VERSION ""

NS_ :

BS_:

BU_:

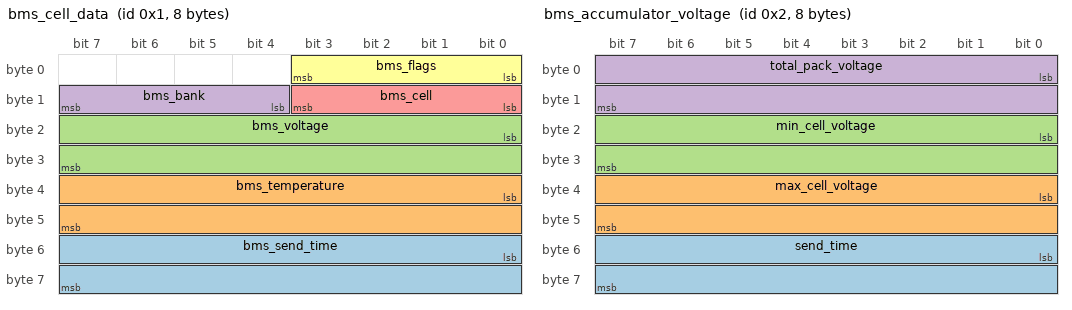
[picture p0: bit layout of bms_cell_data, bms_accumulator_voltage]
BO_ 1 bms_cell_data: 8 Vector__XXX
 SG_ bms_send_time : 48|16@1+ (1,0) [0|0] "" Vector__XXX
 SG_ bms_temperature : 32|16@1- (1,0) [0|0] "" Vector__XXX
 SG_ bms_voltage : 16|16@1+ (1,0) [0|0] "" Vector__XXX
 SG_ bms_bank : 12|4@1+ (1,0) [0|0] "" Vector__XXX
 SG_ bms_cell : 8|4@1+ (1,0) [0|0] "" Vector__XXX
 SG_ bms_flags : 0|4@1+ (1,0) [0|0] "" Vector__XXX

BO_ 2 bms_accumulator_voltage: 8 Vector__XXX
 SG_ send_time : 48|16@1+ (1,0) [0|0] "" Vector__XXX
 SG_ max_cell_voltage : 32|16@1+ (1,0) [0|0] "" Vector__XXX
 SG_ min_cell_voltage : 16|16@1+ (1,0) [0|0] "" Vector__XXX
 SG_ total_pack_voltage : 0|16@1+ (1,0) [0|0] "" Vector__XXX

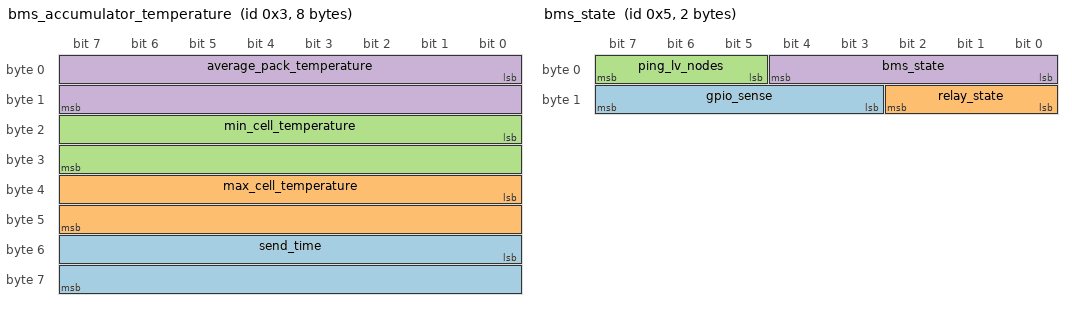
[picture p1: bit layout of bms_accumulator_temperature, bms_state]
BO_ 3 bms_accumulator_temperature: 8 Vector__XXX
 SG_ send_time : 48|16@1+ (1,0) [0|0] "" Vector__XXX
 SG_ max_cell_temperature : 32|16@1- (1,0) [0|0] "" Vector__XXX
 SG_ min_cell_temperature : 16|16@1- (1,0) [0|0] "" Vector__XXX
 SG_ average_pack_temperature : 0|16@1- (1,0) [0|0] "" Vector__XXX

BO_ 4 accumulator_faults: 1 Vector__XXX
 SG_ imd_fault : 1|1@1+ (1,0) [0|0] "" Vector__XXX
 SG_ bms_fault : 0|1@1+ (1,0) [0|0] "" Vector__XXX

BO_ 5 bms_state: 2 Vector__XXX
 SG_ gpio_sense : 11|5@1+ (1,0) [0|0] "" Vector__XXX
 SG_ relay_state : 8|3@1+ (1,0) [0|0] "" Vector__XXX
 SG_ ping_lv_nodes : 5|3@1+ (1,0) [0|0] "" Vector__XXX
 SG_ bms_state : 0|5@1+ (1,0) [0|0] "" Vector__XXX

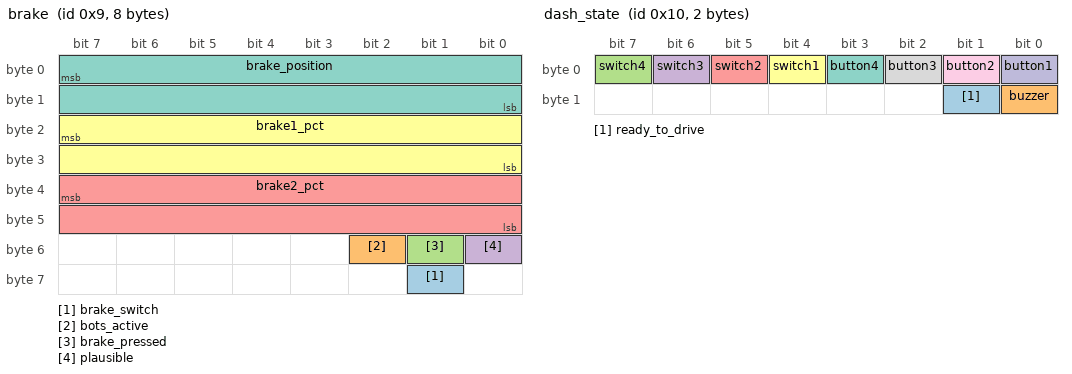
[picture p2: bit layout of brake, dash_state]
BO_ 9 brake: 8 Vector__XXX
 SG_ brake_switch : 57|1@1+ (1,0) [0|0] "" Vector__XXX
 SG_ bots_active : 50|1@1+ (1,0) [0|0] "" Vector__XXX
 SG_ brake_pressed : 49|1@1+ (1,0) [0|0] "" Vector__XXX
 SG_ plausible : 48|1@1+ (1,0) [0|0] "" Vector__XXX
 SG_ brake2_pct : 39|16@0+ (0.01,0) [0|0] "%" Vector__XXX
 SG_ brake1_pct : 23|16@0+ (0.01,0) [0|0] "%" Vector__XXX
 SG_ brake_position : 7|16@0+ (0.01,0) [0|0] "%" Vector__XXX

BO_ 10 bspd_state: 1 Vector__XXX
 SG_ bspd_state : 0|8@1+ (1,0) [0|0] "" Vector__XXX

BO_ 11 res_state: 2 Vector__XXX
 SG_ res_state : 0|8@1+ (1,0) [0|0] "" Vector__XXX

BO_ 16 dash_state: 2 Vector__XXX
 SG_ ready_to_drive : 9|1@1+ (1,0) [0|0] "" Vector__XXX
 SG_ buzzer : 8|1@1+ (1,0) [0|0] "" Vector__XXX
 SG_ switch4 : 7|1@1+ (1,0) [0|0] "" Vector__XXX
 SG_ switch3 : 6|1@1+ (1,0) [0|0] "" Vector__XXX
 SG_ switch2 : 5|1@1+ (1,0) [0|0] "" Vector__XXX
 SG_ switch1 : 4|1@1+ (1,0) [0|0] "" Vector__XXX
 SG_ button4 : 3|1@1+ (1,0) [0|0] "" Vector__XXX
 SG_ button3 : 2|1@1+ (1,0) [0|0] "" Vector__XXX
 SG_ button2 : 1|1@1+ (1,0) [0|0] "" Vector__XXX
 SG_ button1 : 0|1@1+ (1,0) [0|0] "" Vector__XXX

BO_ 22 lvpdb_lv_24v_bus_and_12v_bus_vol: 4 Vector__XXX
 SG_ lv_12v_voltage : 16|16@1+ (1,0) [0|0] "" Vector__XXX
 SG_ lv_24v_voltage : 0|16@1+ (1,0) [0|0] "" Vector__XXX

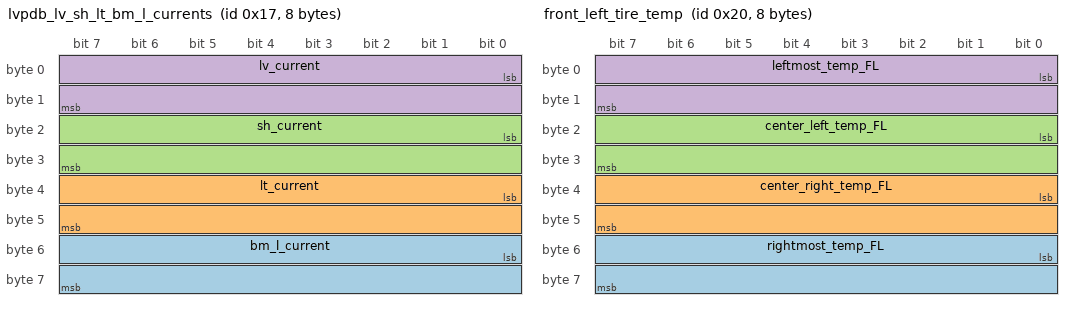
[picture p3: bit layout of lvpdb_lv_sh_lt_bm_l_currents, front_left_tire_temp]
BO_ 23 lvpdb_lv_sh_lt_bm_l_currents: 8 Vector__XXX
 SG_ bm_l_current : 48|16@1+ (1,0) [0|0] "" Vector__XXX
 SG_ lt_current : 32|16@1+ (1,0) [0|0] "" Vector__XXX
 SG_ sh_current : 16|16@1+ (1,0) [0|0] "" Vector__XXX
 SG_ lv_current : 0|16@1+ (1,0) [0|0] "" Vector__XXX

BO_ 24 lvpdb_sm_af1_af2_cp_rf_currents: 8 Vector__XXX
 SG_ cp_rf_current : 32|16@1+ (1,0) [0|0] "" Vector__XXX
 SG_ af1_af2_current : 16|16@1+ (1,0) [0|0] "" Vector__XXX
 SG_ sm_current : 0|16@1+ (1,0) [0|0] "" Vector__XXX

BO_ 30 linear_potentiometer_front: 4 Vector__XXX
 SG_ linear_potentiometer_2_front : 16|16@1+ (1,0) [0|0] "" Vector__XXX
 SG_ linear_potentiometer_1_front : 0|16@1+ (1,0) [0|0] "" Vector__XXX

BO_ 31 linear_potentiometer_rear: 4 Vector__XXX
 SG_ linear_potentiometer_2_rear : 16|16@1+ (1,0) [0|0] "" Vector__XXX
 SG_ linear_potentiometer_1_rear : 0|16@1+ (1,0) [0|0] "" Vector__XXX

BO_ 32 front_left_tire_temp: 8 Vector__XXX
 SG_ rightmost_temp_FL : 48|16@1+ (1,0) [0|0] "" Vector__XXX
 SG_ center_right_temp_FL : 32|16@1+ (1,0) [0|0] "" Vector__XXX
 SG_ center_left_temp_FL : 16|16@1+ (1,0) [0|0] "" Vector__XXX
 SG_ leftmost_temp_FL : 0|16@1+ (1,0) [0|0] "" Vector__XXX

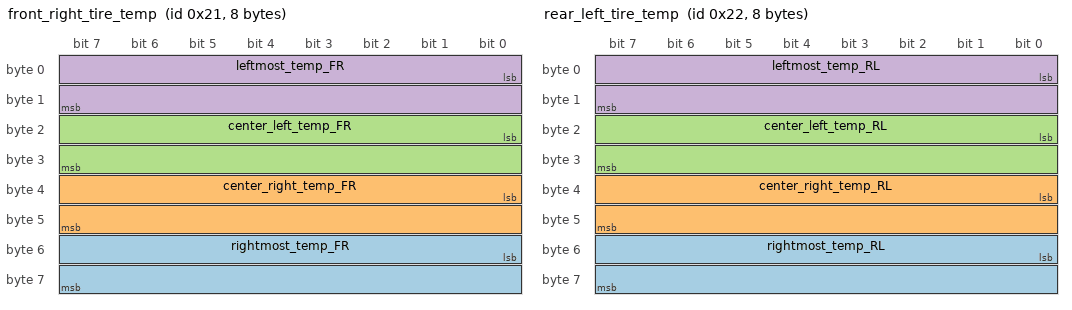
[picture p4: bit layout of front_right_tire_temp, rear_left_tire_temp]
BO_ 33 front_right_tire_temp: 8 Vector__XXX
 SG_ rightmost_temp_FR : 48|16@1+ (1,0) [0|0] "" Vector__XXX
 SG_ center_right_temp_FR : 32|16@1+ (1,0) [0|0] "" Vector__XXX
 SG_ center_left_temp_FR : 16|16@1+ (1,0) [0|0] "" Vector__XXX
 SG_ leftmost_temp_FR : 0|16@1+ (1,0) [0|0] "" Vector__XXX

BO_ 34 rear_left_tire_temp: 8 Vector__XXX
 SG_ rightmost_temp_RL : 48|16@1+ (1,0) [0|0] "" Vector__XXX
 SG_ center_right_temp_RL : 32|16@1+ (1,0) [0|0] "" Vector__XXX
 SG_ center_left_temp_RL : 16|16@1+ (1,0) [0|0] "" Vector__XXX
 SG_ leftmost_temp_RL : 0|16@1+ (1,0) [0|0] "" Vector__XXX

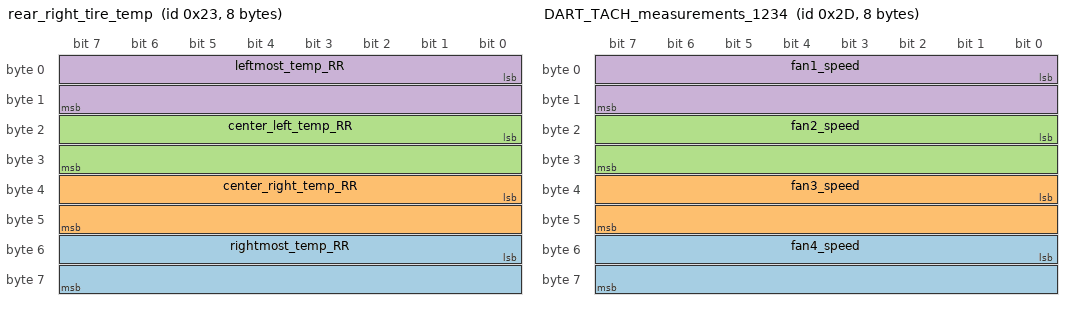
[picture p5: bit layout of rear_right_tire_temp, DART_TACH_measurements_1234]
BO_ 35 rear_right_tire_temp: 8 Vector__XXX
 SG_ rightmost_temp_RR : 48|16@1+ (1,0) [0|0] "" Vector__XXX
 SG_ center_right_temp_RR : 32|16@1+ (1,0) [0|0] "" Vector__XXX
 SG_ center_left_temp_RR : 16|16@1+ (1,0) [0|0] "" Vector__XXX
 SG_ leftmost_temp_RR : 0|16@1+ (1,0) [0|0] "" Vector__XXX

BO_ 36 wss_front_data: 8 Vector__XXX
 SG_ wss_dir_flags : 32|8@1+ (1,0) [0|0] "" Vector__XXX
 SG_ wss_right_front : 16|16@1+ (0.01,0) [0|0] "mph" Vector__XXX
 SG_ wss_left_front : 0|16@1+ (0.01,0) [0|0] "mph" Vector__XXX

BO_ 37 wss_rear_data: 8 Vector__XXX
 SG_ wss_dir_flags : 32|8@1+ (1,0) [0|0] "" Vector__XXX
 SG_ wss_right_rear : 16|16@1+ (0.01,0) [0|0] "mph" Vector__XXX
 SG_ wss_left_rear : 0|16@1+ (0.01,0) [0|0] "mph" Vector__XXX

BO_ 38 imu_acceleration_data: 6 Vector__XXX
 SG_ acceleration_z : 32|16@1- (0.061,0) [0|0] "mg" Vector__XXX
 SG_ acceleration_y : 16|16@1- (0.061,0) [0|0] "mg" Vector__XXX
 SG_ acceleration_x : 0|16@1- (0.061,0) [0|0] "mg" Vector__XXX

BO_ 39 imu_acceleration_data_rear: 6 Vector__XXX
 SG_ acceleration_z : 32|16@1- (0.061,0) [0|0] "mg" Vector__XXX
 SG_ acceleration_y : 16|16@1- (0.061,0) [0|0] "mg" Vector__XXX
 SG_ acceleration_x : 0|16@1- (0.061,0) [0|0] "mg" Vector__XXX

BO_ 40 imu_gyro_data: 6 Vector__XXX
 SG_ gyro_z : 32|16@1- (70,0) [0|0] "mdps" Vector__XXX
 SG_ gyro_y : 16|16@1- (70,0) [0|0] "mdps" Vector__XXX
 SG_ gyro_x : 0|16@1- (70,0) [0|0] "mdps" Vector__XXX

BO_ 41 imu_gyro_data_rear: 6 Vector__XXX
 SG_ gyro_z : 32|16@1- (70,0) [0|0] "mdps" Vector__XXX
 SG_ gyro_y : 16|16@1- (70,0) [0|0] "mdps" Vector__XXX
 SG_ gyro_x : 0|16@1- (70,0) [0|0] "mdps" Vector__XXX

BO_ 42 magnetometer_data: 6 Vector__XXX
 SG_ magnetometer_z : 32|16@1- (0.5844,0) [0|0] "mG" Vector__XXX
 SG_ magnetometer_y : 16|16@1- (0.5844,0) [0|0] "mG" Vector__XXX
 SG_ magnetometer_x : 0|16@1- (0.5844,0) [0|0] "mG" Vector__XXX

BO_ 43 magnetometer_data_rear: 6 Vector__XXX
 SG_ magnetometer_z : 32|16@1- (0.5844,0) [0|0] "mG" Vector__XXX
 SG_ magnetometer_y : 16|16@1- (0.5844,0) [0|0] "mG" Vector__XXX
 SG_ magnetometer_x : 0|16@1- (0.5844,0) [0|0] "mG" Vector__XXX

BO_ 45 DART_TACH_measurements_1234: 8 Vector__XXX
 SG_ fan4_speed : 48|16@1+ (1,0) [0|0] "" Vector__XXX
 SG_ fan3_speed : 32|16@1+ (1,0) [0|0] "" Vector__XXX
 SG_ fan2_speed : 16|16@1+ (1,0) [0|0] "" Vector__XXX
 SG_ fan1_speed : 0|16@1+ (1,0) [0|0] "" Vector__XXX

BO_ 46 DART_TACH_measurements_5: 2 Vector__XXX
 SG_ fan5_speed : 0|16@1+ (1,0) [0|0] "" Vector__XXX

BO_ 52 bbb_tps: 4 Vector__XXX
 SG_ current : 16|16@1+ (1,0) [0|0] "" Vector__XXX
 SG_ voltage : 0|16@1+ (1,0) [0|0] "" Vector__XXX

BO_ 53 pcu_tps: 4 Vector__XXX
 SG_ current : 16|16@1+ (1,0) [0|0] "mA" Vector__XXX
 SG_ voltage : 0|16@1+ (1,0) [0|0] "mV" Vector__XXX

BO_ 54 dash_tps: 4 Vector__XXX
 SG_ current : 16|16@1+ (1,0) [0|0] "" Vector__XXX
 SG_ voltage : 0|16@1+ (1,0) [0|0] "" Vector__XXX

BO_ 55 dcu_tps: 4 Vector__XXX
 SG_ current : 16|16@1+ (1,0) [0|0] "" Vector__XXX
 SG_ voltage : 0|16@1+ (1,0) [0|0] "" Vector__XXX

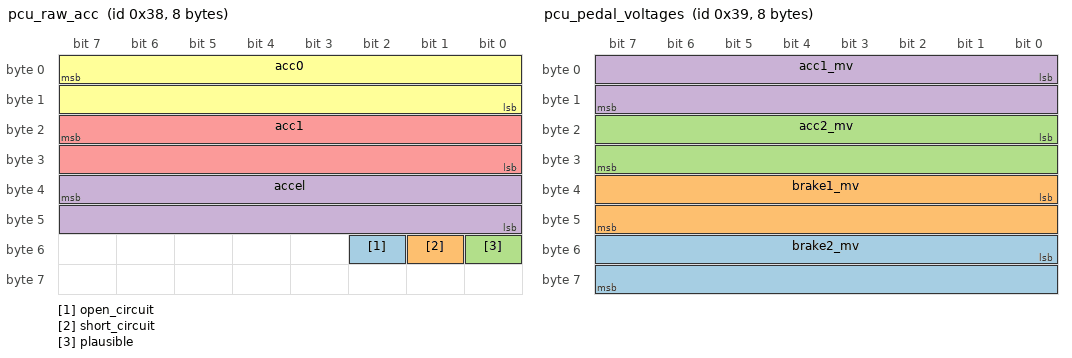
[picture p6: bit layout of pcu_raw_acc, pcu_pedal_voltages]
BO_ 56 pcu_raw_acc: 8 Vector__XXX
 SG_ open_circuit : 50|1@1+ (1,0) [0|0] "" Vector__XXX
 SG_ short_circuit : 49|1@1+ (1,0) [0|0] "" Vector__XXX
 SG_ plausible : 48|1@1+ (1,0) [0|0] "" Vector__XXX
 SG_ accel : 39|16@0+ (0.01,0) [0|0] "%" Vector__XXX
 SG_ acc1 : 23|16@0+ (0.01,0) [0|0] "%" Vector__XXX
 SG_ acc0 : 7|16@0+ (0.01,0) [0|0] "%" Vector__XXX

BO_ 57 pcu_pedal_voltages: 8 Vector__XXX
 SG_ brake2_mv : 48|16@1+ (1,0) [0|0] "mV" Vector__XXX
 SG_ brake1_mv : 32|16@1+ (1,0) [0|0] "mV" Vector__XXX
 SG_ acc2_mv : 16|16@1+ (1,0) [0|0] "mV" Vector__XXX
 SG_ acc1_mv : 0|16@1+ (1,0) [0|0] "mV" Vector__XXX

BO_ 64 gps_pos_data: 8 Vector__XXX
 SG_ longitude : 32|32@1- (1e-07,0) [0|0] "deg" Vector__XXX
 SG_ latitude : 0|32@1- (1e-07,0) [0|0] "deg" Vector__XXX

BO_ 65 gps_altitude_data: 8 Vector__XXX
 SG_ vdop : 48|16@1+ (0.01,0) [0|0] "" Vector__XXX
 SG_ hdop : 32|16@1+ (0.01,0) [0|0] "" Vector__XXX
 SG_ altitude : 0|32@1- (0.01,0) [0|0] "m" Vector__XXX

BO_ 66 gps_motion_data: 4 Vector__XXX
 SG_ course : 16|16@1+ (0.01,0) [0|0] "deg" Vector__XXX
 SG_ speed : 0|16@1+ (0.01,0) [0|0] "km/h" Vector__XXX

BO_ 67 gps_time_data: 3 Vector__XXX
 SG_ seconds : 16|8@1- (1,0) [0|0] "" Vector__XXX
 SG_ minutes : 8|8@1- (1,0) [0|0] "" Vector__XXX
 SG_ hours : 0|8@1- (1,0) [0|0] "" Vector__XXX

BO_ 68 gps_date_data: 3 Vector__XXX
 SG_ year : 16|8@1- (1,0) [0|0] "" Vector__XXX
 SG_ month : 8|8@1- (1,0) [0|0] "" Vector__XXX
 SG_ day : 0|8@1- (1,0) [0|0] "" Vector__XXX

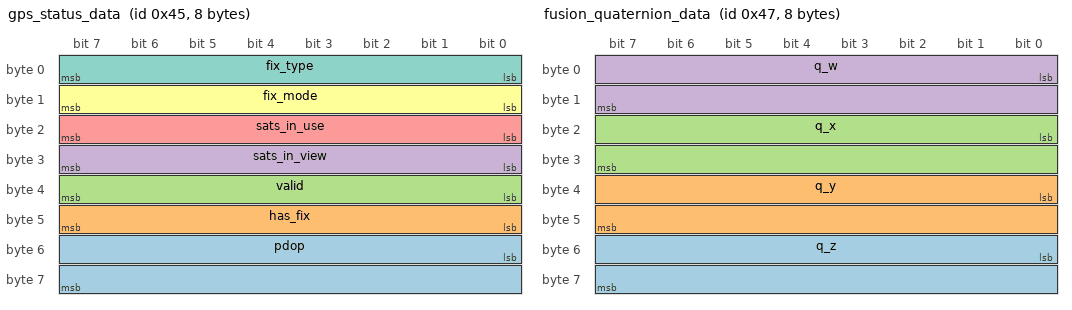
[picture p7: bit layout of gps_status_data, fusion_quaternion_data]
BO_ 69 gps_status_data: 8 Vector__XXX
 SG_ pdop : 48|16@1+ (0.01,0) [0|0] "" Vector__XXX
 SG_ has_fix : 40|8@1+ (1,0) [0|0] "" Vector__XXX
 SG_ valid : 32|8@1+ (1,0) [0|0] "" Vector__XXX
 SG_ sats_in_view : 24|8@1+ (1,0) [0|0] "" Vector__XXX
 SG_ sats_in_use : 16|8@1+ (1,0) [0|0] "" Vector__XXX
 SG_ fix_mode : 8|8@1+ (1,0) [0|0] "" Vector__XXX
 SG_ fix_type : 0|8@1+ (1,0) [0|0] "" Vector__XXX

BO_ 71 fusion_quaternion_data: 8 Vector__XXX
 SG_ q_z : 48|16@1- (3.051850947599719e-05,0) [0|0] "" Vector__XXX
 SG_ q_y : 32|16@1- (3.051850947599719e-05,0) [0|0] "" Vector__XXX
 SG_ q_x : 16|16@1- (3.051850947599719e-05,0) [0|0] "" Vector__XXX
 SG_ q_w : 0|16@1- (3.051850947599719e-05,0) [0|0] "" Vector__XXX

BO_ 72 fusion_euler_data: 6 Vector__XXX
 SG_ yaw : 32|16@1- (0.01,0) [0|0] "deg" Vector__XXX
 SG_ pitch : 16|16@1- (0.01,0) [0|0] "deg" Vector__XXX
 SG_ roll : 0|16@1- (0.01,0) [0|0] "deg" Vector__XXX

BO_ 73 fusion_linear_accel_data: 6 Vector__XXX
 SG_ lin_accel_z : 32|16@1- (1,0) [0|0] "mg" Vector__XXX
 SG_ lin_accel_y : 16|16@1- (1,0) [0|0] "mg" Vector__XXX
 SG_ lin_accel_x : 0|16@1- (1,0) [0|0] "mg" Vector__XXX

BO_ 74 fusion_earth_accel_data: 6 Vector__XXX
 SG_ earth_accel_z : 32|16@1- (1,0) [0|0] "mg" Vector__XXX
 SG_ earth_accel_y : 16|16@1- (1,0) [0|0] "mg" Vector__XXX
 SG_ earth_accel_x : 0|16@1- (1,0) [0|0] "mg" Vector__XXX

BO_ 75 fusion_status_data: 3 Vector__XXX
 SG_ mag_error : 16|8@1+ (0.1,0) [0|0] "deg" Vector__XXX
 SG_ accel_error : 8|8@1+ (0.1,0) [0|0] "deg" Vector__XXX
 SG_ flags : 0|8@1+ (1,0) [0|0] "" Vector__XXX

BO_ 76 sensor_temps_data: 4 Vector__XXX
 SG_ mag_temp : 16|16@1- (0.01,0) [0|0] "degC" Vector__XXX
 SG_ imu_temp : 0|16@1- (0.01,0) [0|0] "degC" Vector__XXX

BO_ 77 sensor_temps_data_rear: 4 Vector__XXX
 SG_ mag_temp : 16|16@1- (0.01,0) [0|0] "degC" Vector__XXX
 SG_ imu_temp : 0|16@1- (0.01,0) [0|0] "degC" Vector__XXX

BO_ 78 steer_angle_data: 5 Vector__XXX
 SG_ agc : 32|8@1+ (1,0) [0|0] "" Vector__XXX
 SG_ raw_angle : 16|16@1+ (1,0) [0|0] "" Vector__XXX
 SG_ angle : 0|16@1+ (1,0) [0|0] "" Vector__XXX

BO_ 79 steer_status_data: 3 Vector__XXX
 SG_ magnitude : 8|16@1+ (1,0) [0|0] "" Vector__XXX
 SG_ status : 0|8@1+ (1,0) [0|0] "" Vector__XXX

BO_ 80 gps_pos_data_rear: 8 Vector__XXX
 SG_ longitude : 32|32@1- (1e-07,0) [0|0] "deg" Vector__XXX
 SG_ latitude : 0|32@1- (1e-07,0) [0|0] "deg" Vector__XXX

BO_ 81 gps_altitude_data_rear: 8 Vector__XXX
 SG_ vdop : 48|16@1+ (0.01,0) [0|0] "" Vector__XXX
 SG_ hdop : 32|16@1+ (0.01,0) [0|0] "" Vector__XXX
 SG_ altitude : 0|32@1- (0.01,0) [0|0] "m" Vector__XXX

BO_ 82 gps_motion_data_rear: 4 Vector__XXX
 SG_ course : 16|16@1+ (0.01,0) [0|0] "deg" Vector__XXX
 SG_ speed : 0|16@1+ (0.01,0) [0|0] "km/h" Vector__XXX

BO_ 83 gps_time_data_rear: 3 Vector__XXX
 SG_ seconds : 16|8@1- (1,0) [0|0] "" Vector__XXX
 SG_ minutes : 8|8@1- (1,0) [0|0] "" Vector__XXX
 SG_ hours : 0|8@1- (1,0) [0|0] "" Vector__XXX

BO_ 84 gps_date_data_rear: 3 Vector__XXX
 SG_ year : 16|8@1- (1,0) [0|0] "" Vector__XXX
 SG_ month : 8|8@1- (1,0) [0|0] "" Vector__XXX
 SG_ day : 0|8@1- (1,0) [0|0] "" Vector__XXX

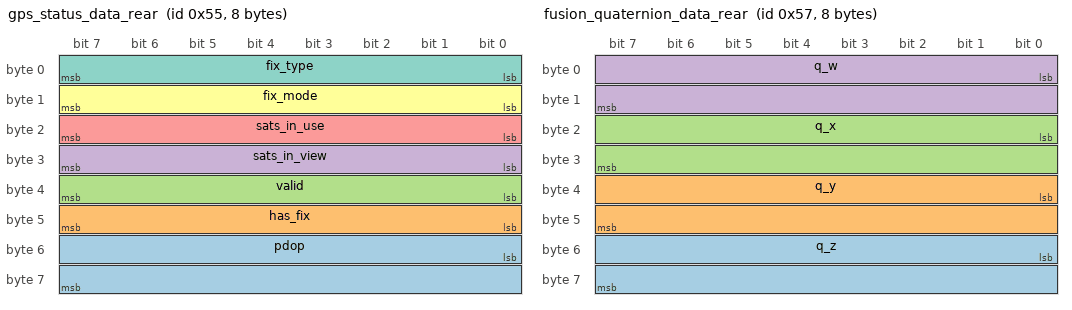
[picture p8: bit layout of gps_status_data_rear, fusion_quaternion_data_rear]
BO_ 85 gps_status_data_rear: 8 Vector__XXX
 SG_ pdop : 48|16@1+ (0.01,0) [0|0] "" Vector__XXX
 SG_ has_fix : 40|8@1+ (1,0) [0|0] "" Vector__XXX
 SG_ valid : 32|8@1+ (1,0) [0|0] "" Vector__XXX
 SG_ sats_in_view : 24|8@1+ (1,0) [0|0] "" Vector__XXX
 SG_ sats_in_use : 16|8@1+ (1,0) [0|0] "" Vector__XXX
 SG_ fix_mode : 8|8@1+ (1,0) [0|0] "" Vector__XXX
 SG_ fix_type : 0|8@1+ (1,0) [0|0] "" Vector__XXX

BO_ 87 fusion_quaternion_data_rear: 8 Vector__XXX
 SG_ q_z : 48|16@1- (3.051850947599719e-05,0) [0|0] "" Vector__XXX
 SG_ q_y : 32|16@1- (3.051850947599719e-05,0) [0|0] "" Vector__XXX
 SG_ q_x : 16|16@1- (3.051850947599719e-05,0) [0|0] "" Vector__XXX
 SG_ q_w : 0|16@1- (3.051850947599719e-05,0) [0|0] "" Vector__XXX

BO_ 88 fusion_euler_data_rear: 6 Vector__XXX
 SG_ yaw : 32|16@1- (0.01,0) [0|0] "deg" Vector__XXX
 SG_ pitch : 16|16@1- (0.01,0) [0|0] "deg" Vector__XXX
 SG_ roll : 0|16@1- (0.01,0) [0|0] "deg" Vector__XXX

BO_ 89 fusion_linear_accel_data_rear: 6 Vector__XXX
 SG_ lin_accel_z : 32|16@1- (1,0) [0|0] "mg" Vector__XXX
 SG_ lin_accel_y : 16|16@1- (1,0) [0|0] "mg" Vector__XXX
 SG_ lin_accel_x : 0|16@1- (1,0) [0|0] "mg" Vector__XXX

BO_ 90 fusion_earth_accel_data_rear: 6 Vector__XXX
 SG_ earth_accel_z : 32|16@1- (1,0) [0|0] "mg" Vector__XXX
 SG_ earth_accel_y : 16|16@1- (1,0) [0|0] "mg" Vector__XXX
 SG_ earth_accel_x : 0|16@1- (1,0) [0|0] "mg" Vector__XXX

BO_ 91 fusion_status_data_rear: 3 Vector__XXX
 SG_ mag_error : 16|8@1+ (0.1,0) [0|0] "deg" Vector__XXX
 SG_ accel_error : 8|8@1+ (0.1,0) [0|0] "deg" Vector__XXX
 SG_ flags : 0|8@1+ (1,0) [0|0] "" Vector__XXX

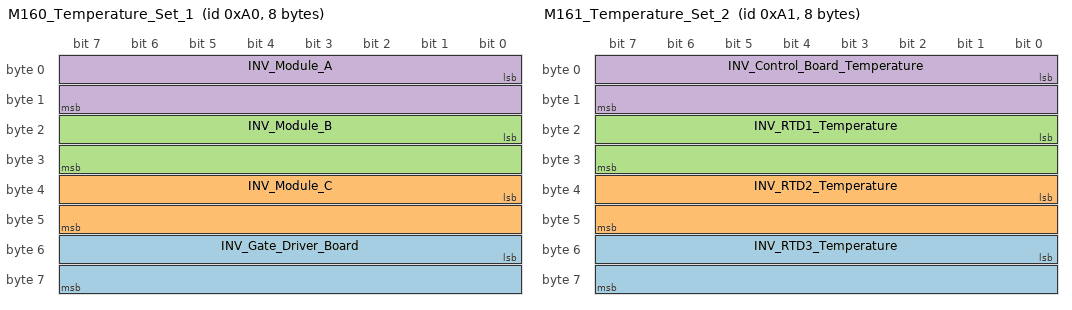
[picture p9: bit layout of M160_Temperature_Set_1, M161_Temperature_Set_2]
BO_ 160 M160_Temperature_Set_1: 8 INV
 SG_ INV_Gate_Driver_Board : 48|16@1- (0.1,0) [-3276.8|3276.7] "temperature:C" Vector__XXX
 SG_ INV_Module_C : 32|16@1- (0.1,0) [-3276.8|3276.7] "temperature:C" Vector__XXX
 SG_ INV_Module_B : 16|16@1- (0.1,0) [-3276.8|3276.7] "temperature:C" Vector__XXX
 SG_ INV_Module_A : 0|16@1- (0.1,0) [-3276.8|3276.7] "temperature:C" Vector__XXX

BO_ 161 M161_Temperature_Set_2: 8 INV
 SG_ INV_RTD3_Temperature : 48|16@1- (0.1,0) [-3276.8|3276.7] "temperature:C" Vector__XXX
 SG_ INV_RTD2_Temperature : 32|16@1- (0.1,0) [-3276.8|3276.7] "temperature:C" Vector__XXX
 SG_ INV_RTD1_Temperature : 16|16@1- (0.1,0) [-3276.8|3276.7] "temperature:C" Vector__XXX
 SG_ INV_Control_Board_Temperature : 0|16@1- (0.1,0) [-3276.8|3276.7] "temperature:C" Vector__XXX

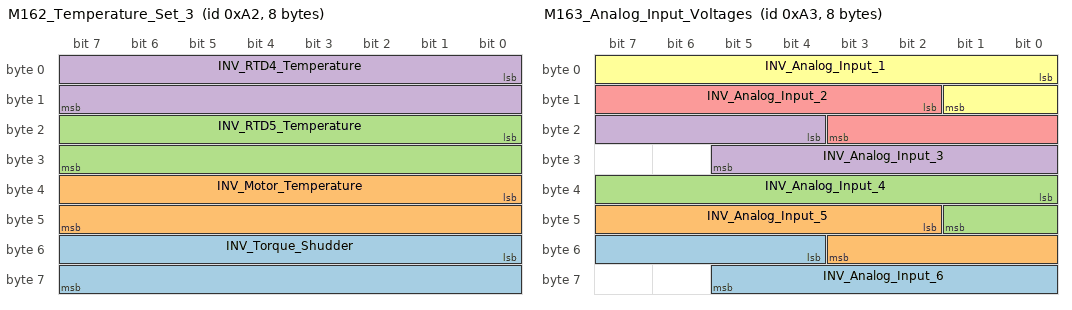
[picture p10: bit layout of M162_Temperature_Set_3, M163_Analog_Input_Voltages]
BO_ 162 M162_Temperature_Set_3: 8 INV
 SG_ INV_Torque_Shudder : 48|16@1- (0.1,0) [-3276.8|3276.7] "torque:N.m" Vector__XXX
 SG_ INV_Motor_Temperature : 32|16@1- (0.1,0) [-3276.8|3276.7] "temperature:C" Vector__XXX
 SG_ INV_RTD5_Temperature : 16|16@1- (0.1,0) [-3276.8|3276.7] "temperature:C" Vector__XXX
 SG_ INV_RTD4_Temperature : 0|16@1- (0.1,0) [-3276.8|3276.7] "temperature:C" Vector__XXX

BO_ 163 M163_Analog_Input_Voltages: 8 INV
 SG_ INV_Analog_Input_6 : 52|10@1+ (0.01,0) [0|10.23] "voltage:V" Vector__XXX
 SG_ INV_Analog_Input_5 : 42|10@1+ (0.01,0) [0|10.23] "voltage:V" Vector__XXX
 SG_ INV_Analog_Input_4 : 32|10@1+ (0.01,0) [0|10.23] "voltage:V" Vector__XXX
 SG_ INV_Analog_Input_3 : 20|10@1+ (0.01,0) [0|10.23] "voltage:V" Vector__XXX
 SG_ INV_Analog_Input_2 : 10|10@1+ (0.01,0) [0|10.23] "voltage:V" Vector__XXX
 SG_ INV_Analog_Input_1 : 0|10@1+ (0.01,0) [0|10.23] "voltage:V" Vector__XXX

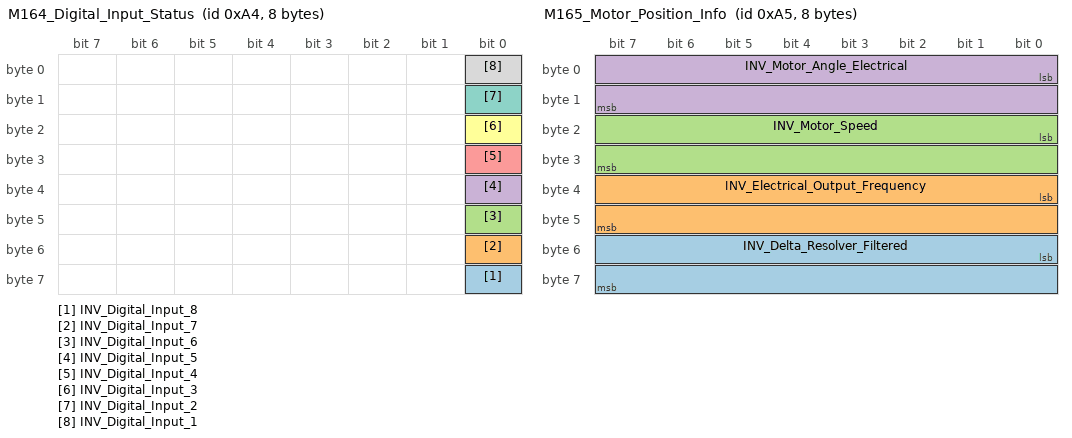
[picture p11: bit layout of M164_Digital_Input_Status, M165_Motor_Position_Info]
BO_ 164 M164_Digital_Input_Status: 8 INV
 SG_ INV_Digital_Input_8 : 56|1@1+ (1,0) [0|1] "" Vector__XXX
 SG_ INV_Digital_Input_7 : 48|1@1+ (1,0) [0|1] "" Vector__XXX
 SG_ INV_Digital_Input_6 : 40|1@1+ (1,0) [0|1] "" Vector__XXX
 SG_ INV_Digital_Input_5 : 32|1@1+ (1,0) [0|1] "" Vector__XXX
 SG_ INV_Digital_Input_4 : 24|1@1+ (1,0) [0|1] "" Vector__XXX
 SG_ INV_Digital_Input_3 : 16|1@1+ (1,0) [0|1] "" Vector__XXX
 SG_ INV_Digital_Input_2 : 8|1@1+ (1,0) [0|1] "" Vector__XXX
 SG_ INV_Digital_Input_1 : 0|1@1+ (1,0) [0|1] "" Vector__XXX

BO_ 165 M165_Motor_Position_Info: 8 INV
 SG_ INV_Delta_Resolver_Filtered : 48|16@1- (0.1,0) [-3276.8|3276.7] "angle:deg" Vector__XXX
 SG_ INV_Electrical_Output_Frequency : 32|16@1- (0.1,0) [-3276.8|3276.7] "frequency:Hz" Vector__XXX
 SG_ INV_Motor_Speed : 16|16@1- (1,0) [-32768|32767] "angular_speed:rpm" Vector__XXX
 SG_ INV_Motor_Angle_Electrical : 0|16@1+ (0.1,0) [0|6553.5] "angle:deg" Vector__XXX

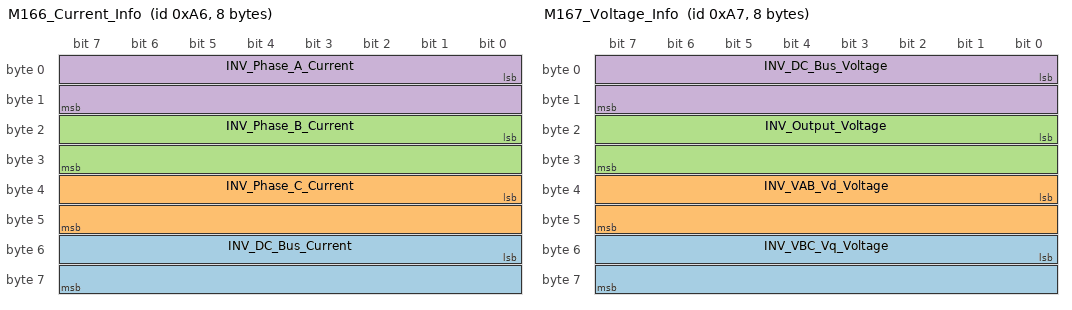
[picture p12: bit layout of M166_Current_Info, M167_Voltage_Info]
BO_ 166 M166_Current_Info: 8 INV
 SG_ INV_DC_Bus_Current : 48|16@1- (0.1,0) [-3276.8|3276.7] "current:A" Vector__XXX
 SG_ INV_Phase_C_Current : 32|16@1- (0.1,0) [-3276.8|3276.7] "current:A" Vector__XXX
 SG_ INV_Phase_B_Current : 16|16@1- (0.1,0) [-3276.8|3276.7] "current:A" Vector__XXX
 SG_ INV_Phase_A_Current : 0|16@1- (0.1,0) [-3276.8|3276.7] "current:A" Vector__XXX

BO_ 167 M167_Voltage_Info: 8 INV
 SG_ INV_VBC_Vq_Voltage : 48|16@1- (0.1,0) [-3276.8|3276.7] "voltage:V" Vector__XXX
 SG_ INV_VAB_Vd_Voltage : 32|16@1- (0.1,0) [-3276.8|3276.7] "voltage:V" Vector__XXX
 SG_ INV_Output_Voltage : 16|16@1- (0.1,0) [-3276.8|3276.7] "voltage:V" Vector__XXX
 SG_ INV_DC_Bus_Voltage : 0|16@1- (0.1,0) [-3276.8|3276.7] "voltage:V" Vector__XXX

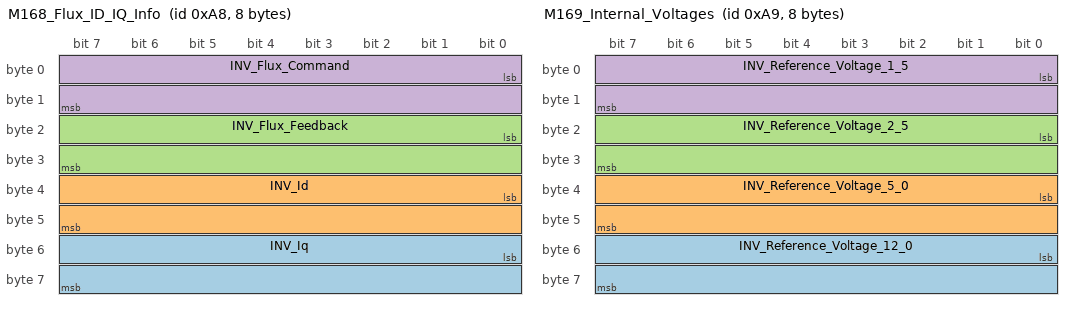
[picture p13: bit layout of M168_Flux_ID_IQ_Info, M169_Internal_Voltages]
BO_ 168 M168_Flux_ID_IQ_Info: 8 INV
 SG_ INV_Iq : 48|16@1- (0.1,0) [-3276.8|3276.7] "current:A" Vector__XXX
 SG_ INV_Id : 32|16@1- (0.1,0) [-3276.8|3276.7] "current:A" Vector__XXX
 SG_ INV_Flux_Feedback : 16|16@1- (0.001,0) [-32.768|32.767] "flux:Wb" Vector__XXX
 SG_ INV_Flux_Command : 0|16@1- (0.001,0) [-32.768|32.767] "flux:Wb" Vector__XXX

BO_ 169 M169_Internal_Voltages: 8 INV
 SG_ INV_Reference_Voltage_12_0 : 48|16@1- (0.01,0) [-327.68|327.67] "voltage:V" Vector__XXX
 SG_ INV_Reference_Voltage_5_0 : 32|16@1- (0.01,0) [-327.68|327.67] "voltage:V" Vector__XXX
 SG_ INV_Reference_Voltage_2_5 : 16|16@1- (0.01,0) [-327.68|327.67] "voltage:V" Vector__XXX
 SG_ INV_Reference_Voltage_1_5 : 0|16@1- (0.01,0) [-327.68|327.67] "voltage:V" Vector__XXX

BO_ 170 M170_Internal_States: 8 INV
 SG_ INV_Low_Speed_Limiting : 61|1@1+ (1,0) [0|1] "" Vector__XXX
 SG_ INV_Max_Speed_Limiting : 59|1@1+ (1,0) [0|1] "" Vector__XXX
 SG_ INV_BMS_Torque_Limiting : 58|1@1+ (1,0) [0|1] "" Vector__XXX
 SG_ INV_BMS_Active : 57|1@1+ (1,0) [0|1] "" Vector__XXX
 SG_ INV_Direction_Command : 56|1@1+ (1,0) [0|1] "" Vector__XXX
 SG_ INV_Inverter_Enable_Lockout : 55|1@1+ (1,0) [0|1] "" Vector__XXX
 SG_ INV_Start_Mode_Active : 54|1@1+ (1,0) [0|1] "" Vector__XXX
 SG_ INV_Inverter_Enable_State : 48|1@1+ (1,0) [0|1] "" Vector__XXX
 SG_ INV_Rolling_Counter : 44|4@1+ (1,0) [0|15] "" Vector__XXX
 SG_ INV_Inverter_Command_Mode : 40|1@1+ (1,0) [0|1] "" Vector__XXX
 SG_ INV_Inverter_Discharge_State : 37|3@1+ (1,0) [0|7] "" Vector__XXX
 SG_ INV_Inverter_Run_Mode : 32|1@1+ (1,0) [0|1] "" Vector__XXX
 SG_ INV_Relay_6_Status : 29|1@1+ (1,0) [0|1] "" Vector__XXX
 SG_ INV_Relay_5_Status : 28|1@1+ (1,0) [0|1] "" Vector__XXX
 SG_ INV_Relay_4_Status : 27|1@1+ (1,0) [0|1] "" Vector__XXX
 SG_ INV_Relay_3_Status : 26|1@1+ (1,0) [0|1] "" Vector__XXX
 SG_ INV_Relay_2_Status : 25|1@1+ (1,0) [0|1] "" Vector__XXX
 SG_ INV_Relay_1_Status : 24|1@1+ (1,0) [0|1] "" Vector__XXX
 SG_ INV_Inverter_State : 16|8@1+ (1,0) [0|255] "" Vector__XXX
 SG_ INV_PWM_Frequency : 8|8@1+ (1,0) [0|255] "kHz" Vector__XXX
 SG_ INV_VSM_State : 0|8@1+ (1,0) [0|15] "" Vector__XXX

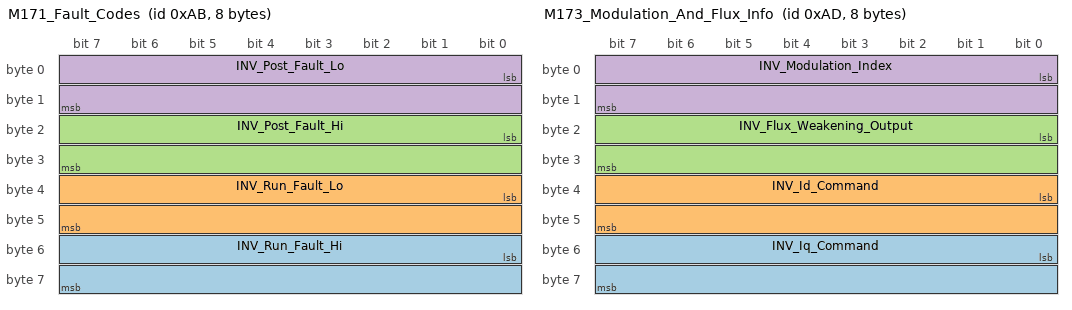
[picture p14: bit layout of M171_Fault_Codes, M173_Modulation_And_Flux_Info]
BO_ 171 M171_Fault_Codes: 8 INV
 SG_ INV_Run_Fault_Hi : 48|16@1+ (1,0) [0|65535] "" Vector__XXX
 SG_ INV_Run_Fault_Lo : 32|16@1+ (1,0) [0|65535] "" Vector__XXX
 SG_ INV_Post_Fault_Hi : 16|16@1+ (1,0) [0|65535] "" Vector__XXX
 SG_ INV_Post_Fault_Lo : 0|16@1+ (1,0) [0|65535] "" Vector__XXX

BO_ 172 M172_Torque_And_Timer_Info: 8 INV
 SG_ INV_Power_On_Timer : 32|32@1+ (0.003,0) [0|12884800] "time:sec" Vector__XXX
 SG_ INV_Torque_Feedback : 16|16@1- (0.1,0) [-3276.8|3276.7] "torque:N.m" Vector__XXX
 SG_ INV_Commanded_Torque : 0|16@1- (0.1,0) [-3276.8|3276.7] "torque:N.m" Vector__XXX

BO_ 173 M173_Modulation_And_Flux_Info: 8 INV
 SG_ INV_Iq_Command : 48|16@1- (0.1,0) [-3276.8|3276.7] "current:A" Vector__XXX
 SG_ INV_Id_Command : 32|16@1- (0.1,0) [-3276.8|3276.7] "current:A" Vector__XXX
 SG_ INV_Flux_Weakening_Output : 16|16@1- (0.1,0) [-3276.8|3276.7] "current:A" Vector__XXX
 SG_ INV_Modulation_Index : 0|16@1- (0.0001,0) [0|3.2767] "" Vector__XXX

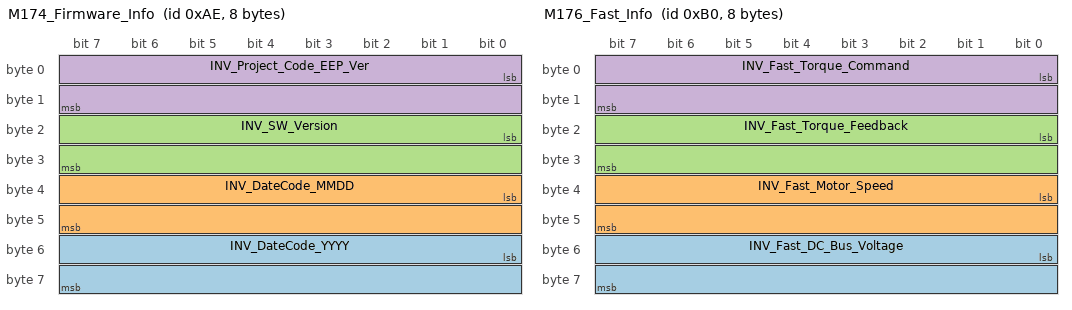
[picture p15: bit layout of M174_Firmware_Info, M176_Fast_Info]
BO_ 174 M174_Firmware_Info: 8 INV
 SG_ INV_DateCode_YYYY : 48|16@1+ (1,0) [0|65535] "" Vector__XXX
 SG_ INV_DateCode_MMDD : 32|16@1+ (1,0) [0|65535] "" Vector__XXX
 SG_ INV_SW_Version : 16|16@1+ (1,0) [0|65535] "" Vector__XXX
 SG_ INV_Project_Code_EEP_Ver : 0|16@1+ (1,0) [0|65535] "" Vector__XXX

BO_ 175 M175_Diag_Data_Message: 8 INV
 SG_ INV_Diag_Run_Faults_Hi m5 : 48|16@1+ (1,0) [0|65535] "" Vector__XXX
 SG_ INV_Diag_Vqs_Cmd m4 : 48|16@1- (0.1,0) [-1000|1000] "voltage:V" Vector__XXX
 SG_ INV_Diag_FW_Output m3 : 48|16@1- (0.1,0) [-2000|2000] "current:A" Vector__XXX
 SG_ INV_Diag_Iq_cmd m2 : 48|16@1- (0.1,0) [-2000|2000] "current:A" Vector__XXX
 SG_ INV_Diag_Ib m1 : 48|16@1- (0.1,0) [-2000|2000] "current:A" Vector__XXX
 SG_ INV_Diag_Sin m0 : 48|16@1- (1,0) [-5|5] "voltage:V" Vector__XXX
 SG_ INV_Diag_Run_Faults_Lo m5 : 32|16@1+ (1,0) [0|65535] "" Vector__XXX
 SG_ INV_Diag_Vd_Cmd m4 : 32|16@1- (0.1,0) [-1000|1000] "voltage:V" Vector__XXX
 SG_ INV_Diag_Mod_Index m3 : 32|16@1- (0.0001,0) [0|2] "" Vector__XXX
 SG_ INV_Diag_Vdc m2 : 32|16@1- (0.1,0) [0|1000] "voltage:V" Vector__XXX
 SG_ INV_Diag_Ia m1 : 32|16@1- (0.1,0) [-2000|2000] "current:A" Vector__XXX
 SG_ INV_Diag_Gamma_Observer m0 : 32|16@1- (0.1,0) [0|360] "angle:deg" Vector__XXX
 SG_ INV_Diag_12V m5 : 16|16@1+ (0.01,0) [0|36] "voltage:V" Vector__XXX
 SG_ INV_Diag_Vq_Cmd m4 : 16|16@1- (0.1,0) [-1000|1000] "voltage:V" Vector__XXX
 SG_ INV_Diag_Id_cmd m3 : 16|16@1- (0.1,0) [-2000|2000] "current:A" Vector__XXX
 SG_ INV_Diag_Ic m2 : 16|16@1- (0.1,0) [-2000|2000] "current:A" Vector__XXX
 SG_ INV_Diag_Cos m1 : 16|16@1- (1,0) [-5|5] "voltage:V" Vector__XXX
 SG_ INV_Diag_Gamma_Resolver m0 : 16|16@1- (0.1,0) [0|360] "angle:deg" Vector__XXX
 SG_ INV_Diag_Segment M : 8|8@1+ (1,0) [0|5] "" Vector__XXX
 SG_ INV_Diag_Record : 0|8@1+ (1,0) [0|160] "" Vector__XXX

BO_ 176 M176_Fast_Info: 8 INV
 SG_ INV_Fast_DC_Bus_Voltage : 48|16@1- (0.1,0) [-3276.8|3276.7] "voltage:V" Vector__XXX
 SG_ INV_Fast_Motor_Speed : 32|16@1- (1,0) [-32768|32767] "angular_speed:rpm" Vector__XXX
 SG_ INV_Fast_Torque_Feedback : 16|16@1- (0.1,0) [-3276.8|3276.7] "torque:N.m" Vector__XXX
 SG_ INV_Fast_Torque_Command : 0|16@1- (0.1,0) [-3276.8|3276.7] "torque:N.m" Vector__XXX

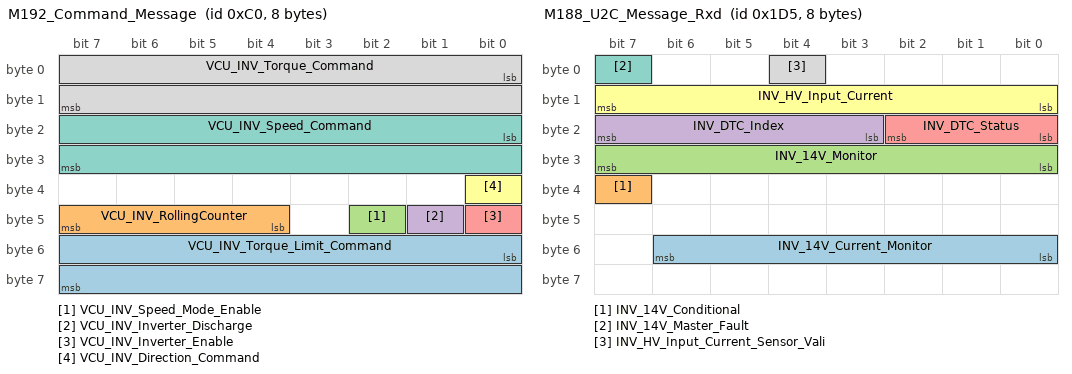
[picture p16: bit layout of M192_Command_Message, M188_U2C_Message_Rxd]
BO_ 192 M192_Command_Message: 8 VCU
 SG_ VCU_INV_Torque_Limit_Command : 48|16@1- (0.1,0) [-3276.8|3276.7] "torque:N.m" Vector__XXX
 SG_ VCU_INV_RollingCounter : 44|4@1+ (1,0) [0|15] "" Vector__XXX
 SG_ VCU_INV_Speed_Mode_Enable : 42|1@1+ (1,0) [0|1] "" Vector__XXX
 SG_ VCU_INV_Inverter_Discharge : 41|1@1+ (1,0) [0|1] "" Vector__XXX
 SG_ VCU_INV_Inverter_Enable : 40|1@1+ (1,0) [0|1] "Bit" Vector__XXX
 SG_ VCU_INV_Direction_Command : 32|1@1+ (1,0) [0|1] "Bit" Vector__XXX
 SG_ VCU_INV_Speed_Command : 16|16@1- (1,0) [-32768|32767] "rpm" Vector__XXX
 SG_ VCU_INV_Torque_Command : 0|16@1- (0.1,0) [-3276.8|3276.7] "torque:N.m" Vector__XXX

BO_ 193 M193_Read_Write_Param_Command: 8 VCU
 SG_ VCU_INV_Data_Command : 32|16@1- (1,0) [-32768|32767] "" Vector__XXX
 SG_ VCU_INV_Read_Write_Command : 16|1@1+ (1,0) [0|1] "" Vector__XXX
 SG_ VCU_INV_Parameter_Address_Comman : 0|16@1+ (1,0) [0|65535] "" Vector__XXX

BO_ 194 M194_Read_Write_Param_Response: 8 INV
 SG_ INV_Data_Response : 32|16@1- (1,0) [-32768|32767] "" Vector__XXX
 SG_ INV_Write_Success : 16|1@1+ (1,0) [0|1] "" Vector__XXX
 SG_ INV_Parameter_Address_Response : 0|16@1+ (1,0) [0|65535] "" Vector__XXX

BO_ 208 pcu_heartbeat: 8 Vector__XXX
 SG_ error63 : 63|1@1+ (1,0) [0|0] "" Vector__XXX
 SG_ error62 : 62|1@1+ (1,0) [0|0] "" Vector__XXX
 SG_ error61 : 61|1@1+ (1,0) [0|0] "" Vector__XXX
 SG_ error60 : 60|1@1+ (1,0) [0|0] "" Vector__XXX
 SG_ error59 : 59|1@1+ (1,0) [0|0] "" Vector__XXX
 SG_ error58 : 58|1@1+ (1,0) [0|0] "" Vector__XXX
 SG_ error57 : 57|1@1+ (1,0) [0|0] "" Vector__XXX
 SG_ error56 : 56|1@1+ (1,0) [0|0] "" Vector__XXX
 SG_ error55 : 55|1@1+ (1,0) [0|0] "" Vector__XXX
 SG_ error54 : 54|1@1+ (1,0) [0|0] "" Vector__XXX
 SG_ error53 : 53|1@1+ (1,0) [0|0] "" Vector__XXX
 SG_ error52 : 52|1@1+ (1,0) [0|0] "" Vector__XXX
 SG_ error51 : 51|1@1+ (1,0) [0|0] "" Vector__XXX
 SG_ error50 : 50|1@1+ (1,0) [0|0] "" Vector__XXX
 SG_ error49 : 49|1@1+ (1,0) [0|0] "" Vector__XXX
 SG_ error48 : 48|1@1+ (1,0) [0|0] "" Vector__XXX
 SG_ error47 : 47|1@1+ (1,0) [0|0] "" Vector__XXX
 SG_ error46 : 46|1@1+ (1,0) [0|0] "" Vector__XXX
 SG_ error45 : 45|1@1+ (1,0) [0|0] "" Vector__XXX
 SG_ error44 : 44|1@1+ (1,0) [0|0] "" Vector__XXX
 SG_ error43 : 43|1@1+ (1,0) [0|0] "" Vector__XXX
 SG_ error42 : 42|1@1+ (1,0) [0|0] "" Vector__XXX
 SG_ error41 : 41|1@1+ (1,0) [0|0] "" Vector__XXX
 SG_ error40 : 40|1@1+ (1,0) [0|0] "" Vector__XXX
 SG_ error39 : 39|1@1+ (1,0) [0|0] "" Vector__XXX
 SG_ error38 : 38|1@1+ (1,0) [0|0] "" Vector__XXX
 SG_ error37 : 37|1@1+ (1,0) [0|0] "" Vector__XXX
 SG_ error36 : 36|1@1+ (1,0) [0|0] "" Vector__XXX
 SG_ error35 : 35|1@1+ (1,0) [0|0] "" Vector__XXX
 SG_ error34 : 34|1@1+ (1,0) [0|0] "" Vector__XXX
 SG_ error33 : 33|1@1+ (1,0) [0|0] "" Vector__XXX
 SG_ error32 : 32|1@1+ (1,0) [0|0] "" Vector__XXX
 SG_ error31 : 31|1@1+ (1,0) [0|0] "" Vector__XXX
 SG_ error30 : 30|1@1+ (1,0) [0|0] "" Vector__XXX
 SG_ error29 : 29|1@1+ (1,0) [0|0] "" Vector__XXX
 SG_ error28 : 28|1@1+ (1,0) [0|0] "" Vector__XXX
 SG_ error27 : 27|1@1+ (1,0) [0|0] "" Vector__XXX
 SG_ error26 : 26|1@1+ (1,0) [0|0] "" Vector__XXX
 SG_ error25 : 25|1@1+ (1,0) [0|0] "" Vector__XXX
 SG_ error24 : 24|1@1+ (1,0) [0|0] "" Vector__XXX
 SG_ error23 : 23|1@1+ (1,0) [0|0] "" Vector__XXX
 SG_ error22 : 22|1@1+ (1,0) [0|0] "" Vector__XXX
 SG_ error21 : 21|1@1+ (1,0) [0|0] "" Vector__XXX
 SG_ error20 : 20|1@1+ (1,0) [0|0] "" Vector__XXX
 SG_ error19 : 19|1@1+ (1,0) [0|0] "" Vector__XXX
 SG_ error18 : 18|1@1+ (1,0) [0|0] "" Vector__XXX
 SG_ error17 : 17|1@1+ (1,0) [0|0] "" Vector__XXX
 SG_ error16 : 16|1@1+ (1,0) [0|0] "" Vector__XXX
 SG_ error15 : 15|1@1+ (1,0) [0|0] "" Vector__XXX
 SG_ error14 : 14|1@1+ (1,0) [0|0] "" Vector__XXX
 SG_ error13 : 13|1@1+ (1,0) [0|0] "" Vector__XXX
 SG_ error12 : 12|1@1+ (1,0) [0|0] "" Vector__XXX
 SG_ error11 : 11|1@1+ (1,0) [0|0] "" Vector__XXX
 SG_ error10 : 10|1@1+ (1,0) [0|0] "" Vector__XXX
 SG_ error9 : 9|1@1+ (1,0) [0|0] "" Vector__XXX
 SG_ error8 : 8|1@1+ (1,0) [0|0] "" Vector__XXX
 SG_ error7 : 7|1@1+ (1,0) [0|0] "" Vector__XXX
 SG_ error6 : 6|1@1+ (1,0) [0|0] "" Vector__XXX
 SG_ error5 : 5|1@1+ (1,0) [0|0] "" Vector__XXX
 SG_ error4 : 4|1@1+ (1,0) [0|0] "" Vector__XXX
 SG_ error3 : 3|1@1+ (1,0) [0|0] "" Vector__XXX
 SG_ error2 : 2|1@1+ (1,0) [0|0] "" Vector__XXX
 SG_ error1 : 1|1@1+ (1,0) [0|0] "" Vector__XXX
 SG_ error0 : 0|1@1+ (1,0) [0|0] "" Vector__XXX

BO_ 209 dash_heartbeat: 8 Vector__XXX
 SG_ error63 : 63|1@1+ (1,0) [0|0] "" Vector__XXX
 SG_ error62 : 62|1@1+ (1,0) [0|0] "" Vector__XXX
 SG_ error61 : 61|1@1+ (1,0) [0|0] "" Vector__XXX
 SG_ error60 : 60|1@1+ (1,0) [0|0] "" Vector__XXX
 SG_ error59 : 59|1@1+ (1,0) [0|0] "" Vector__XXX
 SG_ error58 : 58|1@1+ (1,0) [0|0] "" Vector__XXX
 SG_ error57 : 57|1@1+ (1,0) [0|0] "" Vector__XXX
 SG_ error56 : 56|1@1+ (1,0) [0|0] "" Vector__XXX
 SG_ error55 : 55|1@1+ (1,0) [0|0] "" Vector__XXX
 SG_ error54 : 54|1@1+ (1,0) [0|0] "" Vector__XXX
 SG_ error53 : 53|1@1+ (1,0) [0|0] "" Vector__XXX
 SG_ error52 : 52|1@1+ (1,0) [0|0] "" Vector__XXX
 SG_ error51 : 51|1@1+ (1,0) [0|0] "" Vector__XXX
 SG_ error50 : 50|1@1+ (1,0) [0|0] "" Vector__XXX
 SG_ error49 : 49|1@1+ (1,0) [0|0] "" Vector__XXX
 SG_ error48 : 48|1@1+ (1,0) [0|0] "" Vector__XXX
 SG_ error47 : 47|1@1+ (1,0) [0|0] "" Vector__XXX
 SG_ error46 : 46|1@1+ (1,0) [0|0] "" Vector__XXX
 SG_ error45 : 45|1@1+ (1,0) [0|0] "" Vector__XXX
 SG_ error44 : 44|1@1+ (1,0) [0|0] "" Vector__XXX
 SG_ error43 : 43|1@1+ (1,0) [0|0] "" Vector__XXX
 SG_ error42 : 42|1@1+ (1,0) [0|0] "" Vector__XXX
 SG_ error41 : 41|1@1+ (1,0) [0|0] "" Vector__XXX
 SG_ error40 : 40|1@1+ (1,0) [0|0] "" Vector__XXX
 SG_ error39 : 39|1@1+ (1,0) [0|0] "" Vector__XXX
 SG_ error38 : 38|1@1+ (1,0) [0|0] "" Vector__XXX
 SG_ error37 : 37|1@1+ (1,0) [0|0] "" Vector__XXX
 SG_ error36 : 36|1@1+ (1,0) [0|0] "" Vector__XXX
 SG_ error35 : 35|1@1+ (1,0) [0|0] "" Vector__XXX
 SG_ error34 : 34|1@1+ (1,0) [0|0] "" Vector__XXX
 SG_ error33 : 33|1@1+ (1,0) [0|0] "" Vector__XXX
 SG_ error32 : 32|1@1+ (1,0) [0|0] "" Vector__XXX
 SG_ error31 : 31|1@1+ (1,0) [0|0] "" Vector__XXX
 SG_ error30 : 30|1@1+ (1,0) [0|0] "" Vector__XXX
 SG_ error29 : 29|1@1+ (1,0) [0|0] "" Vector__XXX
 SG_ error28 : 28|1@1+ (1,0) [0|0] "" Vector__XXX
 SG_ error27 : 27|1@1+ (1,0) [0|0] "" Vector__XXX
 SG_ error26 : 26|1@1+ (1,0) [0|0] "" Vector__XXX
 SG_ error25 : 25|1@1+ (1,0) [0|0] "" Vector__XXX
 SG_ error24 : 24|1@1+ (1,0) [0|0] "" Vector__XXX
 SG_ error23 : 23|1@1+ (1,0) [0|0] "" Vector__XXX
 SG_ error22 : 22|1@1+ (1,0) [0|0] "" Vector__XXX
 SG_ error21 : 21|1@1+ (1,0) [0|0] "" Vector__XXX
 SG_ error20 : 20|1@1+ (1,0) [0|0] "" Vector__XXX
 SG_ error19 : 19|1@1+ (1,0) [0|0] "" Vector__XXX
 SG_ error18 : 18|1@1+ (1,0) [0|0] "" Vector__XXX
 SG_ error17 : 17|1@1+ (1,0) [0|0] "" Vector__XXX
 SG_ error16 : 16|1@1+ (1,0) [0|0] "" Vector__XXX
 SG_ error15 : 15|1@1+ (1,0) [0|0] "" Vector__XXX
 SG_ error14 : 14|1@1+ (1,0) [0|0] "" Vector__XXX
 SG_ error13 : 13|1@1+ (1,0) [0|0] "" Vector__XXX
 SG_ error12 : 12|1@1+ (1,0) [0|0] "" Vector__XXX
 SG_ error11 : 11|1@1+ (1,0) [0|0] "" Vector__XXX
 SG_ error10 : 10|1@1+ (1,0) [0|0] "" Vector__XXX
 SG_ error9 : 9|1@1+ (1,0) [0|0] "" Vector__XXX
 SG_ error8 : 8|1@1+ (1,0) [0|0] "" Vector__XXX
 SG_ error7 : 7|1@1+ (1,0) [0|0] "" Vector__XXX
 SG_ error6 : 6|1@1+ (1,0) [0|0] "" Vector__XXX
 SG_ error5 : 5|1@1+ (1,0) [0|0] "" Vector__XXX
 SG_ error4 : 4|1@1+ (1,0) [0|0] "" Vector__XXX
 SG_ error3 : 3|1@1+ (1,0) [0|0] "" Vector__XXX
 SG_ error2 : 2|1@1+ (1,0) [0|0] "" Vector__XXX
 SG_ error1 : 1|1@1+ (1,0) [0|0] "" Vector__XXX
 SG_ io_expander_error : 0|1@1+ (1,0) [0|0] "" Vector__XXX

BO_ 210 lvpdb_heartbeat: 8 Vector__XXX
 SG_ error63 : 63|1@1+ (1,0) [0|0] "" Vector__XXX
 SG_ error62 : 62|1@1+ (1,0) [0|0] "" Vector__XXX
 SG_ error61 : 61|1@1+ (1,0) [0|0] "" Vector__XXX
 SG_ error60 : 60|1@1+ (1,0) [0|0] "" Vector__XXX
 SG_ error59 : 59|1@1+ (1,0) [0|0] "" Vector__XXX
 SG_ error58 : 58|1@1+ (1,0) [0|0] "" Vector__XXX
 SG_ error57 : 57|1@1+ (1,0) [0|0] "" Vector__XXX
 SG_ error56 : 56|1@1+ (1,0) [0|0] "" Vector__XXX
 SG_ error55 : 55|1@1+ (1,0) [0|0] "" Vector__XXX
 SG_ error54 : 54|1@1+ (1,0) [0|0] "" Vector__XXX
 SG_ error53 : 53|1@1+ (1,0) [0|0] "" Vector__XXX
 SG_ error52 : 52|1@1+ (1,0) [0|0] "" Vector__XXX
 SG_ error51 : 51|1@1+ (1,0) [0|0] "" Vector__XXX
 SG_ error50 : 50|1@1+ (1,0) [0|0] "" Vector__XXX
 SG_ error49 : 49|1@1+ (1,0) [0|0] "" Vector__XXX
 SG_ error48 : 48|1@1+ (1,0) [0|0] "" Vector__XXX
 SG_ error47 : 47|1@1+ (1,0) [0|0] "" Vector__XXX
 SG_ error46 : 46|1@1+ (1,0) [0|0] "" Vector__XXX
 SG_ error45 : 45|1@1+ (1,0) [0|0] "" Vector__XXX
 SG_ error44 : 44|1@1+ (1,0) [0|0] "" Vector__XXX
 SG_ error43 : 43|1@1+ (1,0) [0|0] "" Vector__XXX
 SG_ error42 : 42|1@1+ (1,0) [0|0] "" Vector__XXX
 SG_ error41 : 41|1@1+ (1,0) [0|0] "" Vector__XXX
 SG_ error40 : 40|1@1+ (1,0) [0|0] "" Vector__XXX
 SG_ error39 : 39|1@1+ (1,0) [0|0] "" Vector__XXX
 SG_ error38 : 38|1@1+ (1,0) [0|0] "" Vector__XXX
 SG_ error37 : 37|1@1+ (1,0) [0|0] "" Vector__XXX
 SG_ error36 : 36|1@1+ (1,0) [0|0] "" Vector__XXX
 SG_ error35 : 35|1@1+ (1,0) [0|0] "" Vector__XXX
 SG_ error34 : 34|1@1+ (1,0) [0|0] "" Vector__XXX
 SG_ error33 : 33|1@1+ (1,0) [0|0] "" Vector__XXX
 SG_ error32 : 32|1@1+ (1,0) [0|0] "" Vector__XXX
 SG_ error31 : 31|1@1+ (1,0) [0|0] "" Vector__XXX
 SG_ error30 : 30|1@1+ (1,0) [0|0] "" Vector__XXX
 SG_ error29 : 29|1@1+ (1,0) [0|0] "" Vector__XXX
 SG_ error28 : 28|1@1+ (1,0) [0|0] "" Vector__XXX
 SG_ error27 : 27|1@1+ (1,0) [0|0] "" Vector__XXX
 SG_ error26 : 26|1@1+ (1,0) [0|0] "" Vector__XXX
 SG_ error25 : 25|1@1+ (1,0) [0|0] "" Vector__XXX
 SG_ error24 : 24|1@1+ (1,0) [0|0] "" Vector__XXX
 SG_ error23 : 23|1@1+ (1,0) [0|0] "" Vector__XXX
 SG_ error22 : 22|1@1+ (1,0) [0|0] "" Vector__XXX
 SG_ error21 : 21|1@1+ (1,0) [0|0] "" Vector__XXX
 SG_ error20 : 20|1@1+ (1,0) [0|0] "" Vector__XXX
 SG_ error19 : 19|1@1+ (1,0) [0|0] "" Vector__XXX
 SG_ error18 : 18|1@1+ (1,0) [0|0] "" Vector__XXX
 SG_ error17 : 17|1@1+ (1,0) [0|0] "" Vector__XXX
 SG_ error16 : 16|1@1+ (1,0) [0|0] "" Vector__XXX
 SG_ dash_state_stale : 15|1@1+ (1,0) [0|0] "" Vector__XXX
 SG_ tps_cp_rf_power_not_good : 14|1@1+ (1,0) [0|0] "" Vector__XXX
 SG_ tps_af1_af2_power_not_good : 13|1@1+ (1,0) [0|0] "" Vector__XXX
 SG_ tps_sm_power_not_good : 12|1@1+ (1,0) [0|0] "" Vector__XXX
 SG_ tps_bm_l_power_not_good : 11|1@1+ (1,0) [0|0] "" Vector__XXX
 SG_ tps_lt_power_not_good : 10|1@1+ (1,0) [0|0] "" Vector__XXX
 SG_ tps_sh_power_not_good : 9|1@1+ (1,0) [0|0] "" Vector__XXX
 SG_ tps_lv_power_not_good : 8|1@1+ (1,0) [0|0] "" Vector__XXX
 SG_ tps_cp_rf_poll_failed : 7|1@1+ (1,0) [0|0] "" Vector__XXX
 SG_ tps_af1_af2_poll_failed : 6|1@1+ (1,0) [0|0] "" Vector__XXX
 SG_ tps_sm_poll_failed : 5|1@1+ (1,0) [0|0] "" Vector__XXX
 SG_ tps_bm_l_poll_failed : 4|1@1+ (1,0) [0|0] "" Vector__XXX
 SG_ tps_lt_poll_failed : 3|1@1+ (1,0) [0|0] "" Vector__XXX
 SG_ tps_sh_poll_failed : 2|1@1+ (1,0) [0|0] "" Vector__XXX
 SG_ tps_lv_poll_failed : 1|1@1+ (1,0) [0|0] "" Vector__XXX
 SG_ tps_init_failed : 0|1@1+ (1,0) [0|0] "" Vector__XXX

BO_ 211 dcu_heartbeat: 8 Vector__XXX
 SG_ error63 : 63|1@1+ (1,0) [0|0] "" Vector__XXX
 SG_ error62 : 62|1@1+ (1,0) [0|0] "" Vector__XXX
 SG_ error61 : 61|1@1+ (1,0) [0|0] "" Vector__XXX
 SG_ error60 : 60|1@1+ (1,0) [0|0] "" Vector__XXX
 SG_ error59 : 59|1@1+ (1,0) [0|0] "" Vector__XXX
 SG_ error58 : 58|1@1+ (1,0) [0|0] "" Vector__XXX
 SG_ error57 : 57|1@1+ (1,0) [0|0] "" Vector__XXX
 SG_ error56 : 56|1@1+ (1,0) [0|0] "" Vector__XXX
 SG_ error55 : 55|1@1+ (1,0) [0|0] "" Vector__XXX
 SG_ error54 : 54|1@1+ (1,0) [0|0] "" Vector__XXX
 SG_ error53 : 53|1@1+ (1,0) [0|0] "" Vector__XXX
 SG_ error52 : 52|1@1+ (1,0) [0|0] "" Vector__XXX
 SG_ error51 : 51|1@1+ (1,0) [0|0] "" Vector__XXX
 SG_ error50 : 50|1@1+ (1,0) [0|0] "" Vector__XXX
 SG_ error49 : 49|1@1+ (1,0) [0|0] "" Vector__XXX
 SG_ error48 : 48|1@1+ (1,0) [0|0] "" Vector__XXX
 SG_ error47 : 47|1@1+ (1,0) [0|0] "" Vector__XXX
 SG_ error46 : 46|1@1+ (1,0) [0|0] "" Vector__XXX
 SG_ error45 : 45|1@1+ (1,0) [0|0] "" Vector__XXX
 SG_ error44 : 44|1@1+ (1,0) [0|0] "" Vector__XXX
 SG_ error43 : 43|1@1+ (1,0) [0|0] "" Vector__XXX
 SG_ error42 : 42|1@1+ (1,0) [0|0] "" Vector__XXX
 SG_ error41 : 41|1@1+ (1,0) [0|0] "" Vector__XXX
 SG_ error40 : 40|1@1+ (1,0) [0|0] "" Vector__XXX
 SG_ error39 : 39|1@1+ (1,0) [0|0] "" Vector__XXX
 SG_ error38 : 38|1@1+ (1,0) [0|0] "" Vector__XXX
 SG_ error37 : 37|1@1+ (1,0) [0|0] "" Vector__XXX
 SG_ error36 : 36|1@1+ (1,0) [0|0] "" Vector__XXX
 SG_ error35 : 35|1@1+ (1,0) [0|0] "" Vector__XXX
 SG_ error34 : 34|1@1+ (1,0) [0|0] "" Vector__XXX
 SG_ error33 : 33|1@1+ (1,0) [0|0] "" Vector__XXX
 SG_ error32 : 32|1@1+ (1,0) [0|0] "" Vector__XXX
 SG_ error31 : 31|1@1+ (1,0) [0|0] "" Vector__XXX
 SG_ error30 : 30|1@1+ (1,0) [0|0] "" Vector__XXX
 SG_ error29 : 29|1@1+ (1,0) [0|0] "" Vector__XXX
 SG_ error28 : 28|1@1+ (1,0) [0|0] "" Vector__XXX
 SG_ error27 : 27|1@1+ (1,0) [0|0] "" Vector__XXX
 SG_ error26 : 26|1@1+ (1,0) [0|0] "" Vector__XXX
 SG_ error25 : 25|1@1+ (1,0) [0|0] "" Vector__XXX
 SG_ error24 : 24|1@1+ (1,0) [0|0] "" Vector__XXX
 SG_ error23 : 23|1@1+ (1,0) [0|0] "" Vector__XXX
 SG_ error22 : 22|1@1+ (1,0) [0|0] "" Vector__XXX
 SG_ error21 : 21|1@1+ (1,0) [0|0] "" Vector__XXX
 SG_ error20 : 20|1@1+ (1,0) [0|0] "" Vector__XXX
 SG_ error19 : 19|1@1+ (1,0) [0|0] "" Vector__XXX
 SG_ error18 : 18|1@1+ (1,0) [0|0] "" Vector__XXX
 SG_ error17 : 17|1@1+ (1,0) [0|0] "" Vector__XXX
 SG_ error16 : 16|1@1+ (1,0) [0|0] "" Vector__XXX
 SG_ error15 : 15|1@1+ (1,0) [0|0] "" Vector__XXX
 SG_ error14 : 14|1@1+ (1,0) [0|0] "" Vector__XXX
 SG_ error13 : 13|1@1+ (1,0) [0|0] "" Vector__XXX
 SG_ error12 : 12|1@1+ (1,0) [0|0] "" Vector__XXX
 SG_ error11 : 11|1@1+ (1,0) [0|0] "" Vector__XXX
 SG_ error10 : 10|1@1+ (1,0) [0|0] "" Vector__XXX
 SG_ error9 : 9|1@1+ (1,0) [0|0] "" Vector__XXX
 SG_ error8 : 8|1@1+ (1,0) [0|0] "" Vector__XXX
 SG_ error7 : 7|1@1+ (1,0) [0|0] "" Vector__XXX
 SG_ error6 : 6|1@1+ (1,0) [0|0] "" Vector__XXX
 SG_ error5 : 5|1@1+ (1,0) [0|0] "" Vector__XXX
 SG_ error4 : 4|1@1+ (1,0) [0|0] "" Vector__XXX
 SG_ error3 : 3|1@1+ (1,0) [0|0] "" Vector__XXX
 SG_ error2 : 2|1@1+ (1,0) [0|0] "" Vector__XXX
 SG_ error1 : 1|1@1+ (1,0) [0|0] "" Vector__XXX
 SG_ error0 : 0|1@1+ (1,0) [0|0] "" Vector__XXX

BO_ 212 front_sensor_heartbeat_message: 8 Vector__XXX
 SG_ error63 : 63|1@1+ (1,0) [0|0] "" Vector__XXX
 SG_ error62 : 62|1@1+ (1,0) [0|0] "" Vector__XXX
 SG_ error61 : 61|1@1+ (1,0) [0|0] "" Vector__XXX
 SG_ error60 : 60|1@1+ (1,0) [0|0] "" Vector__XXX
 SG_ error59 : 59|1@1+ (1,0) [0|0] "" Vector__XXX
 SG_ error58 : 58|1@1+ (1,0) [0|0] "" Vector__XXX
 SG_ error57 : 57|1@1+ (1,0) [0|0] "" Vector__XXX
 SG_ error56 : 56|1@1+ (1,0) [0|0] "" Vector__XXX
 SG_ error55 : 55|1@1+ (1,0) [0|0] "" Vector__XXX
 SG_ error54 : 54|1@1+ (1,0) [0|0] "" Vector__XXX
 SG_ error53 : 53|1@1+ (1,0) [0|0] "" Vector__XXX
 SG_ error52 : 52|1@1+ (1,0) [0|0] "" Vector__XXX
 SG_ error51 : 51|1@1+ (1,0) [0|0] "" Vector__XXX
 SG_ error50 : 50|1@1+ (1,0) [0|0] "" Vector__XXX
 SG_ error49 : 49|1@1+ (1,0) [0|0] "" Vector__XXX
 SG_ error48 : 48|1@1+ (1,0) [0|0] "" Vector__XXX
 SG_ error47 : 47|1@1+ (1,0) [0|0] "" Vector__XXX
 SG_ error46 : 46|1@1+ (1,0) [0|0] "" Vector__XXX
 SG_ error45 : 45|1@1+ (1,0) [0|0] "" Vector__XXX
 SG_ error44 : 44|1@1+ (1,0) [0|0] "" Vector__XXX
 SG_ error43 : 43|1@1+ (1,0) [0|0] "" Vector__XXX
 SG_ error42 : 42|1@1+ (1,0) [0|0] "" Vector__XXX
 SG_ error41 : 41|1@1+ (1,0) [0|0] "" Vector__XXX
 SG_ error40 : 40|1@1+ (1,0) [0|0] "" Vector__XXX
 SG_ error39 : 39|1@1+ (1,0) [0|0] "" Vector__XXX
 SG_ error38 : 38|1@1+ (1,0) [0|0] "" Vector__XXX
 SG_ error37 : 37|1@1+ (1,0) [0|0] "" Vector__XXX
 SG_ error36 : 36|1@1+ (1,0) [0|0] "" Vector__XXX
 SG_ error35 : 35|1@1+ (1,0) [0|0] "" Vector__XXX
 SG_ error34 : 34|1@1+ (1,0) [0|0] "" Vector__XXX
 SG_ error33 : 33|1@1+ (1,0) [0|0] "" Vector__XXX
 SG_ error32 : 32|1@1+ (1,0) [0|0] "" Vector__XXX
 SG_ error31 : 31|1@1+ (1,0) [0|0] "" Vector__XXX
 SG_ error30 : 30|1@1+ (1,0) [0|0] "" Vector__XXX
 SG_ error29 : 29|1@1+ (1,0) [0|0] "" Vector__XXX
 SG_ error28 : 28|1@1+ (1,0) [0|0] "" Vector__XXX
 SG_ error27 : 27|1@1+ (1,0) [0|0] "" Vector__XXX
 SG_ error26 : 26|1@1+ (1,0) [0|0] "" Vector__XXX
 SG_ error25 : 25|1@1+ (1,0) [0|0] "" Vector__XXX
 SG_ error24 : 24|1@1+ (1,0) [0|0] "" Vector__XXX
 SG_ error23 : 23|1@1+ (1,0) [0|0] "" Vector__XXX
 SG_ error22 : 22|1@1+ (1,0) [0|0] "" Vector__XXX
 SG_ error21 : 21|1@1+ (1,0) [0|0] "" Vector__XXX
 SG_ error20 : 20|1@1+ (1,0) [0|0] "" Vector__XXX
 SG_ error19 : 19|1@1+ (1,0) [0|0] "" Vector__XXX
 SG_ can_rx_overflow : 18|1@1+ (1,0) [0|0] "" Vector__XXX
 SG_ can_tx_overflow : 17|1@1+ (1,0) [0|0] "" Vector__XXX
 SG_ can_bus_off : 16|1@1+ (1,0) [0|0] "" Vector__XXX
 SG_ error15 : 15|1@1+ (1,0) [0|0] "" Vector__XXX
 SG_ error14 : 14|1@1+ (1,0) [0|0] "" Vector__XXX
 SG_ error13 : 13|1@1+ (1,0) [0|0] "" Vector__XXX
 SG_ wss_right_no_signal : 12|1@1+ (1,0) [0|0] "" Vector__XXX
 SG_ wss_left_no_signal : 11|1@1+ (1,0) [0|0] "" Vector__XXX
 SG_ gps_link_slow : 10|1@1+ (1,0) [0|0] "" Vector__XXX
 SG_ gps_stale : 9|1@1+ (1,0) [0|0] "" Vector__XXX
 SG_ gps_no_fix : 8|1@1+ (1,0) [0|0] "" Vector__XXX
 SG_ error7 : 7|1@1+ (1,0) [0|0] "" Vector__XXX
 SG_ lp_out_of_range : 6|1@1+ (1,0) [0|0] "" Vector__XXX
 SG_ fusion_uncalibrated : 5|1@1+ (1,0) [0|0] "" Vector__XXX
 SG_ gps_init_failed : 4|1@1+ (1,0) [0|0] "" Vector__XXX
 SG_ mag_read_failed : 3|1@1+ (1,0) [0|0] "" Vector__XXX
 SG_ mag_init_failed : 2|1@1+ (1,0) [0|0] "" Vector__XXX
 SG_ imu_read_failed : 1|1@1+ (1,0) [0|0] "" Vector__XXX
 SG_ imu_init_failed : 0|1@1+ (1,0) [0|0] "" Vector__XXX

BO_ 213 rear_sensor_heartbeat_message: 8 Vector__XXX
 SG_ error63 : 63|1@1+ (1,0) [0|0] "" Vector__XXX
 SG_ error62 : 62|1@1+ (1,0) [0|0] "" Vector__XXX
 SG_ error61 : 61|1@1+ (1,0) [0|0] "" Vector__XXX
 SG_ error60 : 60|1@1+ (1,0) [0|0] "" Vector__XXX
 SG_ error59 : 59|1@1+ (1,0) [0|0] "" Vector__XXX
 SG_ error58 : 58|1@1+ (1,0) [0|0] "" Vector__XXX
 SG_ error57 : 57|1@1+ (1,0) [0|0] "" Vector__XXX
 SG_ error56 : 56|1@1+ (1,0) [0|0] "" Vector__XXX
 SG_ error55 : 55|1@1+ (1,0) [0|0] "" Vector__XXX
 SG_ error54 : 54|1@1+ (1,0) [0|0] "" Vector__XXX
 SG_ error53 : 53|1@1+ (1,0) [0|0] "" Vector__XXX
 SG_ error52 : 52|1@1+ (1,0) [0|0] "" Vector__XXX
 SG_ error51 : 51|1@1+ (1,0) [0|0] "" Vector__XXX
 SG_ error50 : 50|1@1+ (1,0) [0|0] "" Vector__XXX
 SG_ error49 : 49|1@1+ (1,0) [0|0] "" Vector__XXX
 SG_ error48 : 48|1@1+ (1,0) [0|0] "" Vector__XXX
 SG_ error47 : 47|1@1+ (1,0) [0|0] "" Vector__XXX
 SG_ error46 : 46|1@1+ (1,0) [0|0] "" Vector__XXX
 SG_ error45 : 45|1@1+ (1,0) [0|0] "" Vector__XXX
 SG_ error44 : 44|1@1+ (1,0) [0|0] "" Vector__XXX
 SG_ error43 : 43|1@1+ (1,0) [0|0] "" Vector__XXX
 SG_ error42 : 42|1@1+ (1,0) [0|0] "" Vector__XXX
 SG_ error41 : 41|1@1+ (1,0) [0|0] "" Vector__XXX
 SG_ error40 : 40|1@1+ (1,0) [0|0] "" Vector__XXX
 SG_ error39 : 39|1@1+ (1,0) [0|0] "" Vector__XXX
 SG_ error38 : 38|1@1+ (1,0) [0|0] "" Vector__XXX
 SG_ error37 : 37|1@1+ (1,0) [0|0] "" Vector__XXX
 SG_ error36 : 36|1@1+ (1,0) [0|0] "" Vector__XXX
 SG_ error35 : 35|1@1+ (1,0) [0|0] "" Vector__XXX
 SG_ error34 : 34|1@1+ (1,0) [0|0] "" Vector__XXX
 SG_ error33 : 33|1@1+ (1,0) [0|0] "" Vector__XXX
 SG_ error32 : 32|1@1+ (1,0) [0|0] "" Vector__XXX
 SG_ error31 : 31|1@1+ (1,0) [0|0] "" Vector__XXX
 SG_ error30 : 30|1@1+ (1,0) [0|0] "" Vector__XXX
 SG_ error29 : 29|1@1+ (1,0) [0|0] "" Vector__XXX
 SG_ error28 : 28|1@1+ (1,0) [0|0] "" Vector__XXX
 SG_ error27 : 27|1@1+ (1,0) [0|0] "" Vector__XXX
 SG_ error26 : 26|1@1+ (1,0) [0|0] "" Vector__XXX
 SG_ error25 : 25|1@1+ (1,0) [0|0] "" Vector__XXX
 SG_ error24 : 24|1@1+ (1,0) [0|0] "" Vector__XXX
 SG_ error23 : 23|1@1+ (1,0) [0|0] "" Vector__XXX
 SG_ error22 : 22|1@1+ (1,0) [0|0] "" Vector__XXX
 SG_ error21 : 21|1@1+ (1,0) [0|0] "" Vector__XXX
 SG_ error20 : 20|1@1+ (1,0) [0|0] "" Vector__XXX
 SG_ error19 : 19|1@1+ (1,0) [0|0] "" Vector__XXX
 SG_ can_rx_overflow : 18|1@1+ (1,0) [0|0] "" Vector__XXX
 SG_ can_tx_overflow : 17|1@1+ (1,0) [0|0] "" Vector__XXX
 SG_ can_bus_off : 16|1@1+ (1,0) [0|0] "" Vector__XXX
 SG_ error15 : 15|1@1+ (1,0) [0|0] "" Vector__XXX
 SG_ error14 : 14|1@1+ (1,0) [0|0] "" Vector__XXX
 SG_ error13 : 13|1@1+ (1,0) [0|0] "" Vector__XXX
 SG_ wss_right_no_signal : 12|1@1+ (1,0) [0|0] "" Vector__XXX
 SG_ wss_left_no_signal : 11|1@1+ (1,0) [0|0] "" Vector__XXX
 SG_ gps_link_slow : 10|1@1+ (1,0) [0|0] "" Vector__XXX
 SG_ gps_stale : 9|1@1+ (1,0) [0|0] "" Vector__XXX
 SG_ gps_no_fix : 8|1@1+ (1,0) [0|0] "" Vector__XXX
 SG_ error7 : 7|1@1+ (1,0) [0|0] "" Vector__XXX
 SG_ lp_out_of_range : 6|1@1+ (1,0) [0|0] "" Vector__XXX
 SG_ fusion_uncalibrated : 5|1@1+ (1,0) [0|0] "" Vector__XXX
 SG_ gps_init_failed : 4|1@1+ (1,0) [0|0] "" Vector__XXX
 SG_ mag_read_failed : 3|1@1+ (1,0) [0|0] "" Vector__XXX
 SG_ mag_init_failed : 2|1@1+ (1,0) [0|0] "" Vector__XXX
 SG_ imu_read_failed : 1|1@1+ (1,0) [0|0] "" Vector__XXX
 SG_ imu_init_failed : 0|1@1+ (1,0) [0|0] "" Vector__XXX

BO_ 224 FEB_PING_PONG_counter1: 8 Vector__XXX
 SG_ counter : 0|32@1- (1,0) [0|0] "" Vector__XXX

BO_ 225 FEB_PING_PONG_counter2: 8 Vector__XXX
 SG_ counter : 0|32@1- (1,0) [0|0] "" Vector__XXX

BO_ 226 FEB_PING_PONG_counter3: 8 Vector__XXX
 SG_ counter : 0|32@1- (1,0) [0|0] "" Vector__XXX

BO_ 227 FEB_PING_PONG_counter4: 8 Vector__XXX
 SG_ counter : 0|32@1- (1,0) [0|0] "" Vector__XXX

BO_ 469 M188_U2C_Message_Rxd: 8 U2C
 SG_ INV_14V_Current_Monitor : 48|7@1+ (1,0) [0|127] "" Vector__XXX
 SG_ INV_14V_Conditional : 39|1@1+ (1,0) [0|1] "" Vector__XXX
 SG_ INV_14V_Monitor : 24|8@1+ (1,0) [0|255] "" Vector__XXX
 SG_ INV_DTC_Index : 19|5@1+ (1,0) [0|31] "" Vector__XXX
 SG_ INV_DTC_Status : 16|3@1+ (1,0) [0|7] "" Vector__XXX
 SG_ INV_HV_Input_Current : 8|8@1+ (1,0) [0|255] "" Vector__XXX
 SG_ INV_14V_Master_Fault : 7|1@1+ (1,0) [0|1] "" Vector__XXX
 SG_ INV_HV_Input_Current_Sensor_Vali : 4|1@1+ (1,0) [0|1] "" Vector__XXX

BO_ 471 M187_U2C_Command_Txd: 8 INV
 SG_ U2C_Setpoint_Calc : 8|8@1+ (1,0) [0|255] "" Vector__XXX
 SG_ U2C_ID_Byte : 0|8@1+ (1,0) [0|255] "" Vector__XXX

BO_ 514 BMS_Current_Limit: 8 BMS
 SG_ INV_Max_Charge_Current : 16|16@1+ (1,0) [0|1000] "current:A" Vector__XXX
 SG_ INV_Max_Discharge_Current : 0|16@1+ (1,0) [0|1000] "current:A" Vector__XXX

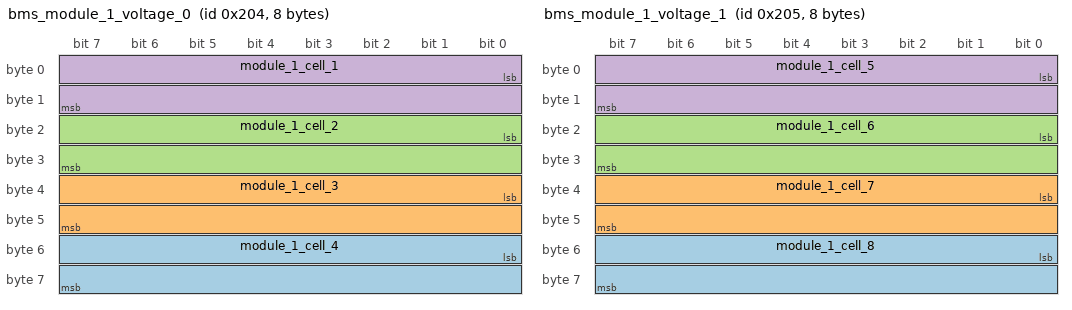
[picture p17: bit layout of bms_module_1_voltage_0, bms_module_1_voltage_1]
BO_ 516 bms_module_1_voltage_0: 8 Vector__XXX
 SG_ module_1_cell_4 : 48|16@1+ (1,0) [0|0] "" Vector__XXX
 SG_ module_1_cell_3 : 32|16@1+ (1,0) [0|0] "" Vector__XXX
 SG_ module_1_cell_2 : 16|16@1+ (1,0) [0|0] "" Vector__XXX
 SG_ module_1_cell_1 : 0|16@1+ (1,0) [0|0] "" Vector__XXX

BO_ 517 bms_module_1_voltage_1: 8 Vector__XXX
 SG_ module_1_cell_8 : 48|16@1+ (1,0) [0|0] "" Vector__XXX
 SG_ module_1_cell_7 : 32|16@1+ (1,0) [0|0] "" Vector__XXX
 SG_ module_1_cell_6 : 16|16@1+ (1,0) [0|0] "" Vector__XXX
 SG_ module_1_cell_5 : 0|16@1+ (1,0) [0|0] "" Vector__XXX

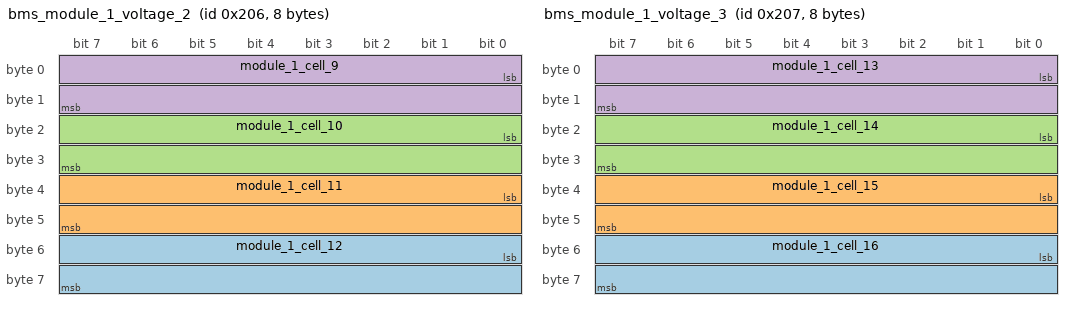
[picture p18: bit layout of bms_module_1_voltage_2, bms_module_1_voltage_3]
BO_ 518 bms_module_1_voltage_2: 8 Vector__XXX
 SG_ module_1_cell_12 : 48|16@1+ (1,0) [0|0] "" Vector__XXX
 SG_ module_1_cell_11 : 32|16@1+ (1,0) [0|0] "" Vector__XXX
 SG_ module_1_cell_10 : 16|16@1+ (1,0) [0|0] "" Vector__XXX
 SG_ module_1_cell_9 : 0|16@1+ (1,0) [0|0] "" Vector__XXX

BO_ 519 bms_module_1_voltage_3: 8 Vector__XXX
 SG_ module_1_cell_16 : 48|16@1+ (1,0) [0|0] "" Vector__XXX
 SG_ module_1_cell_15 : 32|16@1+ (1,0) [0|0] "" Vector__XXX
 SG_ module_1_cell_14 : 16|16@1+ (1,0) [0|0] "" Vector__XXX
 SG_ module_1_cell_13 : 0|16@1+ (1,0) [0|0] "" Vector__XXX

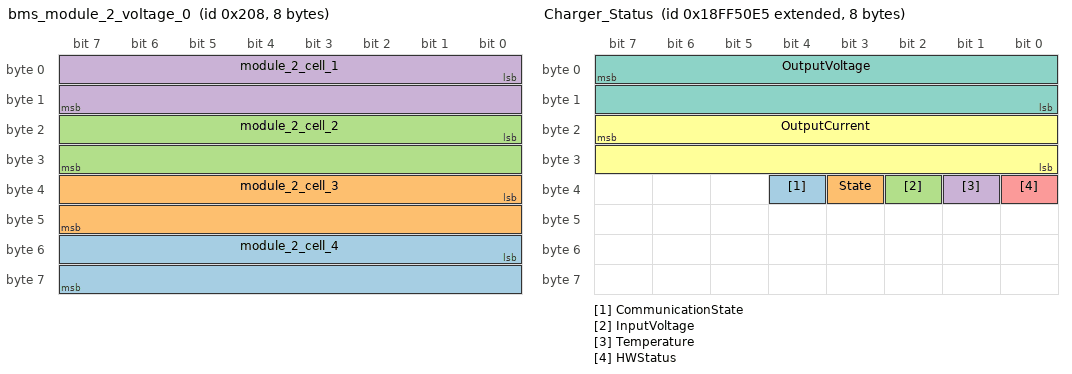
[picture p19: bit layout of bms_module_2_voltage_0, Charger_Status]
BO_ 520 bms_module_2_voltage_0: 8 Vector__XXX
 SG_ module_2_cell_4 : 48|16@1+ (1,0) [0|0] "" Vector__XXX
 SG_ module_2_cell_3 : 32|16@1+ (1,0) [0|0] "" Vector__XXX
 SG_ module_2_cell_2 : 16|16@1+ (1,0) [0|0] "" Vector__XXX
 SG_ module_2_cell_1 : 0|16@1+ (1,0) [0|0] "" Vector__XXX

BO_ 521 bms_module_2_voltage_1: 8 Vector__XXX
 SG_ module_2_cell_8 : 48|16@1+ (1,0) [0|0] "" Vector__XXX
 SG_ module_2_cell_7 : 32|16@1+ (1,0) [0|0] "" Vector__XXX
 SG_ module_2_cell_6 : 16|16@1+ (1,0) [0|0] "" Vector__XXX
 SG_ module_2_cell_5 : 0|16@1+ (1,0) [0|0] "" Vector__XXX

BO_ 522 bms_module_2_voltage_2: 8 Vector__XXX
 SG_ module_2_cell_12 : 48|16@1+ (1,0) [0|0] "" Vector__XXX
 SG_ module_2_cell_11 : 32|16@1+ (1,0) [0|0] "" Vector__XXX
 SG_ module_2_cell_10 : 16|16@1+ (1,0) [0|0] "" Vector__XXX
 SG_ module_2_cell_9 : 0|16@1+ (1,0) [0|0] "" Vector__XXX

BO_ 523 bms_module_2_voltage_3: 8 Vector__XXX
 SG_ module_2_cell_16 : 48|16@1+ (1,0) [0|0] "" Vector__XXX
 SG_ module_2_cell_15 : 32|16@1+ (1,0) [0|0] "" Vector__XXX
 SG_ module_2_cell_14 : 16|16@1+ (1,0) [0|0] "" Vector__XXX
 SG_ module_2_cell_13 : 0|16@1+ (1,0) [0|0] "" Vector__XXX

BO_ 524 bms_module_3_voltage_0: 8 Vector__XXX
 SG_ module_3_cell_4 : 48|16@1+ (1,0) [0|0] "" Vector__XXX
 SG_ module_3_cell_3 : 32|16@1+ (1,0) [0|0] "" Vector__XXX
 SG_ module_3_cell_2 : 16|16@1+ (1,0) [0|0] "" Vector__XXX
 SG_ module_3_cell_1 : 0|16@1+ (1,0) [0|0] "" Vector__XXX

BO_ 525 bms_module_3_voltage_1: 8 Vector__XXX
 SG_ module_3_cell_8 : 48|16@1+ (1,0) [0|0] "" Vector__XXX
 SG_ module_3_cell_7 : 32|16@1+ (1,0) [0|0] "" Vector__XXX
 SG_ module_3_cell_6 : 16|16@1+ (1,0) [0|0] "" Vector__XXX
 SG_ module_3_cell_5 : 0|16@1+ (1,0) [0|0] "" Vector__XXX

BO_ 526 bms_module_3_voltage_2: 8 Vector__XXX
 SG_ module_3_cell_12 : 48|16@1+ (1,0) [0|0] "" Vector__XXX
 SG_ module_3_cell_11 : 32|16@1+ (1,0) [0|0] "" Vector__XXX
 SG_ module_3_cell_10 : 16|16@1+ (1,0) [0|0] "" Vector__XXX
 SG_ module_3_cell_9 : 0|16@1+ (1,0) [0|0] "" Vector__XXX

BO_ 527 bms_module_3_voltage_3: 8 Vector__XXX
 SG_ module_3_cell_16 : 48|16@1+ (1,0) [0|0] "" Vector__XXX
 SG_ module_3_cell_15 : 32|16@1+ (1,0) [0|0] "" Vector__XXX
 SG_ module_3_cell_14 : 16|16@1+ (1,0) [0|0] "" Vector__XXX
 SG_ module_3_cell_13 : 0|16@1+ (1,0) [0|0] "" Vector__XXX

BO_ 528 bms_module_4_voltage_0: 8 Vector__XXX
 SG_ module_4_cell_4 : 48|16@1+ (1,0) [0|0] "" Vector__XXX
 SG_ module_4_cell_3 : 32|16@1+ (1,0) [0|0] "" Vector__XXX
 SG_ module_4_cell_2 : 16|16@1+ (1,0) [0|0] "" Vector__XXX
 SG_ module_4_cell_1 : 0|16@1+ (1,0) [0|0] "" Vector__XXX

BO_ 529 bms_module_4_voltage_1: 8 Vector__XXX
 SG_ module_4_cell_8 : 48|16@1+ (1,0) [0|0] "" Vector__XXX
 SG_ module_4_cell_7 : 32|16@1+ (1,0) [0|0] "" Vector__XXX
 SG_ module_4_cell_6 : 16|16@1+ (1,0) [0|0] "" Vector__XXX
 SG_ module_4_cell_5 : 0|16@1+ (1,0) [0|0] "" Vector__XXX

BO_ 530 bms_module_4_voltage_2: 8 Vector__XXX
 SG_ module_4_cell_12 : 48|16@1+ (1,0) [0|0] "" Vector__XXX
 SG_ module_4_cell_11 : 32|16@1+ (1,0) [0|0] "" Vector__XXX
 SG_ module_4_cell_10 : 16|16@1+ (1,0) [0|0] "" Vector__XXX
 SG_ module_4_cell_9 : 0|16@1+ (1,0) [0|0] "" Vector__XXX

BO_ 531 bms_module_4_voltage_3: 8 Vector__XXX
 SG_ module_4_cell_16 : 48|16@1+ (1,0) [0|0] "" Vector__XXX
 SG_ module_4_cell_15 : 32|16@1+ (1,0) [0|0] "" Vector__XXX
 SG_ module_4_cell_14 : 16|16@1+ (1,0) [0|0] "" Vector__XXX
 SG_ module_4_cell_13 : 0|16@1+ (1,0) [0|0] "" Vector__XXX

BO_ 532 bms_module_5_voltage_0: 8 Vector__XXX
 SG_ module_5_cell_4 : 48|16@1+ (1,0) [0|0] "" Vector__XXX
 SG_ module_5_cell_3 : 32|16@1+ (1,0) [0|0] "" Vector__XXX
 SG_ module_5_cell_2 : 16|16@1+ (1,0) [0|0] "" Vector__XXX
 SG_ module_5_cell_1 : 0|16@1+ (1,0) [0|0] "" Vector__XXX

BO_ 533 bms_module_5_voltage_1: 8 Vector__XXX
 SG_ module_5_cell_8 : 48|16@1+ (1,0) [0|0] "" Vector__XXX
 SG_ module_5_cell_7 : 32|16@1+ (1,0) [0|0] "" Vector__XXX
 SG_ module_5_cell_6 : 16|16@1+ (1,0) [0|0] "" Vector__XXX
 SG_ module_5_cell_5 : 0|16@1+ (1,0) [0|0] "" Vector__XXX

BO_ 534 bms_module_5_voltage_2: 8 Vector__XXX
 SG_ module_5_cell_12 : 48|16@1+ (1,0) [0|0] "" Vector__XXX
 SG_ module_5_cell_11 : 32|16@1+ (1,0) [0|0] "" Vector__XXX
 SG_ module_5_cell_10 : 16|16@1+ (1,0) [0|0] "" Vector__XXX
 SG_ module_5_cell_9 : 0|16@1+ (1,0) [0|0] "" Vector__XXX

BO_ 535 bms_module_5_voltage_3: 8 Vector__XXX
 SG_ module_5_cell_16 : 48|16@1+ (1,0) [0|0] "" Vector__XXX
 SG_ module_5_cell_15 : 32|16@1+ (1,0) [0|0] "" Vector__XXX
 SG_ module_5_cell_14 : 16|16@1+ (1,0) [0|0] "" Vector__XXX
 SG_ module_5_cell_13 : 0|16@1+ (1,0) [0|0] "" Vector__XXX

BO_ 536 bms_module_6_voltage_0: 8 Vector__XXX
 SG_ module_6_cell_4 : 48|16@1+ (1,0) [0|0] "" Vector__XXX
 SG_ module_6_cell_3 : 32|16@1+ (1,0) [0|0] "" Vector__XXX
 SG_ module_6_cell_2 : 16|16@1+ (1,0) [0|0] "" Vector__XXX
 SG_ module_6_cell_1 : 0|16@1+ (1,0) [0|0] "" Vector__XXX

BO_ 537 bms_module_6_voltage_1: 8 Vector__XXX
 SG_ module_6_cell_8 : 48|16@1+ (1,0) [0|0] "" Vector__XXX
 SG_ module_6_cell_7 : 32|16@1+ (1,0) [0|0] "" Vector__XXX
 SG_ module_6_cell_6 : 16|16@1+ (1,0) [0|0] "" Vector__XXX
 SG_ module_6_cell_5 : 0|16@1+ (1,0) [0|0] "" Vector__XXX

BO_ 538 bms_module_6_voltage_2: 8 Vector__XXX
 SG_ module_6_cell_12 : 48|16@1+ (1,0) [0|0] "" Vector__XXX
 SG_ module_6_cell_11 : 32|16@1+ (1,0) [0|0] "" Vector__XXX
 SG_ module_6_cell_10 : 16|16@1+ (1,0) [0|0] "" Vector__XXX
 SG_ module_6_cell_9 : 0|16@1+ (1,0) [0|0] "" Vector__XXX

BO_ 539 bms_module_6_voltage_3: 8 Vector__XXX
 SG_ module_6_cell_16 : 48|16@1+ (1,0) [0|0] "" Vector__XXX
 SG_ module_6_cell_15 : 32|16@1+ (1,0) [0|0] "" Vector__XXX
 SG_ module_6_cell_14 : 16|16@1+ (1,0) [0|0] "" Vector__XXX
 SG_ module_6_cell_13 : 0|16@1+ (1,0) [0|0] "" Vector__XXX

BO_ 540 bms_module_7_voltage_0: 8 Vector__XXX
 SG_ module_7_cell_4 : 48|16@1+ (1,0) [0|0] "" Vector__XXX
 SG_ module_7_cell_3 : 32|16@1+ (1,0) [0|0] "" Vector__XXX
 SG_ module_7_cell_2 : 16|16@1+ (1,0) [0|0] "" Vector__XXX
 SG_ module_7_cell_1 : 0|16@1+ (1,0) [0|0] "" Vector__XXX

BO_ 541 bms_module_7_voltage_1: 8 Vector__XXX
 SG_ module_7_cell_8 : 48|16@1+ (1,0) [0|0] "" Vector__XXX
 SG_ module_7_cell_7 : 32|16@1+ (1,0) [0|0] "" Vector__XXX
 SG_ module_7_cell_6 : 16|16@1+ (1,0) [0|0] "" Vector__XXX
 SG_ module_7_cell_5 : 0|16@1+ (1,0) [0|0] "" Vector__XXX

BO_ 542 bms_module_7_voltage_2: 8 Vector__XXX
 SG_ module_7_cell_12 : 48|16@1+ (1,0) [0|0] "" Vector__XXX
 SG_ module_7_cell_11 : 32|16@1+ (1,0) [0|0] "" Vector__XXX
 SG_ module_7_cell_10 : 16|16@1+ (1,0) [0|0] "" Vector__XXX
 SG_ module_7_cell_9 : 0|16@1+ (1,0) [0|0] "" Vector__XXX

BO_ 543 bms_module_7_voltage_3: 8 Vector__XXX
 SG_ module_7_cell_16 : 48|16@1+ (1,0) [0|0] "" Vector__XXX
 SG_ module_7_cell_15 : 32|16@1+ (1,0) [0|0] "" Vector__XXX
 SG_ module_7_cell_14 : 16|16@1+ (1,0) [0|0] "" Vector__XXX
 SG_ module_7_cell_13 : 0|16@1+ (1,0) [0|0] "" Vector__XXX

BO_ 544 bms_module_8_voltage_0: 8 Vector__XXX
 SG_ module_8_cell_4 : 48|16@1+ (1,0) [0|0] "" Vector__XXX
 SG_ module_8_cell_3 : 32|16@1+ (1,0) [0|0] "" Vector__XXX
 SG_ module_8_cell_2 : 16|16@1+ (1,0) [0|0] "" Vector__XXX
 SG_ module_8_cell_1 : 0|16@1+ (1,0) [0|0] "" Vector__XXX

BO_ 545 bms_module_8_voltage_1: 8 Vector__XXX
 SG_ module_8_cell_8 : 48|16@1+ (1,0) [0|0] "" Vector__XXX
 SG_ module_8_cell_7 : 32|16@1+ (1,0) [0|0] "" Vector__XXX
 SG_ module_8_cell_6 : 16|16@1+ (1,0) [0|0] "" Vector__XXX
 SG_ module_8_cell_5 : 0|16@1+ (1,0) [0|0] "" Vector__XXX

BO_ 546 bms_module_8_voltage_2: 8 Vector__XXX
 SG_ module_8_cell_12 : 48|16@1+ (1,0) [0|0] "" Vector__XXX
 SG_ module_8_cell_11 : 32|16@1+ (1,0) [0|0] "" Vector__XXX
 SG_ module_8_cell_10 : 16|16@1+ (1,0) [0|0] "" Vector__XXX
 SG_ module_8_cell_9 : 0|16@1+ (1,0) [0|0] "" Vector__XXX

BO_ 547 bms_module_8_voltage_3: 8 Vector__XXX
 SG_ module_8_cell_16 : 48|16@1+ (1,0) [0|0] "" Vector__XXX
 SG_ module_8_cell_15 : 32|16@1+ (1,0) [0|0] "" Vector__XXX
 SG_ module_8_cell_14 : 16|16@1+ (1,0) [0|0] "" Vector__XXX
 SG_ module_8_cell_13 : 0|16@1+ (1,0) [0|0] "" Vector__XXX

BO_ 548 bms_module_9_voltage_0: 8 Vector__XXX
 SG_ module_9_cell_4 : 48|16@1+ (1,0) [0|0] "" Vector__XXX
 SG_ module_9_cell_3 : 32|16@1+ (1,0) [0|0] "" Vector__XXX
 SG_ module_9_cell_2 : 16|16@1+ (1,0) [0|0] "" Vector__XXX
 SG_ module_9_cell_1 : 0|16@1+ (1,0) [0|0] "" Vector__XXX

BO_ 549 bms_module_9_voltage_1: 8 Vector__XXX
 SG_ module_9_cell_8 : 48|16@1+ (1,0) [0|0] "" Vector__XXX
 SG_ module_9_cell_7 : 32|16@1+ (1,0) [0|0] "" Vector__XXX
 SG_ module_9_cell_6 : 16|16@1+ (1,0) [0|0] "" Vector__XXX
 SG_ module_9_cell_5 : 0|16@1+ (1,0) [0|0] "" Vector__XXX

BO_ 550 bms_module_9_voltage_2: 8 Vector__XXX
 SG_ module_9_cell_12 : 48|16@1+ (1,0) [0|0] "" Vector__XXX
 SG_ module_9_cell_11 : 32|16@1+ (1,0) [0|0] "" Vector__XXX
 SG_ module_9_cell_10 : 16|16@1+ (1,0) [0|0] "" Vector__XXX
 SG_ module_9_cell_9 : 0|16@1+ (1,0) [0|0] "" Vector__XXX

BO_ 551 bms_module_9_voltage_3: 8 Vector__XXX
 SG_ module_9_cell_16 : 48|16@1+ (1,0) [0|0] "" Vector__XXX
 SG_ module_9_cell_15 : 32|16@1+ (1,0) [0|0] "" Vector__XXX
 SG_ module_9_cell_14 : 16|16@1+ (1,0) [0|0] "" Vector__XXX
 SG_ module_9_cell_13 : 0|16@1+ (1,0) [0|0] "" Vector__XXX

BO_ 552 bms_module_10_voltage_0: 8 Vector__XXX
 SG_ module_10_cell_4 : 48|16@1+ (1,0) [0|0] "" Vector__XXX
 SG_ module_10_cell_3 : 32|16@1+ (1,0) [0|0] "" Vector__XXX
 SG_ module_10_cell_2 : 16|16@1+ (1,0) [0|0] "" Vector__XXX
 SG_ module_10_cell_1 : 0|16@1+ (1,0) [0|0] "" Vector__XXX

BO_ 553 bms_module_10_voltage_1: 8 Vector__XXX
 SG_ module_10_cell_8 : 48|16@1+ (1,0) [0|0] "" Vector__XXX
 SG_ module_10_cell_7 : 32|16@1+ (1,0) [0|0] "" Vector__XXX
 SG_ module_10_cell_6 : 16|16@1+ (1,0) [0|0] "" Vector__XXX
 SG_ module_10_cell_5 : 0|16@1+ (1,0) [0|0] "" Vector__XXX

BO_ 554 bms_module_10_voltage_2: 8 Vector__XXX
 SG_ module_10_cell_12 : 48|16@1+ (1,0) [0|0] "" Vector__XXX
 SG_ module_10_cell_11 : 32|16@1+ (1,0) [0|0] "" Vector__XXX
 SG_ module_10_cell_10 : 16|16@1+ (1,0) [0|0] "" Vector__XXX
 SG_ module_10_cell_9 : 0|16@1+ (1,0) [0|0] "" Vector__XXX

BO_ 555 bms_module_10_voltage_3: 8 Vector__XXX
 SG_ module_10_cell_16 : 48|16@1+ (1,0) [0|0] "" Vector__XXX
 SG_ module_10_cell_15 : 32|16@1+ (1,0) [0|0] "" Vector__XXX
 SG_ module_10_cell_14 : 16|16@1+ (1,0) [0|0] "" Vector__XXX
 SG_ module_10_cell_13 : 0|16@1+ (1,0) [0|0] "" Vector__XXX

BO_ 556 bms_module_1_temperature_0: 8 Vector__XXX
 SG_ module_1_temp_4 : 48|16@1- (1,0) [0|0] "" Vector__XXX
 SG_ module_1_temp_3 : 32|16@1- (1,0) [0|0] "" Vector__XXX
 SG_ module_1_temp_2 : 16|16@1- (1,0) [0|0] "" Vector__XXX
 SG_ module_1_temp_1 : 0|16@1- (1,0) [0|0] "" Vector__XXX

BO_ 557 bms_module_1_temperature_1: 8 Vector__XXX
 SG_ module_1_temp_8 : 48|16@1- (1,0) [0|0] "" Vector__XXX
 SG_ module_1_temp_7 : 32|16@1- (1,0) [0|0] "" Vector__XXX
 SG_ module_1_temp_6 : 16|16@1- (1,0) [0|0] "" Vector__XXX
 SG_ module_1_temp_5 : 0|16@1- (1,0) [0|0] "" Vector__XXX

BO_ 558 bms_module_1_temperature_2: 8 Vector__XXX
 SG_ module_1_temp_12 : 48|16@1- (1,0) [0|0] "" Vector__XXX
 SG_ module_1_temp_11 : 32|16@1- (1,0) [0|0] "" Vector__XXX
 SG_ module_1_temp_10 : 16|16@1- (1,0) [0|0] "" Vector__XXX
 SG_ module_1_temp_9 : 0|16@1- (1,0) [0|0] "" Vector__XXX

BO_ 559 bms_module_1_temperature_3: 8 Vector__XXX
 SG_ module_1_temp_16 : 48|16@1- (1,0) [0|0] "" Vector__XXX
 SG_ module_1_temp_15 : 32|16@1- (1,0) [0|0] "" Vector__XXX
 SG_ module_1_temp_14 : 16|16@1- (1,0) [0|0] "" Vector__XXX
 SG_ module_1_temp_13 : 0|16@1- (1,0) [0|0] "" Vector__XXX

BO_ 560 bms_module_1_temperature_4: 8 Vector__XXX
 SG_ module_1_temp_20 : 48|16@1- (1,0) [0|0] "" Vector__XXX
 SG_ module_1_temp_19 : 32|16@1- (1,0) [0|0] "" Vector__XXX
 SG_ module_1_temp_18 : 16|16@1- (1,0) [0|0] "" Vector__XXX
 SG_ module_1_temp_17 : 0|16@1- (1,0) [0|0] "" Vector__XXX

BO_ 561 bms_module_1_temperature_5: 8 Vector__XXX
 SG_ module_1_temp_24 : 48|16@1- (1,0) [0|0] "" Vector__XXX
 SG_ module_1_temp_23 : 32|16@1- (1,0) [0|0] "" Vector__XXX
 SG_ module_1_temp_22 : 16|16@1- (1,0) [0|0] "" Vector__XXX
 SG_ module_1_temp_21 : 0|16@1- (1,0) [0|0] "" Vector__XXX

BO_ 562 bms_module_1_temperature_6: 8 Vector__XXX
 SG_ module_1_temp_28 : 48|16@1- (1,0) [0|0] "" Vector__XXX
 SG_ module_1_temp_27 : 32|16@1- (1,0) [0|0] "" Vector__XXX
 SG_ module_1_temp_26 : 16|16@1- (1,0) [0|0] "" Vector__XXX
 SG_ module_1_temp_25 : 0|16@1- (1,0) [0|0] "" Vector__XXX

BO_ 563 bms_module_1_temperature_7: 8 Vector__XXX
 SG_ module_1_temp_32 : 48|16@1- (1,0) [0|0] "" Vector__XXX
 SG_ module_1_temp_31 : 32|16@1- (1,0) [0|0] "" Vector__XXX
 SG_ module_1_temp_30 : 16|16@1- (1,0) [0|0] "" Vector__XXX
 SG_ module_1_temp_29 : 0|16@1- (1,0) [0|0] "" Vector__XXX

BO_ 564 bms_module_1_temperature_8: 8 Vector__XXX
 SG_ module_1_temp_36 : 48|16@1- (1,0) [0|0] "" Vector__XXX
 SG_ module_1_temp_35 : 32|16@1- (1,0) [0|0] "" Vector__XXX
 SG_ module_1_temp_34 : 16|16@1- (1,0) [0|0] "" Vector__XXX
 SG_ module_1_temp_33 : 0|16@1- (1,0) [0|0] "" Vector__XXX

BO_ 565 bms_module_1_temperature_9: 8 Vector__XXX
 SG_ module_1_temp_40 : 48|16@1- (1,0) [0|0] "" Vector__XXX
 SG_ module_1_temp_39 : 32|16@1- (1,0) [0|0] "" Vector__XXX
 SG_ module_1_temp_38 : 16|16@1- (1,0) [0|0] "" Vector__XXX
 SG_ module_1_temp_37 : 0|16@1- (1,0) [0|0] "" Vector__XXX

BO_ 566 bms_module_1_temperature_10: 2 Vector__XXX
 SG_ module_1_temp_41 : 0|16@1- (1,0) [0|0] "" Vector__XXX

BO_ 567 bms_module_2_temperature_0: 8 Vector__XXX
 SG_ module_2_temp_4 : 48|16@1- (1,0) [0|0] "" Vector__XXX
 SG_ module_2_temp_3 : 32|16@1- (1,0) [0|0] "" Vector__XXX
 SG_ module_2_temp_2 : 16|16@1- (1,0) [0|0] "" Vector__XXX
 SG_ module_2_temp_1 : 0|16@1- (1,0) [0|0] "" Vector__XXX

BO_ 568 bms_module_2_temperature_1: 8 Vector__XXX
 SG_ module_2_temp_8 : 48|16@1- (1,0) [0|0] "" Vector__XXX
 SG_ module_2_temp_7 : 32|16@1- (1,0) [0|0] "" Vector__XXX
 SG_ module_2_temp_6 : 16|16@1- (1,0) [0|0] "" Vector__XXX
 SG_ module_2_temp_5 : 0|16@1- (1,0) [0|0] "" Vector__XXX

BO_ 569 bms_module_2_temperature_2: 8 Vector__XXX
 SG_ module_2_temp_12 : 48|16@1- (1,0) [0|0] "" Vector__XXX
 SG_ module_2_temp_11 : 32|16@1- (1,0) [0|0] "" Vector__XXX
 SG_ module_2_temp_10 : 16|16@1- (1,0) [0|0] "" Vector__XXX
 SG_ module_2_temp_9 : 0|16@1- (1,0) [0|0] "" Vector__XXX

BO_ 570 bms_module_2_temperature_3: 8 Vector__XXX
 SG_ module_2_temp_16 : 48|16@1- (1,0) [0|0] "" Vector__XXX
 SG_ module_2_temp_15 : 32|16@1- (1,0) [0|0] "" Vector__XXX
 SG_ module_2_temp_14 : 16|16@1- (1,0) [0|0] "" Vector__XXX
 SG_ module_2_temp_13 : 0|16@1- (1,0) [0|0] "" Vector__XXX

BO_ 571 bms_module_2_temperature_4: 8 Vector__XXX
 SG_ module_2_temp_20 : 48|16@1- (1,0) [0|0] "" Vector__XXX
 SG_ module_2_temp_19 : 32|16@1- (1,0) [0|0] "" Vector__XXX
 SG_ module_2_temp_18 : 16|16@1- (1,0) [0|0] "" Vector__XXX
 SG_ module_2_temp_17 : 0|16@1- (1,0) [0|0] "" Vector__XXX

BO_ 572 bms_module_2_temperature_5: 8 Vector__XXX
 SG_ module_2_temp_24 : 48|16@1- (1,0) [0|0] "" Vector__XXX
 SG_ module_2_temp_23 : 32|16@1- (1,0) [0|0] "" Vector__XXX
 SG_ module_2_temp_22 : 16|16@1- (1,0) [0|0] "" Vector__XXX
 SG_ module_2_temp_21 : 0|16@1- (1,0) [0|0] "" Vector__XXX

BO_ 573 bms_module_2_temperature_6: 8 Vector__XXX
 SG_ module_2_temp_28 : 48|16@1- (1,0) [0|0] "" Vector__XXX
 SG_ module_2_temp_27 : 32|16@1- (1,0) [0|0] "" Vector__XXX
 SG_ module_2_temp_26 : 16|16@1- (1,0) [0|0] "" Vector__XXX
 SG_ module_2_temp_25 : 0|16@1- (1,0) [0|0] "" Vector__XXX

BO_ 574 bms_module_2_temperature_7: 8 Vector__XXX
 SG_ module_2_temp_32 : 48|16@1- (1,0) [0|0] "" Vector__XXX
 SG_ module_2_temp_31 : 32|16@1- (1,0) [0|0] "" Vector__XXX
 SG_ module_2_temp_30 : 16|16@1- (1,0) [0|0] "" Vector__XXX
 SG_ module_2_temp_29 : 0|16@1- (1,0) [0|0] "" Vector__XXX

BO_ 575 bms_module_2_temperature_8: 8 Vector__XXX
 SG_ module_2_temp_36 : 48|16@1- (1,0) [0|0] "" Vector__XXX
 SG_ module_2_temp_35 : 32|16@1- (1,0) [0|0] "" Vector__XXX
 SG_ module_2_temp_34 : 16|16@1- (1,0) [0|0] "" Vector__XXX
 SG_ module_2_temp_33 : 0|16@1- (1,0) [0|0] "" Vector__XXX

BO_ 576 bms_module_2_temperature_9: 8 Vector__XXX
 SG_ module_2_temp_40 : 48|16@1- (1,0) [0|0] "" Vector__XXX
 SG_ module_2_temp_39 : 32|16@1- (1,0) [0|0] "" Vector__XXX
 SG_ module_2_temp_38 : 16|16@1- (1,0) [0|0] "" Vector__XXX
 SG_ module_2_temp_37 : 0|16@1- (1,0) [0|0] "" Vector__XXX

BO_ 577 bms_module_2_temperature_10: 2 Vector__XXX
 SG_ module_2_temp_41 : 0|16@1- (1,0) [0|0] "" Vector__XXX

BO_ 578 bms_module_3_temperature_0: 8 Vector__XXX
 SG_ module_3_temp_4 : 48|16@1- (1,0) [0|0] "" Vector__XXX
 SG_ module_3_temp_3 : 32|16@1- (1,0) [0|0] "" Vector__XXX
 SG_ module_3_temp_2 : 16|16@1- (1,0) [0|0] "" Vector__XXX
 SG_ module_3_temp_1 : 0|16@1- (1,0) [0|0] "" Vector__XXX

BO_ 579 bms_module_3_temperature_1: 8 Vector__XXX
 SG_ module_3_temp_8 : 48|16@1- (1,0) [0|0] "" Vector__XXX
 SG_ module_3_temp_7 : 32|16@1- (1,0) [0|0] "" Vector__XXX
 SG_ module_3_temp_6 : 16|16@1- (1,0) [0|0] "" Vector__XXX
 SG_ module_3_temp_5 : 0|16@1- (1,0) [0|0] "" Vector__XXX

BO_ 580 bms_module_3_temperature_2: 8 Vector__XXX
 SG_ module_3_temp_12 : 48|16@1- (1,0) [0|0] "" Vector__XXX
 SG_ module_3_temp_11 : 32|16@1- (1,0) [0|0] "" Vector__XXX
 SG_ module_3_temp_10 : 16|16@1- (1,0) [0|0] "" Vector__XXX
 SG_ module_3_temp_9 : 0|16@1- (1,0) [0|0] "" Vector__XXX

BO_ 581 bms_module_3_temperature_3: 8 Vector__XXX
 SG_ module_3_temp_16 : 48|16@1- (1,0) [0|0] "" Vector__XXX
 SG_ module_3_temp_15 : 32|16@1- (1,0) [0|0] "" Vector__XXX
 SG_ module_3_temp_14 : 16|16@1- (1,0) [0|0] "" Vector__XXX
 SG_ module_3_temp_13 : 0|16@1- (1,0) [0|0] "" Vector__XXX

BO_ 582 bms_module_3_temperature_4: 8 Vector__XXX
 SG_ module_3_temp_20 : 48|16@1- (1,0) [0|0] "" Vector__XXX
 SG_ module_3_temp_19 : 32|16@1- (1,0) [0|0] "" Vector__XXX
 SG_ module_3_temp_18 : 16|16@1- (1,0) [0|0] "" Vector__XXX
 SG_ module_3_temp_17 : 0|16@1- (1,0) [0|0] "" Vector__XXX

BO_ 583 bms_module_3_temperature_5: 8 Vector__XXX
 SG_ module_3_temp_24 : 48|16@1- (1,0) [0|0] "" Vector__XXX
 SG_ module_3_temp_23 : 32|16@1- (1,0) [0|0] "" Vector__XXX
 SG_ module_3_temp_22 : 16|16@1- (1,0) [0|0] "" Vector__XXX
 SG_ module_3_temp_21 : 0|16@1- (1,0) [0|0] "" Vector__XXX

BO_ 584 bms_module_3_temperature_6: 8 Vector__XXX
 SG_ module_3_temp_28 : 48|16@1- (1,0) [0|0] "" Vector__XXX
 SG_ module_3_temp_27 : 32|16@1- (1,0) [0|0] "" Vector__XXX
 SG_ module_3_temp_26 : 16|16@1- (1,0) [0|0] "" Vector__XXX
 SG_ module_3_temp_25 : 0|16@1- (1,0) [0|0] "" Vector__XXX

BO_ 585 bms_module_3_temperature_7: 8 Vector__XXX
 SG_ module_3_temp_32 : 48|16@1- (1,0) [0|0] "" Vector__XXX
 SG_ module_3_temp_31 : 32|16@1- (1,0) [0|0] "" Vector__XXX
 SG_ module_3_temp_30 : 16|16@1- (1,0) [0|0] "" Vector__XXX
 SG_ module_3_temp_29 : 0|16@1- (1,0) [0|0] "" Vector__XXX

BO_ 586 bms_module_3_temperature_8: 8 Vector__XXX
 SG_ module_3_temp_36 : 48|16@1- (1,0) [0|0] "" Vector__XXX
 SG_ module_3_temp_35 : 32|16@1- (1,0) [0|0] "" Vector__XXX
 SG_ module_3_temp_34 : 16|16@1- (1,0) [0|0] "" Vector__XXX
 SG_ module_3_temp_33 : 0|16@1- (1,0) [0|0] "" Vector__XXX

BO_ 587 bms_module_3_temperature_9: 8 Vector__XXX
 SG_ module_3_temp_40 : 48|16@1- (1,0) [0|0] "" Vector__XXX
 SG_ module_3_temp_39 : 32|16@1- (1,0) [0|0] "" Vector__XXX
 SG_ module_3_temp_38 : 16|16@1- (1,0) [0|0] "" Vector__XXX
 SG_ module_3_temp_37 : 0|16@1- (1,0) [0|0] "" Vector__XXX

BO_ 588 bms_module_3_temperature_10: 2 Vector__XXX
 SG_ module_3_temp_41 : 0|16@1- (1,0) [0|0] "" Vector__XXX

BO_ 589 bms_module_4_temperature_0: 8 Vector__XXX
 SG_ module_4_temp_4 : 48|16@1- (1,0) [0|0] "" Vector__XXX
 SG_ module_4_temp_3 : 32|16@1- (1,0) [0|0] "" Vector__XXX
 SG_ module_4_temp_2 : 16|16@1- (1,0) [0|0] "" Vector__XXX
 SG_ module_4_temp_1 : 0|16@1- (1,0) [0|0] "" Vector__XXX

BO_ 590 bms_module_4_temperature_1: 8 Vector__XXX
 SG_ module_4_temp_8 : 48|16@1- (1,0) [0|0] "" Vector__XXX
 SG_ module_4_temp_7 : 32|16@1- (1,0) [0|0] "" Vector__XXX
 SG_ module_4_temp_6 : 16|16@1- (1,0) [0|0] "" Vector__XXX
 SG_ module_4_temp_5 : 0|16@1- (1,0) [0|0] "" Vector__XXX

BO_ 591 bms_module_4_temperature_2: 8 Vector__XXX
 SG_ module_4_temp_12 : 48|16@1- (1,0) [0|0] "" Vector__XXX
 SG_ module_4_temp_11 : 32|16@1- (1,0) [0|0] "" Vector__XXX
 SG_ module_4_temp_10 : 16|16@1- (1,0) [0|0] "" Vector__XXX
 SG_ module_4_temp_9 : 0|16@1- (1,0) [0|0] "" Vector__XXX

BO_ 592 bms_module_4_temperature_3: 8 Vector__XXX
 SG_ module_4_temp_16 : 48|16@1- (1,0) [0|0] "" Vector__XXX
 SG_ module_4_temp_15 : 32|16@1- (1,0) [0|0] "" Vector__XXX
 SG_ module_4_temp_14 : 16|16@1- (1,0) [0|0] "" Vector__XXX
 SG_ module_4_temp_13 : 0|16@1- (1,0) [0|0] "" Vector__XXX

BO_ 593 bms_module_4_temperature_4: 8 Vector__XXX
 SG_ module_4_temp_20 : 48|16@1- (1,0) [0|0] "" Vector__XXX
 SG_ module_4_temp_19 : 32|16@1- (1,0) [0|0] "" Vector__XXX
 SG_ module_4_temp_18 : 16|16@1- (1,0) [0|0] "" Vector__XXX
 SG_ module_4_temp_17 : 0|16@1- (1,0) [0|0] "" Vector__XXX

BO_ 594 bms_module_4_temperature_5: 8 Vector__XXX
 SG_ module_4_temp_24 : 48|16@1- (1,0) [0|0] "" Vector__XXX
 SG_ module_4_temp_23 : 32|16@1- (1,0) [0|0] "" Vector__XXX
 SG_ module_4_temp_22 : 16|16@1- (1,0) [0|0] "" Vector__XXX
 SG_ module_4_temp_21 : 0|16@1- (1,0) [0|0] "" Vector__XXX

BO_ 595 bms_module_4_temperature_6: 8 Vector__XXX
 SG_ module_4_temp_28 : 48|16@1- (1,0) [0|0] "" Vector__XXX
 SG_ module_4_temp_27 : 32|16@1- (1,0) [0|0] "" Vector__XXX
 SG_ module_4_temp_26 : 16|16@1- (1,0) [0|0] "" Vector__XXX
 SG_ module_4_temp_25 : 0|16@1- (1,0) [0|0] "" Vector__XXX

BO_ 596 bms_module_4_temperature_7: 8 Vector__XXX
 SG_ module_4_temp_32 : 48|16@1- (1,0) [0|0] "" Vector__XXX
 SG_ module_4_temp_31 : 32|16@1- (1,0) [0|0] "" Vector__XXX
 SG_ module_4_temp_30 : 16|16@1- (1,0) [0|0] "" Vector__XXX
 SG_ module_4_temp_29 : 0|16@1- (1,0) [0|0] "" Vector__XXX

BO_ 597 bms_module_4_temperature_8: 8 Vector__XXX
 SG_ module_4_temp_36 : 48|16@1- (1,0) [0|0] "" Vector__XXX
 SG_ module_4_temp_35 : 32|16@1- (1,0) [0|0] "" Vector__XXX
 SG_ module_4_temp_34 : 16|16@1- (1,0) [0|0] "" Vector__XXX
 SG_ module_4_temp_33 : 0|16@1- (1,0) [0|0] "" Vector__XXX

BO_ 598 bms_module_4_temperature_9: 8 Vector__XXX
 SG_ module_4_temp_40 : 48|16@1- (1,0) [0|0] "" Vector__XXX
 SG_ module_4_temp_39 : 32|16@1- (1,0) [0|0] "" Vector__XXX
 SG_ module_4_temp_38 : 16|16@1- (1,0) [0|0] "" Vector__XXX
 SG_ module_4_temp_37 : 0|16@1- (1,0) [0|0] "" Vector__XXX

BO_ 599 bms_module_4_temperature_10: 2 Vector__XXX
 SG_ module_4_temp_41 : 0|16@1- (1,0) [0|0] "" Vector__XXX

BO_ 600 bms_module_5_temperature_0: 8 Vector__XXX
 SG_ module_5_temp_4 : 48|16@1- (1,0) [0|0] "" Vector__XXX
 SG_ module_5_temp_3 : 32|16@1- (1,0) [0|0] "" Vector__XXX
 SG_ module_5_temp_2 : 16|16@1- (1,0) [0|0] "" Vector__XXX
 SG_ module_5_temp_1 : 0|16@1- (1,0) [0|0] "" Vector__XXX

BO_ 601 bms_module_5_temperature_1: 8 Vector__XXX
 SG_ module_5_temp_8 : 48|16@1- (1,0) [0|0] "" Vector__XXX
 SG_ module_5_temp_7 : 32|16@1- (1,0) [0|0] "" Vector__XXX
 SG_ module_5_temp_6 : 16|16@1- (1,0) [0|0] "" Vector__XXX
 SG_ module_5_temp_5 : 0|16@1- (1,0) [0|0] "" Vector__XXX

BO_ 602 bms_module_5_temperature_2: 8 Vector__XXX
 SG_ module_5_temp_12 : 48|16@1- (1,0) [0|0] "" Vector__XXX
 SG_ module_5_temp_11 : 32|16@1- (1,0) [0|0] "" Vector__XXX
 SG_ module_5_temp_10 : 16|16@1- (1,0) [0|0] "" Vector__XXX
 SG_ module_5_temp_9 : 0|16@1- (1,0) [0|0] "" Vector__XXX

BO_ 603 bms_module_5_temperature_3: 8 Vector__XXX
 SG_ module_5_temp_16 : 48|16@1- (1,0) [0|0] "" Vector__XXX
 SG_ module_5_temp_15 : 32|16@1- (1,0) [0|0] "" Vector__XXX
 SG_ module_5_temp_14 : 16|16@1- (1,0) [0|0] "" Vector__XXX
 SG_ module_5_temp_13 : 0|16@1- (1,0) [0|0] "" Vector__XXX

BO_ 604 bms_module_5_temperature_4: 8 Vector__XXX
 SG_ module_5_temp_20 : 48|16@1- (1,0) [0|0] "" Vector__XXX
 SG_ module_5_temp_19 : 32|16@1- (1,0) [0|0] "" Vector__XXX
 SG_ module_5_temp_18 : 16|16@1- (1,0) [0|0] "" Vector__XXX
 SG_ module_5_temp_17 : 0|16@1- (1,0) [0|0] "" Vector__XXX

BO_ 605 bms_module_5_temperature_5: 8 Vector__XXX
 SG_ module_5_temp_24 : 48|16@1- (1,0) [0|0] "" Vector__XXX
 SG_ module_5_temp_23 : 32|16@1- (1,0) [0|0] "" Vector__XXX
 SG_ module_5_temp_22 : 16|16@1- (1,0) [0|0] "" Vector__XXX
 SG_ module_5_temp_21 : 0|16@1- (1,0) [0|0] "" Vector__XXX

BO_ 606 bms_module_5_temperature_6: 8 Vector__XXX
 SG_ module_5_temp_28 : 48|16@1- (1,0) [0|0] "" Vector__XXX
 SG_ module_5_temp_27 : 32|16@1- (1,0) [0|0] "" Vector__XXX
 SG_ module_5_temp_26 : 16|16@1- (1,0) [0|0] "" Vector__XXX
 SG_ module_5_temp_25 : 0|16@1- (1,0) [0|0] "" Vector__XXX

BO_ 607 bms_module_5_temperature_7: 8 Vector__XXX
 SG_ module_5_temp_32 : 48|16@1- (1,0) [0|0] "" Vector__XXX
 SG_ module_5_temp_31 : 32|16@1- (1,0) [0|0] "" Vector__XXX
 SG_ module_5_temp_30 : 16|16@1- (1,0) [0|0] "" Vector__XXX
 SG_ module_5_temp_29 : 0|16@1- (1,0) [0|0] "" Vector__XXX

BO_ 608 bms_module_5_temperature_8: 8 Vector__XXX
 SG_ module_5_temp_36 : 48|16@1- (1,0) [0|0] "" Vector__XXX
 SG_ module_5_temp_35 : 32|16@1- (1,0) [0|0] "" Vector__XXX
 SG_ module_5_temp_34 : 16|16@1- (1,0) [0|0] "" Vector__XXX
 SG_ module_5_temp_33 : 0|16@1- (1,0) [0|0] "" Vector__XXX

BO_ 609 bms_module_5_temperature_9: 8 Vector__XXX
 SG_ module_5_temp_40 : 48|16@1- (1,0) [0|0] "" Vector__XXX
 SG_ module_5_temp_39 : 32|16@1- (1,0) [0|0] "" Vector__XXX
 SG_ module_5_temp_38 : 16|16@1- (1,0) [0|0] "" Vector__XXX
 SG_ module_5_temp_37 : 0|16@1- (1,0) [0|0] "" Vector__XXX

BO_ 610 bms_module_5_temperature_10: 2 Vector__XXX
 SG_ module_5_temp_41 : 0|16@1- (1,0) [0|0] "" Vector__XXX

BO_ 611 bms_module_6_temperature_0: 8 Vector__XXX
 SG_ module_6_temp_4 : 48|16@1- (1,0) [0|0] "" Vector__XXX
 SG_ module_6_temp_3 : 32|16@1- (1,0) [0|0] "" Vector__XXX
 SG_ module_6_temp_2 : 16|16@1- (1,0) [0|0] "" Vector__XXX
 SG_ module_6_temp_1 : 0|16@1- (1,0) [0|0] "" Vector__XXX

BO_ 612 bms_module_6_temperature_1: 8 Vector__XXX
 SG_ module_6_temp_8 : 48|16@1- (1,0) [0|0] "" Vector__XXX
 SG_ module_6_temp_7 : 32|16@1- (1,0) [0|0] "" Vector__XXX
 SG_ module_6_temp_6 : 16|16@1- (1,0) [0|0] "" Vector__XXX
 SG_ module_6_temp_5 : 0|16@1- (1,0) [0|0] "" Vector__XXX

BO_ 613 bms_module_6_temperature_2: 8 Vector__XXX
 SG_ module_6_temp_12 : 48|16@1- (1,0) [0|0] "" Vector__XXX
 SG_ module_6_temp_11 : 32|16@1- (1,0) [0|0] "" Vector__XXX
 SG_ module_6_temp_10 : 16|16@1- (1,0) [0|0] "" Vector__XXX
 SG_ module_6_temp_9 : 0|16@1- (1,0) [0|0] "" Vector__XXX

BO_ 614 bms_module_6_temperature_3: 8 Vector__XXX
 SG_ module_6_temp_16 : 48|16@1- (1,0) [0|0] "" Vector__XXX
 SG_ module_6_temp_15 : 32|16@1- (1,0) [0|0] "" Vector__XXX
 SG_ module_6_temp_14 : 16|16@1- (1,0) [0|0] "" Vector__XXX
 SG_ module_6_temp_13 : 0|16@1- (1,0) [0|0] "" Vector__XXX

BO_ 615 bms_module_6_temperature_4: 8 Vector__XXX
 SG_ module_6_temp_20 : 48|16@1- (1,0) [0|0] "" Vector__XXX
 SG_ module_6_temp_19 : 32|16@1- (1,0) [0|0] "" Vector__XXX
 SG_ module_6_temp_18 : 16|16@1- (1,0) [0|0] "" Vector__XXX
 SG_ module_6_temp_17 : 0|16@1- (1,0) [0|0] "" Vector__XXX

BO_ 616 bms_module_6_temperature_5: 8 Vector__XXX
 SG_ module_6_temp_24 : 48|16@1- (1,0) [0|0] "" Vector__XXX
 SG_ module_6_temp_23 : 32|16@1- (1,0) [0|0] "" Vector__XXX
 SG_ module_6_temp_22 : 16|16@1- (1,0) [0|0] "" Vector__XXX
 SG_ module_6_temp_21 : 0|16@1- (1,0) [0|0] "" Vector__XXX

BO_ 617 bms_module_6_temperature_6: 8 Vector__XXX
 SG_ module_6_temp_28 : 48|16@1- (1,0) [0|0] "" Vector__XXX
 SG_ module_6_temp_27 : 32|16@1- (1,0) [0|0] "" Vector__XXX
 SG_ module_6_temp_26 : 16|16@1- (1,0) [0|0] "" Vector__XXX
 SG_ module_6_temp_25 : 0|16@1- (1,0) [0|0] "" Vector__XXX

BO_ 618 bms_module_6_temperature_7: 8 Vector__XXX
 SG_ module_6_temp_32 : 48|16@1- (1,0) [0|0] "" Vector__XXX
 SG_ module_6_temp_31 : 32|16@1- (1,0) [0|0] "" Vector__XXX
 SG_ module_6_temp_30 : 16|16@1- (1,0) [0|0] "" Vector__XXX
 SG_ module_6_temp_29 : 0|16@1- (1,0) [0|0] "" Vector__XXX

BO_ 619 bms_module_6_temperature_8: 8 Vector__XXX
 SG_ module_6_temp_36 : 48|16@1- (1,0) [0|0] "" Vector__XXX
 SG_ module_6_temp_35 : 32|16@1- (1,0) [0|0] "" Vector__XXX
 SG_ module_6_temp_34 : 16|16@1- (1,0) [0|0] "" Vector__XXX
 SG_ module_6_temp_33 : 0|16@1- (1,0) [0|0] "" Vector__XXX

BO_ 620 bms_module_6_temperature_9: 8 Vector__XXX
 SG_ module_6_temp_40 : 48|16@1- (1,0) [0|0] "" Vector__XXX
 SG_ module_6_temp_39 : 32|16@1- (1,0) [0|0] "" Vector__XXX
 SG_ module_6_temp_38 : 16|16@1- (1,0) [0|0] "" Vector__XXX
 SG_ module_6_temp_37 : 0|16@1- (1,0) [0|0] "" Vector__XXX

BO_ 621 bms_module_6_temperature_10: 2 Vector__XXX
 SG_ module_6_temp_41 : 0|16@1- (1,0) [0|0] "" Vector__XXX

BO_ 622 bms_module_7_temperature_0: 8 Vector__XXX
 SG_ module_7_temp_4 : 48|16@1- (1,0) [0|0] "" Vector__XXX
 SG_ module_7_temp_3 : 32|16@1- (1,0) [0|0] "" Vector__XXX
 SG_ module_7_temp_2 : 16|16@1- (1,0) [0|0] "" Vector__XXX
 SG_ module_7_temp_1 : 0|16@1- (1,0) [0|0] "" Vector__XXX

BO_ 623 bms_module_7_temperature_1: 8 Vector__XXX
 SG_ module_7_temp_8 : 48|16@1- (1,0) [0|0] "" Vector__XXX
 SG_ module_7_temp_7 : 32|16@1- (1,0) [0|0] "" Vector__XXX
 SG_ module_7_temp_6 : 16|16@1- (1,0) [0|0] "" Vector__XXX
 SG_ module_7_temp_5 : 0|16@1- (1,0) [0|0] "" Vector__XXX

BO_ 624 bms_module_7_temperature_2: 8 Vector__XXX
 SG_ module_7_temp_12 : 48|16@1- (1,0) [0|0] "" Vector__XXX
 SG_ module_7_temp_11 : 32|16@1- (1,0) [0|0] "" Vector__XXX
 SG_ module_7_temp_10 : 16|16@1- (1,0) [0|0] "" Vector__XXX
 SG_ module_7_temp_9 : 0|16@1- (1,0) [0|0] "" Vector__XXX

BO_ 625 bms_module_7_temperature_3: 8 Vector__XXX
 SG_ module_7_temp_16 : 48|16@1- (1,0) [0|0] "" Vector__XXX
 SG_ module_7_temp_15 : 32|16@1- (1,0) [0|0] "" Vector__XXX
 SG_ module_7_temp_14 : 16|16@1- (1,0) [0|0] "" Vector__XXX
 SG_ module_7_temp_13 : 0|16@1- (1,0) [0|0] "" Vector__XXX

BO_ 626 bms_module_7_temperature_4: 8 Vector__XXX
 SG_ module_7_temp_20 : 48|16@1- (1,0) [0|0] "" Vector__XXX
 SG_ module_7_temp_19 : 32|16@1- (1,0) [0|0] "" Vector__XXX
 SG_ module_7_temp_18 : 16|16@1- (1,0) [0|0] "" Vector__XXX
 SG_ module_7_temp_17 : 0|16@1- (1,0) [0|0] "" Vector__XXX

BO_ 627 bms_module_7_temperature_5: 8 Vector__XXX
 SG_ module_7_temp_24 : 48|16@1- (1,0) [0|0] "" Vector__XXX
 SG_ module_7_temp_23 : 32|16@1- (1,0) [0|0] "" Vector__XXX
 SG_ module_7_temp_22 : 16|16@1- (1,0) [0|0] "" Vector__XXX
 SG_ module_7_temp_21 : 0|16@1- (1,0) [0|0] "" Vector__XXX

BO_ 628 bms_module_7_temperature_6: 8 Vector__XXX
 SG_ module_7_temp_28 : 48|16@1- (1,0) [0|0] "" Vector__XXX
 SG_ module_7_temp_27 : 32|16@1- (1,0) [0|0] "" Vector__XXX
 SG_ module_7_temp_26 : 16|16@1- (1,0) [0|0] "" Vector__XXX
 SG_ module_7_temp_25 : 0|16@1- (1,0) [0|0] "" Vector__XXX

BO_ 629 bms_module_7_temperature_7: 8 Vector__XXX
 SG_ module_7_temp_32 : 48|16@1- (1,0) [0|0] "" Vector__XXX
 SG_ module_7_temp_31 : 32|16@1- (1,0) [0|0] "" Vector__XXX
 SG_ module_7_temp_30 : 16|16@1- (1,0) [0|0] "" Vector__XXX
 SG_ module_7_temp_29 : 0|16@1- (1,0) [0|0] "" Vector__XXX

BO_ 630 bms_module_7_temperature_8: 8 Vector__XXX
 SG_ module_7_temp_36 : 48|16@1- (1,0) [0|0] "" Vector__XXX
 SG_ module_7_temp_35 : 32|16@1- (1,0) [0|0] "" Vector__XXX
 SG_ module_7_temp_34 : 16|16@1- (1,0) [0|0] "" Vector__XXX
 SG_ module_7_temp_33 : 0|16@1- (1,0) [0|0] "" Vector__XXX

BO_ 631 bms_module_7_temperature_9: 8 Vector__XXX
 SG_ module_7_temp_40 : 48|16@1- (1,0) [0|0] "" Vector__XXX
 SG_ module_7_temp_39 : 32|16@1- (1,0) [0|0] "" Vector__XXX
 SG_ module_7_temp_38 : 16|16@1- (1,0) [0|0] "" Vector__XXX
 SG_ module_7_temp_37 : 0|16@1- (1,0) [0|0] "" Vector__XXX

BO_ 632 bms_module_7_temperature_10: 2 Vector__XXX
 SG_ module_7_temp_41 : 0|16@1- (1,0) [0|0] "" Vector__XXX

BO_ 633 bms_module_8_temperature_0: 8 Vector__XXX
 SG_ module_8_temp_4 : 48|16@1- (1,0) [0|0] "" Vector__XXX
 SG_ module_8_temp_3 : 32|16@1- (1,0) [0|0] "" Vector__XXX
 SG_ module_8_temp_2 : 16|16@1- (1,0) [0|0] "" Vector__XXX
 SG_ module_8_temp_1 : 0|16@1- (1,0) [0|0] "" Vector__XXX

BO_ 634 bms_module_8_temperature_1: 8 Vector__XXX
 SG_ module_8_temp_8 : 48|16@1- (1,0) [0|0] "" Vector__XXX
 SG_ module_8_temp_7 : 32|16@1- (1,0) [0|0] "" Vector__XXX
 SG_ module_8_temp_6 : 16|16@1- (1,0) [0|0] "" Vector__XXX
 SG_ module_8_temp_5 : 0|16@1- (1,0) [0|0] "" Vector__XXX

BO_ 635 bms_module_8_temperature_2: 8 Vector__XXX
 SG_ module_8_temp_12 : 48|16@1- (1,0) [0|0] "" Vector__XXX
 SG_ module_8_temp_11 : 32|16@1- (1,0) [0|0] "" Vector__XXX
 SG_ module_8_temp_10 : 16|16@1- (1,0) [0|0] "" Vector__XXX
 SG_ module_8_temp_9 : 0|16@1- (1,0) [0|0] "" Vector__XXX

BO_ 636 bms_module_8_temperature_3: 8 Vector__XXX
 SG_ module_8_temp_16 : 48|16@1- (1,0) [0|0] "" Vector__XXX
 SG_ module_8_temp_15 : 32|16@1- (1,0) [0|0] "" Vector__XXX
 SG_ module_8_temp_14 : 16|16@1- (1,0) [0|0] "" Vector__XXX
 SG_ module_8_temp_13 : 0|16@1- (1,0) [0|0] "" Vector__XXX

BO_ 637 bms_module_8_temperature_4: 8 Vector__XXX
 SG_ module_8_temp_20 : 48|16@1- (1,0) [0|0] "" Vector__XXX
 SG_ module_8_temp_19 : 32|16@1- (1,0) [0|0] "" Vector__XXX
 SG_ module_8_temp_18 : 16|16@1- (1,0) [0|0] "" Vector__XXX
 SG_ module_8_temp_17 : 0|16@1- (1,0) [0|0] "" Vector__XXX

BO_ 638 bms_module_8_temperature_5: 8 Vector__XXX
 SG_ module_8_temp_24 : 48|16@1- (1,0) [0|0] "" Vector__XXX
 SG_ module_8_temp_23 : 32|16@1- (1,0) [0|0] "" Vector__XXX
 SG_ module_8_temp_22 : 16|16@1- (1,0) [0|0] "" Vector__XXX
 SG_ module_8_temp_21 : 0|16@1- (1,0) [0|0] "" Vector__XXX

BO_ 639 bms_module_8_temperature_6: 8 Vector__XXX
 SG_ module_8_temp_28 : 48|16@1- (1,0) [0|0] "" Vector__XXX
 SG_ module_8_temp_27 : 32|16@1- (1,0) [0|0] "" Vector__XXX
 SG_ module_8_temp_26 : 16|16@1- (1,0) [0|0] "" Vector__XXX
 SG_ module_8_temp_25 : 0|16@1- (1,0) [0|0] "" Vector__XXX

BO_ 640 bms_module_8_temperature_7: 8 Vector__XXX
 SG_ module_8_temp_32 : 48|16@1- (1,0) [0|0] "" Vector__XXX
 SG_ module_8_temp_31 : 32|16@1- (1,0) [0|0] "" Vector__XXX
 SG_ module_8_temp_30 : 16|16@1- (1,0) [0|0] "" Vector__XXX
 SG_ module_8_temp_29 : 0|16@1- (1,0) [0|0] "" Vector__XXX

BO_ 641 bms_module_8_temperature_8: 8 Vector__XXX
 SG_ module_8_temp_36 : 48|16@1- (1,0) [0|0] "" Vector__XXX
 SG_ module_8_temp_35 : 32|16@1- (1,0) [0|0] "" Vector__XXX
 SG_ module_8_temp_34 : 16|16@1- (1,0) [0|0] "" Vector__XXX
 SG_ module_8_temp_33 : 0|16@1- (1,0) [0|0] "" Vector__XXX

BO_ 642 bms_module_8_temperature_9: 8 Vector__XXX
 SG_ module_8_temp_40 : 48|16@1- (1,0) [0|0] "" Vector__XXX
 SG_ module_8_temp_39 : 32|16@1- (1,0) [0|0] "" Vector__XXX
 SG_ module_8_temp_38 : 16|16@1- (1,0) [0|0] "" Vector__XXX
 SG_ module_8_temp_37 : 0|16@1- (1,0) [0|0] "" Vector__XXX

BO_ 643 bms_module_8_temperature_10: 2 Vector__XXX
 SG_ module_8_temp_41 : 0|16@1- (1,0) [0|0] "" Vector__XXX

BO_ 644 bms_module_9_temperature_0: 8 Vector__XXX
 SG_ module_9_temp_4 : 48|16@1- (1,0) [0|0] "" Vector__XXX
 SG_ module_9_temp_3 : 32|16@1- (1,0) [0|0] "" Vector__XXX
 SG_ module_9_temp_2 : 16|16@1- (1,0) [0|0] "" Vector__XXX
 SG_ module_9_temp_1 : 0|16@1- (1,0) [0|0] "" Vector__XXX

BO_ 645 bms_module_9_temperature_1: 8 Vector__XXX
 SG_ module_9_temp_8 : 48|16@1- (1,0) [0|0] "" Vector__XXX
 SG_ module_9_temp_7 : 32|16@1- (1,0) [0|0] "" Vector__XXX
 SG_ module_9_temp_6 : 16|16@1- (1,0) [0|0] "" Vector__XXX
 SG_ module_9_temp_5 : 0|16@1- (1,0) [0|0] "" Vector__XXX

BO_ 646 bms_module_9_temperature_2: 8 Vector__XXX
 SG_ module_9_temp_12 : 48|16@1- (1,0) [0|0] "" Vector__XXX
 SG_ module_9_temp_11 : 32|16@1- (1,0) [0|0] "" Vector__XXX
 SG_ module_9_temp_10 : 16|16@1- (1,0) [0|0] "" Vector__XXX
 SG_ module_9_temp_9 : 0|16@1- (1,0) [0|0] "" Vector__XXX

BO_ 647 bms_module_9_temperature_3: 8 Vector__XXX
 SG_ module_9_temp_16 : 48|16@1- (1,0) [0|0] "" Vector__XXX
 SG_ module_9_temp_15 : 32|16@1- (1,0) [0|0] "" Vector__XXX
 SG_ module_9_temp_14 : 16|16@1- (1,0) [0|0] "" Vector__XXX
 SG_ module_9_temp_13 : 0|16@1- (1,0) [0|0] "" Vector__XXX

BO_ 648 bms_module_9_temperature_4: 8 Vector__XXX
 SG_ module_9_temp_20 : 48|16@1- (1,0) [0|0] "" Vector__XXX
 SG_ module_9_temp_19 : 32|16@1- (1,0) [0|0] "" Vector__XXX
 SG_ module_9_temp_18 : 16|16@1- (1,0) [0|0] "" Vector__XXX
 SG_ module_9_temp_17 : 0|16@1- (1,0) [0|0] "" Vector__XXX

BO_ 649 bms_module_9_temperature_5: 8 Vector__XXX
 SG_ module_9_temp_24 : 48|16@1- (1,0) [0|0] "" Vector__XXX
 SG_ module_9_temp_23 : 32|16@1- (1,0) [0|0] "" Vector__XXX
 SG_ module_9_temp_22 : 16|16@1- (1,0) [0|0] "" Vector__XXX
 SG_ module_9_temp_21 : 0|16@1- (1,0) [0|0] "" Vector__XXX

BO_ 650 bms_module_9_temperature_6: 8 Vector__XXX
 SG_ module_9_temp_28 : 48|16@1- (1,0) [0|0] "" Vector__XXX
 SG_ module_9_temp_27 : 32|16@1- (1,0) [0|0] "" Vector__XXX
 SG_ module_9_temp_26 : 16|16@1- (1,0) [0|0] "" Vector__XXX
 SG_ module_9_temp_25 : 0|16@1- (1,0) [0|0] "" Vector__XXX

BO_ 651 bms_module_9_temperature_7: 8 Vector__XXX
 SG_ module_9_temp_32 : 48|16@1- (1,0) [0|0] "" Vector__XXX
 SG_ module_9_temp_31 : 32|16@1- (1,0) [0|0] "" Vector__XXX
 SG_ module_9_temp_30 : 16|16@1- (1,0) [0|0] "" Vector__XXX
 SG_ module_9_temp_29 : 0|16@1- (1,0) [0|0] "" Vector__XXX

BO_ 652 bms_module_9_temperature_8: 8 Vector__XXX
 SG_ module_9_temp_36 : 48|16@1- (1,0) [0|0] "" Vector__XXX
 SG_ module_9_temp_35 : 32|16@1- (1,0) [0|0] "" Vector__XXX
 SG_ module_9_temp_34 : 16|16@1- (1,0) [0|0] "" Vector__XXX
 SG_ module_9_temp_33 : 0|16@1- (1,0) [0|0] "" Vector__XXX

BO_ 653 bms_module_9_temperature_9: 8 Vector__XXX
 SG_ module_9_temp_40 : 48|16@1- (1,0) [0|0] "" Vector__XXX
 SG_ module_9_temp_39 : 32|16@1- (1,0) [0|0] "" Vector__XXX
 SG_ module_9_temp_38 : 16|16@1- (1,0) [0|0] "" Vector__XXX
 SG_ module_9_temp_37 : 0|16@1- (1,0) [0|0] "" Vector__XXX

BO_ 654 bms_module_9_temperature_10: 2 Vector__XXX
 SG_ module_9_temp_41 : 0|16@1- (1,0) [0|0] "" Vector__XXX

BO_ 655 bms_module_10_temperature_0: 8 Vector__XXX
 SG_ module_10_temp_4 : 48|16@1- (1,0) [0|0] "" Vector__XXX
 SG_ module_10_temp_3 : 32|16@1- (1,0) [0|0] "" Vector__XXX
 SG_ module_10_temp_2 : 16|16@1- (1,0) [0|0] "" Vector__XXX
 SG_ module_10_temp_1 : 0|16@1- (1,0) [0|0] "" Vector__XXX

BO_ 656 bms_module_10_temperature_1: 8 Vector__XXX
 SG_ module_10_temp_8 : 48|16@1- (1,0) [0|0] "" Vector__XXX
 SG_ module_10_temp_7 : 32|16@1- (1,0) [0|0] "" Vector__XXX
 SG_ module_10_temp_6 : 16|16@1- (1,0) [0|0] "" Vector__XXX
 SG_ module_10_temp_5 : 0|16@1- (1,0) [0|0] "" Vector__XXX

BO_ 657 bms_module_10_temperature_2: 8 Vector__XXX
 SG_ module_10_temp_12 : 48|16@1- (1,0) [0|0] "" Vector__XXX
 SG_ module_10_temp_11 : 32|16@1- (1,0) [0|0] "" Vector__XXX
 SG_ module_10_temp_10 : 16|16@1- (1,0) [0|0] "" Vector__XXX
 SG_ module_10_temp_9 : 0|16@1- (1,0) [0|0] "" Vector__XXX

BO_ 658 bms_module_10_temperature_3: 8 Vector__XXX
 SG_ module_10_temp_16 : 48|16@1- (1,0) [0|0] "" Vector__XXX
 SG_ module_10_temp_15 : 32|16@1- (1,0) [0|0] "" Vector__XXX
 SG_ module_10_temp_14 : 16|16@1- (1,0) [0|0] "" Vector__XXX
 SG_ module_10_temp_13 : 0|16@1- (1,0) [0|0] "" Vector__XXX

BO_ 659 bms_module_10_temperature_4: 8 Vector__XXX
 SG_ module_10_temp_20 : 48|16@1- (1,0) [0|0] "" Vector__XXX
 SG_ module_10_temp_19 : 32|16@1- (1,0) [0|0] "" Vector__XXX
 SG_ module_10_temp_18 : 16|16@1- (1,0) [0|0] "" Vector__XXX
 SG_ module_10_temp_17 : 0|16@1- (1,0) [0|0] "" Vector__XXX

BO_ 660 bms_module_10_temperature_5: 8 Vector__XXX
 SG_ module_10_temp_24 : 48|16@1- (1,0) [0|0] "" Vector__XXX
 SG_ module_10_temp_23 : 32|16@1- (1,0) [0|0] "" Vector__XXX
 SG_ module_10_temp_22 : 16|16@1- (1,0) [0|0] "" Vector__XXX
 SG_ module_10_temp_21 : 0|16@1- (1,0) [0|0] "" Vector__XXX

BO_ 661 bms_module_10_temperature_6: 8 Vector__XXX
 SG_ module_10_temp_28 : 48|16@1- (1,0) [0|0] "" Vector__XXX
 SG_ module_10_temp_27 : 32|16@1- (1,0) [0|0] "" Vector__XXX
 SG_ module_10_temp_26 : 16|16@1- (1,0) [0|0] "" Vector__XXX
 SG_ module_10_temp_25 : 0|16@1- (1,0) [0|0] "" Vector__XXX

BO_ 662 bms_module_10_temperature_7: 8 Vector__XXX
 SG_ module_10_temp_32 : 48|16@1- (1,0) [0|0] "" Vector__XXX
 SG_ module_10_temp_31 : 32|16@1- (1,0) [0|0] "" Vector__XXX
 SG_ module_10_temp_30 : 16|16@1- (1,0) [0|0] "" Vector__XXX
 SG_ module_10_temp_29 : 0|16@1- (1,0) [0|0] "" Vector__XXX

BO_ 663 bms_module_10_temperature_8: 8 Vector__XXX
 SG_ module_10_temp_36 : 48|16@1- (1,0) [0|0] "" Vector__XXX
 SG_ module_10_temp_35 : 32|16@1- (1,0) [0|0] "" Vector__XXX
 SG_ module_10_temp_34 : 16|16@1- (1,0) [0|0] "" Vector__XXX
 SG_ module_10_temp_33 : 0|16@1- (1,0) [0|0] "" Vector__XXX

BO_ 664 bms_module_10_temperature_9: 8 Vector__XXX
 SG_ module_10_temp_40 : 48|16@1- (1,0) [0|0] "" Vector__XXX
 SG_ module_10_temp_39 : 32|16@1- (1,0) [0|0] "" Vector__XXX
 SG_ module_10_temp_38 : 16|16@1- (1,0) [0|0] "" Vector__XXX
 SG_ module_10_temp_37 : 0|16@1- (1,0) [0|0] "" Vector__XXX

BO_ 665 bms_module_10_temperature_10: 2 Vector__XXX
 SG_ module_10_temp_41 : 0|16@1- (1,0) [0|0] "" Vector__XXX

BO_ 1280 ebs_pressure_status: 8 Vector__XXX
 SG_ ebs_pressure_4 : 48|16@1- (0.0625,0) [0|0] "bar" Vector__XXX
 SG_ ebs_pressure_3 : 32|16@1- (0.0625,0) [0|0] "bar" Vector__XXX
 SG_ ebs_pressure_2 : 16|16@1- (0.0625,0) [0|0] "bar" Vector__XXX
 SG_ ebs_pressure_1 : 0|16@1- (0.0625,0) [0|0] "bar" Vector__XXX

BO_ 1313 IVTCurrent: 6 Vector__XXX
 SG_ current : 23|32@0- (-0.001,0) [0|0] "A" Vector__XXX
 SG_ counter : 7|16@0+ (1,0) [0|0] "" Vector__XXX

BO_ 1314 IVTVoltage1: 6 Vector__XXX
 SG_ voltage1 : 23|32@0- (0.001,0) [0|0] "V" Vector__XXX
 SG_ counter : 7|16@0+ (1,0) [0|0] "" Vector__XXX

BO_ 1315 IVTVoltage2: 6 Vector__XXX
 SG_ voltage2 : 23|32@0- (0.001,0) [0|0] "V" Vector__XXX
 SG_ counter : 7|16@0+ (1,0) [0|0] "" Vector__XXX

BO_ 1316 IVTVoltage3: 6 Vector__XXX
 SG_ voltage3 : 23|32@0- (0.001,0) [0|0] "V" Vector__XXX
 SG_ counter : 7|16@0+ (1,0) [0|0] "" Vector__XXX

BO_ 1317 IVTTemperature: 6 Vector__XXX
 SG_ temperature : 23|32@0- (0.1,0) [0|0] "degC" Vector__XXX
 SG_ counter : 7|16@0+ (1,0) [0|0] "" Vector__XXX

BO_ 2550588916 Charger_Limits: 8 BMS
 SG_ Control : 32|8@1+ (1,0) [0|0] "" Vector__XXX
 SG_ MaxCurrent : 23|16@0+ (0.1,0) [0|0] "A" Vector__XXX
 SG_ MaxVoltage : 7|16@0+ (0.1,0) [0|0] "V" Vector__XXX

BO_ 2566869221 Charger_Status: 8 ElconCharger
 SG_ CommunicationState : 36|1@1+ (1,0) [0|0] "" Vector__XXX
 SG_ State : 35|1@1+ (1,0) [0|0] "" Vector__XXX
 SG_ InputVoltage : 34|1@1+ (1,0) [0|0] "" Vector__XXX
 SG_ Temperature : 33|1@1+ (1,0) [0|0] "" Vector__XXX
 SG_ HWStatus : 32|1@1+ (1,0) [0|0] "" Vector__XXX
 SG_ OutputCurrent : 23|16@0+ (0.1,0) [0|0] "A" Vector__XXX
 SG_ OutputVoltage : 7|16@0+ (0.1,0) [0|0] "V" Vector__XXX

CM_ BO_ 1 "BMS message for cell data.";
CM_ BO_ 2 "BMS message for accumulator voltage.";
CM_ BO_ 3 "BMS message for accumulator temperature.";
CM_ BO_ 4 "Accumulator Faults";
CM_ BO_ 5 "BMS message for BMS state.";
CM_ BO_ 9 "PCU brake: position + 2 pressure sensors (centi-percent) + status flags";
CM_ BO_ 10 "BSPD message.";
CM_ BO_ 11 "RES message for RES state.";
CM_ BO_ 16 "Dash state + buttons and switches";
CM_ BO_ 22 "LVPDB message for voltages of 24v bus and 12v bus";
CM_ BO_ 23 "LVPDB message for currents of LV, SH, LT, BM_L";
CM_ BO_ 24 "LVPDB message for currents of SM, AF1_AF2, CP_RF";
CM_ BO_ 30 "Linear Potentiometer Front.";
CM_ BO_ 31 "Linear Potentiometer Rear.";
CM_ BO_ 32 "Message for front left tire temp data.";
CM_ BO_ 33 "Message for front right tire temp data.";
CM_ BO_ 34 "Message for rear left tire temp data.";
CM_ BO_ 35 "Message for rear right tire temp data.";
CM_ BO_ 36 "Front wheel speeds (uint16, 0.01 mph/LSB) + direction flags.";
CM_ SG_ 36 wss_dir_flags "bit0: left wheel direction (0=fwd, 1=rev); bit1: right wheel direction";
CM_ BO_ 37 "Rear wheel speeds (uint16, 0.01 mph/LSB) + direction flags.";
CM_ SG_ 37 wss_dir_flags "bit0: left wheel direction (0=fwd, 1=rev); bit1: right wheel direction";
CM_ BO_ 38 "IMU acceleration (LSM6DSOX, FS=2g, 0.061 mg/LSB).";
CM_ BO_ 39 "REAR IMU acceleration (LSM6DSOX, FS=2g, 0.061 mg/LSB).";
CM_ BO_ 40 "IMU gyro (LSM6DSOX, FS=2000dps, 70 mdps/LSB).";
CM_ BO_ 41 "REAR IMU gyro (LSM6DSOX, FS=2000dps, 70 mdps/LSB).";
CM_ BO_ 42 "Magnetometer (LIS3MDL, FS=16gauss, 0.5844 mG/LSB).";
CM_ BO_ 43 "REAR Magnetometer (LIS3MDL, FS=16gauss, 0.5844 mG/LSB).";
CM_ BO_ 45 "DART message for Tachometer measurements first 4 fan speeds.";
CM_ BO_ 46 "DART message for Tachometer measurements 5th fan speed.";
CM_ BO_ 52 "BBB TPS Chip";
CM_ BO_ 53 "PCU TPS Chip";
CM_ BO_ 54 "Dash TPS Chip";
CM_ BO_ 55 "DCU TPS Chip";
CM_ BO_ 56 "PCU RAW ACC ADC";
CM_ BO_ 57 "PCU raw pedal sensor voltages (sensor-side mV): APPS1/2, brake 1/2";
CM_ BO_ 64 "GPS lat/lon as int32 * 1e7 deg (~11mm/LSB globally).";
CM_ BO_ 65 "GPS altitude (cm) + horizontal/vertical DOP (x100).";
CM_ BO_ 66 "GPS speed (0.01 km/h) and course-over-ground (0.01 deg).";
CM_ BO_ 67 "GPS Time data message (UTC).";
CM_ BO_ 68 "GPS Date data message.";
CM_ BO_ 69 "GPS fix quality, satellite counts, validity flags, position DOP.";
CM_ SG_ 69 fix_mode "1=NoFix, 2=2D, 3=3D";
CM_ SG_ 69 fix_type "0=Invalid, 1=GPS, 2=DGPS, 3=PPS";
CM_ BO_ 71 "Fusion AHRS orientation quaternion (w, x, y, z).";
CM_ BO_ 72 "Fusion AHRS Euler angles (0.01 deg/LSB).";
CM_ BO_ 73 "Fusion linear acceleration (gravity removed, body frame, mg).";
CM_ BO_ 74 "Fusion linear acceleration (gravity removed, earth frame, mg).";
CM_ BO_ 75 "Fusion AHRS internal flags + accel/mag rejection errors.";
CM_ SG_ 75 flags "bit0 startup, bit1 angRateRecov, bit2 accelRecov, bit3 magRecov, bit4 accelIgnored, bit5 magIgnored";
CM_ BO_ 76 "LSM6DSOX IMU and LIS3MDL magnetometer die temperatures (0.01 degC/LSB).";
CM_ BO_ 77 "REAR LSM6DSOX IMU and LIS3MDL magnetometer die temperatures (0.01 degC/LSB).";
CM_ BO_ 78 "Steering encoder filtered angle, raw angle, and AGC gain.";
CM_ BO_ 79 "Steering encoder magnet status flags and CORDIC magnitude.";
CM_ BO_ 80 "REAR GPS lat/lon as int32 * 1e7 deg (~11mm/LSB globally).";
CM_ BO_ 81 "REAR GPS altitude (cm) + horizontal/vertical DOP (x100).";
CM_ BO_ 82 "REAR GPS speed (0.01 km/h) and course-over-ground (0.01 deg).";
CM_ BO_ 83 "REAR GPS Time data message (UTC).";
CM_ BO_ 84 "REAR GPS Date data message.";
CM_ BO_ 85 "REAR GPS fix quality, satellite counts, validity flags, position DOP.";
CM_ SG_ 85 fix_mode "1=NoFix, 2=2D, 3=3D";
CM_ SG_ 85 fix_type "0=Invalid, 1=GPS, 2=DGPS, 3=PPS";
CM_ BO_ 87 "REAR Fusion AHRS orientation quaternion (w, x, y, z).";
CM_ BO_ 88 "REAR Fusion AHRS Euler angles (0.01 deg/LSB).";
CM_ BO_ 89 "REAR Fusion linear acceleration (gravity removed, body frame, mg).";
CM_ BO_ 90 "REAR Fusion linear acceleration (gravity removed, earth frame, mg).";
CM_ BO_ 91 "REAR Fusion AHRS internal flags + accel/mag rejection errors.";
CM_ SG_ 91 flags "bit0 startup, bit1 angRateRecov, bit2 accelRecov, bit3 magRecov, bit4 accelIgnored, bit5 magIgnored";
CM_ SG_ 160 INV_Gate_Driver_Board "Gate Driver Board Temperature";
CM_ SG_ 160 INV_Module_C "IGBT Module C Temperature";
CM_ SG_ 160 INV_Module_B "IGBT Module B Temperature";
CM_ SG_ 160 INV_Module_A "IGBT Module A Temperature";
CM_ SG_ 161 INV_RTD3_Temperature "RTD input 3 (PT1000) Temperature";
CM_ SG_ 161 INV_RTD2_Temperature "RTD input 2 (PT1000) Temperature";
CM_ SG_ 161 INV_RTD1_Temperature "RTD input 1 (PT1000) Temperature";
CM_ SG_ 161 INV_Control_Board_Temperature "Control Board Temperature";
CM_ SG_ 162 INV_Torque_Shudder "Shudder compensation value of torque";
CM_ SG_ 162 INV_Motor_Temperature "Motor Temperature Sensor";
CM_ SG_ 162 INV_RTD5_Temperature "RTD 5 (PT100) Temperature (Gen 2 only)";
CM_ SG_ 162 INV_RTD4_Temperature "RTD 4 (PT100) Temperature (Gen 2 only)";
CM_ SG_ 163 INV_Analog_Input_6 "Voltage on Analog Input #6";
CM_ SG_ 163 INV_Analog_Input_5 "Voltage on Analog Input #5";
CM_ SG_ 163 INV_Analog_Input_4 "Voltage on Analog Input #4";
CM_ SG_ 163 INV_Analog_Input_3 "Voltage on Analog Input #3";
CM_ SG_ 163 INV_Analog_Input_2 "Voltage on Analog Input #2";
CM_ SG_ 163 INV_Analog_Input_1 "Voltage on Analog Input #1";
CM_ SG_ 164 INV_Digital_Input_8 "Status of Digital Input #8";
CM_ SG_ 164 INV_Digital_Input_7 "Status of Digital Input #7";
CM_ SG_ 164 INV_Digital_Input_6 "Status of Digital Input #6";
CM_ SG_ 164 INV_Digital_Input_5 "Status of Digital Input #5";
CM_ SG_ 164 INV_Digital_Input_4 "Status of Digital Input #4";
CM_ SG_ 164 INV_Digital_Input_3 "Status of Digital Input #3";
CM_ SG_ 164 INV_Digital_Input_2 "Status of Digital Input #2";
CM_ SG_ 164 INV_Digital_Input_1 "Status of Digital Input #1";
CM_ SG_ 165 INV_Delta_Resolver_Filtered "Used in calibration of resolver angle adjustment.";
CM_ SG_ 165 INV_Electrical_Output_Frequency "The actual electrical frequency of the inverter";
CM_ SG_ 165 INV_Motor_Speed "The measured speed of the motor";
CM_ SG_ 165 INV_Motor_Angle_Electrical "The Electrical Angle of the motor as read by the encoder or resolver";
CM_ SG_ 166 INV_DC_Bus_Current "The Calculated DC Bus Current";
CM_ SG_ 166 INV_Phase_C_Current "The measured value of Phase C current";
CM_ SG_ 166 INV_Phase_B_Current "The measured value of Phase B current";
CM_ SG_ 166 INV_Phase_A_Current "The measured value of Phase A current";
CM_ SG_ 167 INV_VBC_Vq_Voltage "Measured value of the voltage between Phase B and Phase C";
CM_ SG_ 167 INV_VAB_Vd_Voltage "Measured value of the voltage betwen phase A and Phase B";
CM_ SG_ 167 INV_Output_Voltage "The calculated value of the output voltage, in peak line-neutral volts";
CM_ SG_ 167 INV_DC_Bus_Voltage "The actual measured value of the DC bus voltage";
CM_ SG_ 168 INV_Iq "The measured Iq current";
CM_ SG_ 168 INV_Id "The measured Id current";
CM_ SG_ 168 INV_Flux_Feedback "The estimated flux";
CM_ SG_ 168 INV_Flux_Command "The commanded flux";
CM_ SG_ 169 INV_Reference_Voltage_12_0 "12V Input Voltage";
CM_ SG_ 169 INV_Reference_Voltage_5_0 "Transducer voltage";
CM_ SG_ 169 INV_Reference_Voltage_2_5 "Internal reference voltage";
CM_ SG_ 169 INV_Reference_Voltage_1_5 "Internal reference voltage";
CM_ SG_ 170 INV_Low_Speed_Limiting "0 = Not Limiting, 1 = Current limiting due to low motor speed";
CM_ SG_ 170 INV_Max_Speed_Limiting "0 = Not Limiting, 1 = torque limiting due to maximum speed";
CM_ SG_ 170 INV_BMS_Torque_Limiting "0 = Not Limiting, 1 = Limiting";
CM_ SG_ 170 INV_BMS_Active "0 = BMS Not Active, 1 = BMS Active";
CM_ SG_ 170 INV_Direction_Command "1 = Forward
0 = 'Reverse' if inverter enabled  & 'Stopped' if inverter is disabled";
CM_ SG_ 170 INV_Inverter_Enable_Lockout "0=Lockout Disabled, 1=Lockout Enabled";
CM_ SG_ 170 INV_Start_Mode_Active "If in Key Switch Mode 1 then indicates status of Start input being applied.  0 = not active, 1 = active";
CM_ SG_ 170 INV_Inverter_Enable_State "0=Inverter Disabled, 
1=Inverter Enabled";
CM_ SG_ 170 INV_Rolling_Counter "The current rolling counter value.";
CM_ SG_ 170 INV_Inverter_Command_Mode "0=CAN mode, 1=VSM mode";
CM_ SG_ 170 INV_Inverter_Discharge_State "0 = Disabled, 1 = Enabled, 2 = Speed Check, 3 = Active, 4 = Complete";
CM_ SG_ 170 INV_Inverter_Run_Mode "0=Torque Mode, 1=Speed Mode";
CM_ SG_ 170 INV_Relay_6_Status "0=OFF, 1=ON";
CM_ SG_ 170 INV_Relay_5_Status "0=OFF, 1=ON";
CM_ SG_ 170 INV_Relay_4_Status "0=OFF, 1=ON";
CM_ SG_ 170 INV_Relay_3_Status "0=OFF, 1=ON";
CM_ SG_ 170 INV_Relay_2_Status "0=OFF, 1=ON";
CM_ SG_ 170 INV_Relay_1_Status "0=OFF, 1=ON";
CM_ SG_ 170 INV_Inverter_State "Different states for the inverter state machine";
CM_ SG_ 170 INV_PWM_Frequency "The inverter PWM frequency";
CM_ SG_ 170 INV_VSM_State "Different states for the vehicle state machine";
CM_ SG_ 171 INV_Run_Fault_Hi "Each bit represents a fault. Please refer to PM100 Users Manual for details.";
CM_ SG_ 171 INV_Run_Fault_Lo "Each bit represents a fault. Please refer to PM100 Users Manual for details.";
CM_ SG_ 171 INV_Post_Fault_Hi "Each bit represents a fault. Please refer to PM100 Users Manual for details.";
CM_ SG_ 171 INV_Post_Fault_Lo "Each bit represents a fault. Please refer to PM100 Users Manual for details.";
CM_ SG_ 172 INV_Power_On_Timer "Updated every 3 msec. This will roll over in approximately 150 days!";
CM_ SG_ 172 INV_Torque_Feedback "Estimated motor torque feedback";
CM_ SG_ 172 INV_Commanded_Torque "The commanded Torque";
CM_ SG_ 173 INV_Iq_Command "The commanded Q-axis current";
CM_ SG_ 173 INV_Id_Command "The commanded D-axis current";
CM_ SG_ 173 INV_Flux_Weakening_Output "This is the current output of the flux regulator.";
CM_ SG_ 173 INV_Modulation_Index "This is the modulation index. The scale factor is x100. To get the actual modulation index divide the value by 100.";
CM_ BO_ 176 "To enable fast message set CAN ACTIVE MSGS HI WORD to 0xFFFE.  Setting to default value of 0xFFFF will disable the fast message.";
CM_ BO_ 192 "The command message is used to transmit data to the controller. This message is sent from a user supplied external controller to the PMxxx controller.";
CM_ BO_ 193 "Parameter Message sent as needed by VCU to request info, change EEPROM, or command a function.";
CM_ BO_ 194 "The inverter response to each Parameter message that is received.";
CM_ SG_ 194 INV_Data_Response "All EEPROM data is 16 bits and is contained in bytes 4 and 5. Bytes 6 and 7 should be ignored.";
CM_ SG_ 194 INV_Write_Success "0=Write failure, 1=Success";
CM_ SG_ 194 INV_Parameter_Address_Response "Valid EEPROM Parameter CAN addresses are between 100 and 499.";
CM_ BO_ 208 "PCU heartbeat";
CM_ BO_ 209 "Dash Heartbeat";
CM_ BO_ 210 "LVPDB Heartbeat";
CM_ BO_ 211 "DCU Heartbeat";
CM_ BO_ 212 "Front Sensor Heartbeat";
CM_ BO_ 213 "Rear Sensor Heartbeat";
CM_ BO_ 224 "PING PONG counter1.";
CM_ BO_ 225 "PING PONG counter2.";
CM_ BO_ 226 "PING PONG counter3.";
CM_ BO_ 227 "PING PONG counter4.";
CM_ BO_ 469 "Response from Delphi DC/DC converter.";
CM_ BO_ 471 "Enable message sent to Delphi DC/DC converter.";
CM_ BO_ 514 "Message sent by BMS for inverter DC current limiting.";
CM_ SG_ 514 INV_Max_Charge_Current "Maximum charge current from BMS";
CM_ SG_ 514 INV_Max_Discharge_Current "Maximum discharge current from BMS";
CM_ BO_ 516 "BMS message for accumulator voltage.";
CM_ BO_ 517 "BMS message for accumulator voltage.";
CM_ BO_ 518 "BMS message for accumulator voltage.";
CM_ BO_ 519 "BMS message for accumulator voltage.";
CM_ BO_ 520 "BMS message for accumulator voltage.";
CM_ BO_ 521 "BMS message for accumulator voltage.";
CM_ BO_ 522 "BMS message for accumulator voltage.";
CM_ BO_ 523 "BMS message for accumulator voltage.";
CM_ BO_ 524 "BMS message for accumulator voltage.";
CM_ BO_ 525 "BMS message for accumulator voltage.";
CM_ BO_ 526 "BMS message for accumulator voltage.";
CM_ BO_ 527 "BMS message for accumulator voltage.";
CM_ BO_ 528 "BMS message for accumulator voltage.";
CM_ BO_ 529 "BMS message for accumulator voltage.";
CM_ BO_ 530 "BMS message for accumulator voltage.";
CM_ BO_ 531 "BMS message for accumulator voltage.";
CM_ BO_ 532 "BMS message for accumulator voltage.";
CM_ BO_ 533 "BMS message for accumulator voltage.";
CM_ BO_ 534 "BMS message for accumulator voltage.";
CM_ BO_ 535 "BMS message for accumulator voltage.";
CM_ BO_ 536 "BMS message for accumulator voltage.";
CM_ BO_ 537 "BMS message for accumulator voltage.";
CM_ BO_ 538 "BMS message for accumulator voltage.";
CM_ BO_ 539 "BMS message for accumulator voltage.";
CM_ BO_ 540 "BMS message for accumulator voltage.";
CM_ BO_ 541 "BMS message for accumulator voltage.";
CM_ BO_ 542 "BMS message for accumulator voltage.";
CM_ BO_ 543 "BMS message for accumulator voltage.";
CM_ BO_ 544 "BMS message for accumulator voltage.";
CM_ BO_ 545 "BMS message for accumulator voltage.";
CM_ BO_ 546 "BMS message for accumulator voltage.";
CM_ BO_ 547 "BMS message for accumulator voltage.";
CM_ BO_ 548 "BMS message for accumulator voltage.";
CM_ BO_ 549 "BMS message for accumulator voltage.";
CM_ BO_ 550 "BMS message for accumulator voltage.";
CM_ BO_ 551 "BMS message for accumulator voltage.";
CM_ BO_ 552 "BMS message for accumulator voltage.";
CM_ BO_ 553 "BMS message for accumulator voltage.";
CM_ BO_ 554 "BMS message for accumulator voltage.";
CM_ BO_ 555 "BMS message for accumulator voltage.";
CM_ BO_ 556 "BMS message for accumulator temperature.";
CM_ BO_ 557 "BMS message for accumulator temperature.";
CM_ BO_ 558 "BMS message for accumulator temperature.";
CM_ BO_ 559 "BMS message for accumulator temperature.";
CM_ BO_ 560 "BMS message for accumulator temperature.";
CM_ BO_ 561 "BMS message for accumulator temperature.";
CM_ BO_ 562 "BMS message for accumulator temperature.";
CM_ BO_ 563 "BMS message for accumulator temperature.";
CM_ BO_ 564 "BMS message for accumulator temperature.";
CM_ BO_ 565 "BMS message for accumulator temperature.";
CM_ BO_ 566 "BMS message for accumulator temperature.";
CM_ BO_ 567 "BMS message for accumulator temperature.";
CM_ BO_ 568 "BMS message for accumulator temperature.";
CM_ BO_ 569 "BMS message for accumulator temperature.";
CM_ BO_ 570 "BMS message for accumulator temperature.";
CM_ BO_ 571 "BMS message for accumulator temperature.";
CM_ BO_ 572 "BMS message for accumulator temperature.";
CM_ BO_ 573 "BMS message for accumulator temperature.";
CM_ BO_ 574 "BMS message for accumulator temperature.";
CM_ BO_ 575 "BMS message for accumulator temperature.";
CM_ BO_ 576 "BMS message for accumulator temperature.";
CM_ BO_ 577 "BMS message for accumulator temperature.";
CM_ BO_ 578 "BMS message for accumulator temperature.";
CM_ BO_ 579 "BMS message for accumulator temperature.";
CM_ BO_ 580 "BMS message for accumulator temperature.";
CM_ BO_ 581 "BMS message for accumulator temperature.";
CM_ BO_ 582 "BMS message for accumulator temperature.";
CM_ BO_ 583 "BMS message for accumulator temperature.";
CM_ BO_ 584 "BMS message for accumulator temperature.";
CM_ BO_ 585 "BMS message for accumulator temperature.";
CM_ BO_ 586 "BMS message for accumulator temperature.";
CM_ BO_ 587 "BMS message for accumulator temperature.";
CM_ BO_ 588 "BMS message for accumulator temperature.";
CM_ BO_ 589 "BMS message for accumulator temperature.";
CM_ BO_ 590 "BMS message for accumulator temperature.";
CM_ BO_ 591 "BMS message for accumulator temperature.";
CM_ BO_ 592 "BMS message for accumulator temperature.";
CM_ BO_ 593 "BMS message for accumulator temperature.";
CM_ BO_ 594 "BMS message for accumulator temperature.";
CM_ BO_ 595 "BMS message for accumulator temperature.";
CM_ BO_ 596 "BMS message for accumulator temperature.";
CM_ BO_ 597 "BMS message for accumulator temperature.";
CM_ BO_ 598 "BMS message for accumulator temperature.";
CM_ BO_ 599 "BMS message for accumulator temperature.";
CM_ BO_ 600 "BMS message for accumulator temperature.";
CM_ BO_ 601 "BMS message for accumulator temperature.";
CM_ BO_ 602 "BMS message for accumulator temperature.";
CM_ BO_ 603 "BMS message for accumulator temperature.";
CM_ BO_ 604 "BMS message for accumulator temperature.";
CM_ BO_ 605 "BMS message for accumulator temperature.";
CM_ BO_ 606 "BMS message for accumulator temperature.";
CM_ BO_ 607 "BMS message for accumulator temperature.";
CM_ BO_ 608 "BMS message for accumulator temperature.";
CM_ BO_ 609 "BMS message for accumulator temperature.";
CM_ BO_ 610 "BMS message for accumulator temperature.";
CM_ BO_ 611 "BMS message for accumulator temperature.";
CM_ BO_ 612 "BMS message for accumulator temperature.";
CM_ BO_ 613 "BMS message for accumulator temperature.";
CM_ BO_ 614 "BMS message for accumulator temperature.";
CM_ BO_ 615 "BMS message for accumulator temperature.";
CM_ BO_ 616 "BMS message for accumulator temperature.";
CM_ BO_ 617 "BMS message for accumulator temperature.";
CM_ BO_ 618 "BMS message for accumulator temperature.";
CM_ BO_ 619 "BMS message for accumulator temperature.";
CM_ BO_ 620 "BMS message for accumulator temperature.";
CM_ BO_ 621 "BMS message for accumulator temperature.";
CM_ BO_ 622 "BMS message for accumulator temperature.";
CM_ BO_ 623 "BMS message for accumulator temperature.";
CM_ BO_ 624 "BMS message for accumulator temperature.";
CM_ BO_ 625 "BMS message for accumulator temperature.";
CM_ BO_ 626 "BMS message for accumulator temperature.";
CM_ BO_ 627 "BMS message for accumulator temperature.";
CM_ BO_ 628 "BMS message for accumulator temperature.";
CM_ BO_ 629 "BMS message for accumulator temperature.";
CM_ BO_ 630 "BMS message for accumulator temperature.";
CM_ BO_ 631 "BMS message for accumulator temperature.";
CM_ BO_ 632 "BMS message for accumulator temperature.";
CM_ BO_ 633 "BMS message for accumulator temperature.";
CM_ BO_ 634 "BMS message for accumulator temperature.";
CM_ BO_ 635 "BMS message for accumulator temperature.";
CM_ BO_ 636 "BMS message for accumulator temperature.";
CM_ BO_ 637 "BMS message for accumulator temperature.";
CM_ BO_ 638 "BMS message for accumulator temperature.";
CM_ BO_ 639 "BMS message for accumulator temperature.";
CM_ BO_ 640 "BMS message for accumulator temperature.";
CM_ BO_ 641 "BMS message for accumulator temperature.";
CM_ BO_ 642 "BMS message for accumulator temperature.";
CM_ BO_ 643 "BMS message for accumulator temperature.";
CM_ BO_ 644 "BMS message for accumulator temperature.";
CM_ BO_ 645 "BMS message for accumulator temperature.";
CM_ BO_ 646 "BMS message for accumulator temperature.";
CM_ BO_ 647 "BMS message for accumulator temperature.";
CM_ BO_ 648 "BMS message for accumulator temperature.";
CM_ BO_ 649 "BMS message for accumulator temperature.";
CM_ BO_ 650 "BMS message for accumulator temperature.";
CM_ BO_ 651 "BMS message for accumulator temperature.";
CM_ BO_ 652 "BMS message for accumulator temperature.";
CM_ BO_ 653 "BMS message for accumulator temperature.";
CM_ BO_ 654 "BMS message for accumulator temperature.";
CM_ BO_ 655 "BMS message for accumulator temperature.";
CM_ BO_ 656 "BMS message for accumulator temperature.";
CM_ BO_ 657 "BMS message for accumulator temperature.";
CM_ BO_ 658 "BMS message for accumulator temperature.";
CM_ BO_ 659 "BMS message for accumulator temperature.";
CM_ BO_ 660 "BMS message for accumulator temperature.";
CM_ BO_ 661 "BMS message for accumulator temperature.";
CM_ BO_ 662 "BMS message for accumulator temperature.";
CM_ BO_ 663 "BMS message for accumulator temperature.";
CM_ BO_ 664 "BMS message for accumulator temperature.";
CM_ BO_ 665 "BMS message for accumulator temperature.";
CM_ BO_ 1280 "EBS Pressure Status - 4 pressure sensors (scale: 1/16, unit: bar)";
CM_ BO_ 1313 "Isabellenhutte IVT-S pack current (A, FEB sign convention).";
CM_ BO_ 1314 "Isabellenhutte IVT-S voltage 1 / pack voltage (V).";
CM_ BO_ 1315 "Isabellenhutte IVT-S voltage 2 (V).";
CM_ BO_ 1316 "Isabellenhutte IVT-S voltage 3 (V).";
CM_ BO_ 1317 "Isabellenhutte IVT-S temperature (degC).";
CM_ SG_ 2550588916 Control "Toggle charging";
CM_ SG_ 2550588916 MaxCurrent "Max Allowable Charging Current";
CM_ SG_ 2550588916 MaxVoltage "Max Allowable Charging Terminal Voltage";
CM_ SG_ 2566869221 CommunicationState "Charger communication state";
CM_ SG_ 2566869221 State "Charger starting state";
CM_ SG_ 2566869221 InputVoltage "Charger input voltage";
CM_ SG_ 2566869221 Temperature "Charger temperature";
CM_ SG_ 2566869221 HWStatus "Charger status";
CM_ SG_ 2566869221 OutputCurrent "Output Current";
CM_ SG_ 2566869221 OutputVoltage "Output Voltage";
BA_DEF_ BO_  "SystemMessageLongSymbol" STRING ;
BA_DEF_ SG_  "SystemSignalLongSymbol" STRING ;
BA_DEF_ BO_  "GenMsgCycleTime" INT 0 65535;
BA_DEF_DEF_  "SystemMessageLongSymbol" "";
BA_DEF_DEF_  "SystemSignalLongSymbol" "";
BA_DEF_DEF_  "GenMsgCycleTime" 0;
BA_ "GenMsgCycleTime" BO_ 9 20;
BA_ "SystemMessageLongSymbol" BO_ 22 "lvpdb_lv_24v_bus_and_12v_bus_voltages";
BA_ "GenMsgCycleTime" BO_ 57 100;
BA_ "GenMsgCycleTime" BO_ 160 100;
BA_ "GenMsgCycleTime" BO_ 161 100;
BA_ "GenMsgCycleTime" BO_ 162 100;
BA_ "GenMsgCycleTime" BO_ 163 10;
BA_ "GenMsgCycleTime" BO_ 164 10;
BA_ "GenMsgCycleTime" BO_ 165 10;
BA_ "GenMsgCycleTime" BO_ 166 10;
BA_ "GenMsgCycleTime" BO_ 167 10;
BA_ "GenMsgCycleTime" BO_ 168 10;
BA_ "GenMsgCycleTime" BO_ 169 100;
BA_ "GenMsgCycleTime" BO_ 170 100;
BA_ "GenMsgCycleTime" BO_ 171 100;
BA_ "GenMsgCycleTime" BO_ 172 10;
BA_ "GenMsgCycleTime" BO_ 175 3;
BA_ "GenMsgCycleTime" BO_ 176 3;
BA_ "GenMsgCycleTime" BO_ 192 5;
BA_ "SystemSignalLongSymbol" SG_ 193 VCU_INV_Parameter_Address_Comman "VCU_INV_Parameter_Address_Command";
BA_ "SystemSignalLongSymbol" SG_ 469 INV_HV_Input_Current_Sensor_Vali "INV_HV_Input_Current_Sensor_Validity";
BA_ "GenMsgCycleTime" BO_ 1280 100;
BA_ "GenMsgCycleTime" BO_ 2550588916 1000;
BA_ "GenMsgCycleTime" BO_ 2566869221 1000;
VAL_ 5 bms_state 0 "BMS_STATE_BOOT" 1 "BMS_STATE_LV_POWER" 2 "BMS_STATE_BUS_HEALTH_CHECK" 3 "BMS_STATE_PRECHARGE" 4 "BMS_STATE_ENERGIZED" 5 "BMS_STATE_DRIVE" 6 "BMS_STATE_BATTERY_FREE" 7 "BMS_STATE_CHARGER_PRECHARGE" 8 "BMS_STATE_CHARGING" 9 "BMS_STATE_BALANCE" 10 "BMS_STATE_FAULT_BMS" 11 "BMS_STATE_FAULT_BSPD" 12 "BMS_STATE_FAULT_IMD" 13 "BMS_STATE_FAULT_CHARGING" 14 "BMS_STATE_COUNT" ;
VAL_ 170 INV_Inverter_State 0 "Power up" 1 "Stop" 2 "Open Loop" 3 "Closed Loop" 4 "Internal State" 5 "Internal State" 6 "Internal State" 7 "Internal State" 8 "Idle Run" 9 "Idle Stop" 10 "Internal State" 11 "Intern State" 12 "Internal State" ;
VAL_ 170 INV_VSM_State 0 "VSM Start State" 1 "Pre-Charge Init state" 2 "pre-charge active state" 3 "pre-charge complete state" 4 "VSM wait state" 5 "VSM ready state" 6 "Motor Running State" 7 "blink fault code state" 14 "Shutdown state for Key Switch Mode 1" 15 "Reset the inverter" ;
VAL_ 2550588916 Control 1 "CHARGING_STOP" 0 "CHARGING_START" ;
VAL_ 2566869221 CommunicationState 0 "COMM_STATE_OK" 1 "COMM_STATE_TIMEOUT" ;
VAL_ 2566869221 State 0 "STATE_CHARGING" 1 "STATE_OFF" ;
VAL_ 2566869221 InputVoltage 0 "INPUT_VOLTAGE_OK" 1 "INPUT_VOLTAGE_FAULT" ;
VAL_ 2566869221 Temperature 0 "TEMP_OK" 1 "TEMP_FAULT" ;
VAL_ 2566869221 HWStatus 0 "HW_STATUS_OK" 1 "HW_STATUS_FAIL" ;
